VERSION ""

NS_ :

BS_:

BU_: CGM_HS TCM_HS RDCM_HS EPS_HS ECM_HS EBCM_HS BSM_HS BCM_HS
VAL_TABLE_ vt_BooleanValues 1 "true" 0 "false" ;
VAL_TABLE_ A6ERRAlrmReq 2 "Cancel Alarm" 1 "Set Alarm" 0 "No Action" ;
VAL_TABLE_ ValidityStates 1 "Invalid" 0 "Valid" ;

BO_ 3221225472 VECTOR__INDEPENDENT_SIG_MSG: 0 Vector__XXX
 SG_ ChgrSysAdblIndReq : 0|2@0+ (1,0) [0|3] "" Vector__XXX
 SG_ BattVltIRq : 0|2@0+ (1,0) [0|3] "" Vector__XXX

BO_ 808 Temp_Diag_CAN_Resp_HS_328: 8 Vector__XXX
 SG_ DgnInf : 7|64@0+ (1,0) [0|1.84467440737096E+019] ""  CGM_HS

BO_ 568 A_12V_System_Status_HS: 1 BSM_HS
 SG_ a_12VSysVlt : 7|8@0+ (0.125,0) [0|31.875] "volts"  CGM_HS

BO_ 49 Temp_Diag_CAN_Req_HS_031: 8 CGM_HS
 SG_ DgnInf : 7|64@0+ (1,0) [0|1.84467440737096E+019] "" Vector__XXX

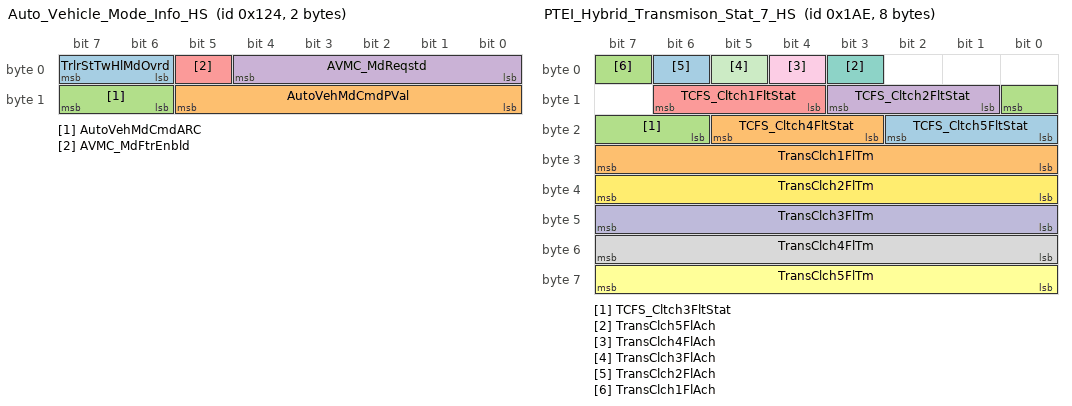
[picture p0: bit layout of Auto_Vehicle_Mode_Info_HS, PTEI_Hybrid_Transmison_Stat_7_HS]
BO_ 292 Auto_Vehicle_Mode_Info_HS: 2 CGM_HS
 SG_ TrlrStTwHlMdOvrd : 7|2@0+ (1,0) [0|3] ""  ECM_HS
 SG_ AutoVehMdCmdPVal : 13|6@0+ (1,0) [0|63] ""  ECM_HS
 SG_ AutoVehMdCmdARC : 15|2@0+ (1,0) [0|3] ""  ECM_HS
 SG_ AVMC_MdReqstd : 4|5@0+ (1,0) [0|31] ""  ECM_HS
 SG_ AVMC_MdFtrEnbld : 5|1@0+ (1,0) [0|1] ""  ECM_HS

BO_ 40 Temp_Diag_CAN_Req_HS_028: 8 CGM_HS
 SG_ DgnInf : 7|64@0+ (1,0) [0|1.84467440737096E+019] "" Vector__XXX

BO_ 1357 UUDT_Resp_From_ONS_HS: 8 CGM_HS
 SG_ DgnInf_HS54D : 7|64@0+ (1,0) [0|1.84467440737096E+019] ""  CGM_HS

BO_ 1613 USDT_Resp_From_ONS_HS: 8 CGM_HS
 SG_ DgnInf : 7|64@0+ (1,0) [0|1.84467440737096E+019] ""  CGM_HS

BO_ 2018 USDT_Req_to_TCM_MTA_MTIO_HS: 8 CGM_HS
 SG_ DgnInf : 7|64@0+ (1,0) [0|1.84467440737096E+019] ""  TCM_HS

BO_ 430 PTEI_Hybrid_Transmison_Stat_7_HS: 8 TCM_HS
 SG_ TCFS_Cltch5FltStat : 18|3@0+ (1,0) [0|7] ""  CGM_HS
 SG_ TCFS_Cltch4FltStat : 21|3@0+ (1,0) [0|7] ""  CGM_HS
 SG_ TCFS_Cltch3FltStat : 8|3@0+ (1,0) [0|7] ""  CGM_HS
 SG_ TCFS_Cltch2FltStat : 11|3@0+ (1,0) [0|7] ""  CGM_HS
 SG_ TCFS_Cltch1FltStat : 14|3@0+ (1,0) [0|7] ""  CGM_HS
 SG_ TransClch5FlTm : 63|8@0+ (0.0125,0) [0|3.1875] "s"  CGM_HS
 SG_ TransClch5FlAch : 3|1@0+ (1,0) [0|1] ""  CGM_HS
 SG_ TransClch4FlTm : 55|8@0+ (0.0125,0) [0|3.1875] "s"  CGM_HS
 SG_ TransClch4FlAch : 4|1@0+ (1,0) [0|1] ""  CGM_HS
 SG_ TransClch3FlTm : 47|8@0+ (0.0125,0) [0|3.1875] "s"  CGM_HS
 SG_ TransClch3FlAch : 5|1@0+ (1,0) [0|1] ""  CGM_HS
 SG_ TransClch2FlTm : 39|8@0+ (0.0125,0) [0|3.1875] "s"  CGM_HS
 SG_ TransClch2FlAch : 6|1@0+ (1,0) [0|1] ""  CGM_HS
 SG_ TransClch1FlTm : 31|8@0+ (0.0125,0) [0|3.1875] "s"  CGM_HS
 SG_ TransClch1FlAch : 7|1@0+ (1,0) [0|1] ""  CGM_HS

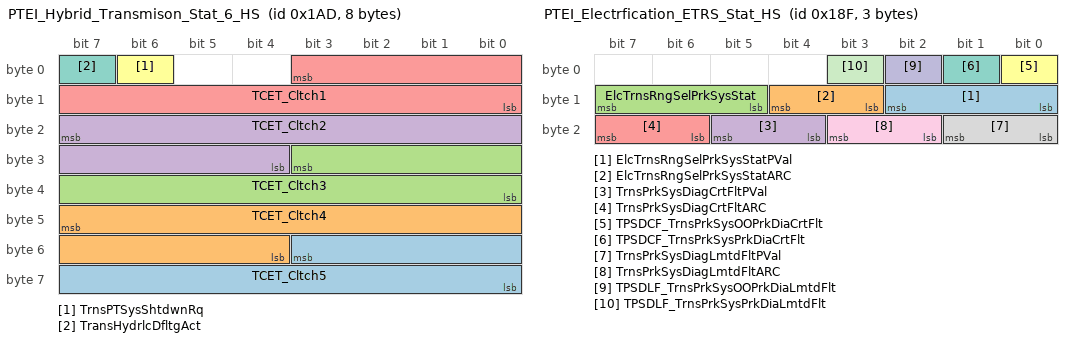
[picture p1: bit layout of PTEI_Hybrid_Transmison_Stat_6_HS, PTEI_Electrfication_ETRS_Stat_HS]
BO_ 429 PTEI_Hybrid_Transmison_Stat_6_HS: 8 TCM_HS
 SG_ TCET_Cltch5 : 51|12@0+ (0.5,-5) [-5|2042.5] "Nm"  CGM_HS
 SG_ TCET_Cltch4 : 47|12@0+ (0.5,-5) [-5|2042.5] "Nm"  CGM_HS
 SG_ TCET_Cltch3 : 27|12@0+ (0.5,-5) [-5|2042.5] "Nm"  CGM_HS
 SG_ TCET_Cltch2 : 23|12@0+ (0.5,-5) [-5|2042.5] "Nm"  CGM_HS
 SG_ TCET_Cltch1 : 3|12@0+ (0.5,-5) [-5|2042.5] "Nm"  CGM_HS
 SG_ TrnsPTSysShtdwnRq : 6|1@0+ (1,0) [0|1] ""  CGM_HS
 SG_ TransHydrlcDfltgAct : 7|1@0+ (1,0) [0|1] ""  CGM_HS

BO_ 399 PTEI_Electrfication_ETRS_Stat_HS: 3 TCM_HS
 SG_ ElcTrnsRngSelPrkSysStatPVal : 10|3@0+ (1,0) [0|7] ""  CGM_HS
 SG_ ElcTrnsRngSelPrkSysStatARC : 12|2@0+ (1,0) [0|3] ""  CGM_HS
 SG_ ElcTrnsRngSelPrkSysStat : 15|3@0+ (1,0) [0|7] ""  CGM_HS
 SG_ TrnsPrkSysDiagCrtFltPVal : 21|2@0+ (1,0) [0|3] ""  CGM_HS
 SG_ TrnsPrkSysDiagCrtFltARC : 23|2@0+ (1,0) [0|3] ""  CGM_HS
 SG_ TPSDCF_TrnsPrkSysOOPrkDiaCrtFlt : 0|1@0+ (1,0) [0|1] ""  CGM_HS
 SG_ TPSDCF_TrnsPrkSysPrkDiaCrtFlt : 1|1@0+ (1,0) [0|1] ""  CGM_HS
 SG_ TrnsPrkSysDiagLmtdFltPVal : 17|2@0+ (1,0) [0|3] ""  CGM_HS
 SG_ TrnsPrkSysDiagLmtdFltARC : 19|2@0+ (1,0) [0|3] ""  CGM_HS
 SG_ TPSDLF_TrnsPrkSysOOPrkDiaLmtdFlt : 2|1@0+ (1,0) [0|1] ""  CGM_HS
 SG_ TPSDLF_TrnsPrkSysPrkDiaLmtdFlt : 3|1@0+ (1,0) [0|1] ""  CGM_HS

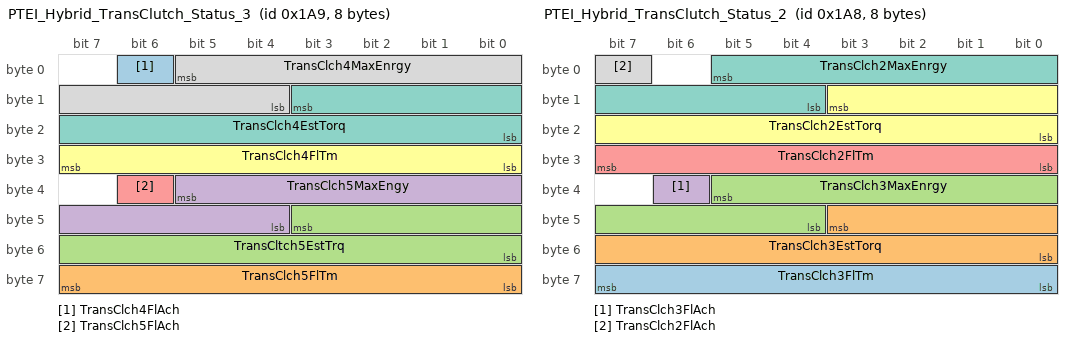
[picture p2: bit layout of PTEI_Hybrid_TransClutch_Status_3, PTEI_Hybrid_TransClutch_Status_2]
BO_ 425 PTEI_Hybrid_TransClutch_Status_3: 8 TCM_HS
 SG_ TransClch4FlAch : 6|1@0+ (1,0) [0|1] ""  CGM_HS
 SG_ TransClch5FlTm : 63|8@0+ (0.0125,0) [0|3.1875] "s"  CGM_HS
 SG_ TransCltch5EstTrq : 43|12@0+ (0.5,-5) [-5|2042.5] "Nm"  CGM_HS
 SG_ TransClch5MaxEngy : 37|10@0+ (50,0) [0|51150] "J"  CGM_HS
 SG_ TransClch5FlAch : 38|1@0+ (1,0) [0|1] ""  CGM_HS
 SG_ TransClch4FlTm : 31|8@0+ (0.0125,0) [0|3.1875] "s"  CGM_HS
 SG_ TransClch4EstTorq : 11|12@0+ (0.5,-5) [-5|2042.5] "Nm"  CGM_HS
 SG_ TransClch4MaxEnrgy : 5|10@0+ (50,0) [0|51150] "J"  CGM_HS

BO_ 424 PTEI_Hybrid_TransClutch_Status_2: 8 TCM_HS
 SG_ TransClch3FlTm : 63|8@0+ (0.0125,0) [0|3.1875] "s"  CGM_HS
 SG_ TransClch3EstTorq : 43|12@0+ (0.5,-5) [-5|2042.5] "Nm"  CGM_HS
 SG_ TransClch3MaxEnrgy : 37|10@0+ (50,0) [0|51150] "J"  CGM_HS
 SG_ TransClch3FlAch : 38|1@0+ (1,0) [0|1] ""  CGM_HS
 SG_ TransClch2FlTm : 31|8@0+ (0.0125,0) [0|3.1875] "s"  CGM_HS
 SG_ TransClch2EstTorq : 11|12@0+ (0.5,-5) [-5|2042.5] "Nm"  CGM_HS
 SG_ TransClch2MaxEnrgy : 5|10@0+ (50,0) [0|51150] "J"  CGM_HS
 SG_ TransClch2FlAch : 7|1@0+ (1,0) [0|1] ""  CGM_HS

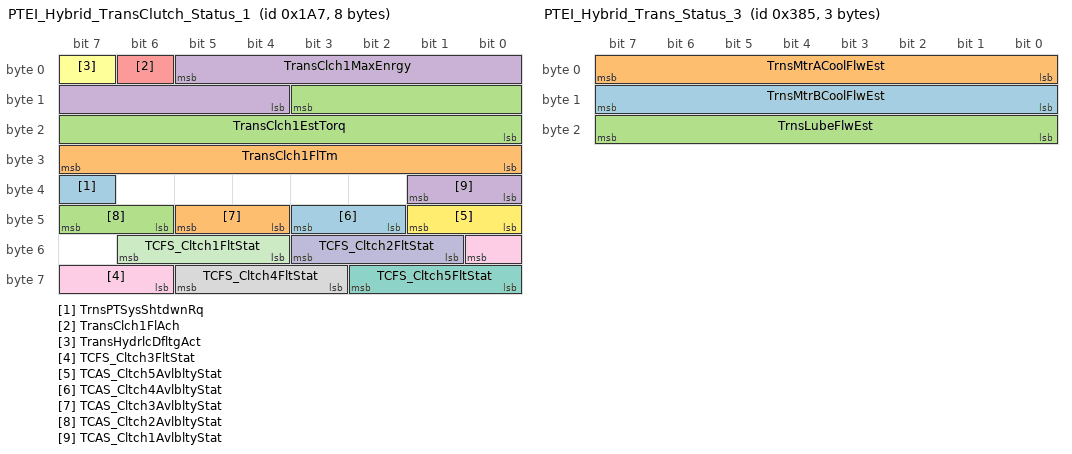
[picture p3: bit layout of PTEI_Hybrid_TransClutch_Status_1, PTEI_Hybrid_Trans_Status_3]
BO_ 423 PTEI_Hybrid_TransClutch_Status_1: 8 TCM_HS
 SG_ TrnsPTSysShtdwnRq : 39|1@0+ (1,0) [0|1] ""  CGM_HS
 SG_ TransClch1FlTm : 31|8@0+ (0.0125,0) [0|3.1875] "s"  CGM_HS
 SG_ TransClch1EstTorq : 11|12@0+ (0.5,-5) [-5|2042.5] "Nm"  CGM_HS
 SG_ TransClch1MaxEnrgy : 5|10@0+ (50,0) [0|51150] "J"  CGM_HS
 SG_ TransClch1FlAch : 6|1@0+ (1,0) [0|1] ""  CGM_HS
 SG_ TransHydrlcDfltgAct : 7|1@0+ (1,0) [0|1] ""  CGM_HS
 SG_ TCFS_Cltch5FltStat : 58|3@0+ (1,0) [0|7] ""  CGM_HS
 SG_ TCFS_Cltch4FltStat : 61|3@0+ (1,0) [0|7] ""  CGM_HS
 SG_ TCFS_Cltch3FltStat : 48|3@0+ (1,0) [0|7] ""  CGM_HS
 SG_ TCFS_Cltch2FltStat : 51|3@0+ (1,0) [0|7] ""  CGM_HS
 SG_ TCFS_Cltch1FltStat : 54|3@0+ (1,0) [0|7] ""  CGM_HS
 SG_ TCAS_Cltch5AvlbltyStat : 41|2@0+ (1,0) [0|3] ""  CGM_HS
 SG_ TCAS_Cltch4AvlbltyStat : 43|2@0+ (1,0) [0|3] ""  CGM_HS
 SG_ TCAS_Cltch3AvlbltyStat : 45|2@0+ (1,0) [0|3] ""  CGM_HS
 SG_ TCAS_Cltch2AvlbltyStat : 47|2@0+ (1,0) [0|3] ""  CGM_HS
 SG_ TCAS_Cltch1AvlbltyStat : 33|2@0+ (1,0) [0|3] ""  CGM_HS

BO_ 901 PTEI_Hybrid_Trans_Status_3: 3 TCM_HS
 SG_ TrnsMtrBCoolFlwEst : 15|8@0+ (0.05,0) [0|12.75] "l/min"  CGM_HS
 SG_ TrnsMtrACoolFlwEst : 7|8@0+ (0.05,0) [0|12.75] "l/min"  CGM_HS
 SG_ TrnsLubeFlwEst : 23|8@0+ (0.0625,0) [0|15.9375] "l/min"  CGM_HS

BO_ 1919 DTC_Triggered_77F: 7 TCM_HS
 SG_ DTCI_DTCFaultType_77F : 55|8@0+ (1,0) [0|255] ""  CGM_HS
 SG_ DTCI_CodeSupported_77F : 40|1@0+ (1,0) [0|1] ""  CGM_HS
 SG_ DTCI_CurrentStatus_77F : 41|1@0+ (1,0) [0|1] ""  CGM_HS
 SG_ DTCI_TstNPsdCdClrdSt_77F : 42|1@0+ (1,0) [0|1] ""  CGM_HS
 SG_ DTCI_TstFldCdClrdStat_77F : 43|1@0+ (1,0) [0|1] ""  CGM_HS
 SG_ DTCI_HistStat_77F : 44|1@0+ (1,0) [0|1] ""  CGM_HS
 SG_ DTCI_TstNPsdPwrUpSt_77F : 45|1@0+ (1,0) [0|1] ""  CGM_HS
 SG_ DTCI_TstFldPwrUpSt_77F : 46|1@0+ (1,0) [0|1] ""  CGM_HS
 SG_ DTCI_WrnIndRqdSt_77F : 47|1@0+ (1,0) [0|1] ""  CGM_HS
 SG_ DTCI_DTCFailType_77F : 39|8@0+ (1,0) [0|255] ""  CGM_HS
 SG_ DTCI_DTCNumber_77F : 23|16@0+ (1,0) [0|65535] ""  CGM_HS
 SG_ DTCI_DTCSource_77F : 15|8@0+ (1,0) [0|255] ""  CGM_HS
 SG_ DTCI_DTCTriggered_77F : 0|1@0+ (1,0) [0|1] ""  CGM_HS
 SG_ DTCIUnused7_77F : 1|1@0+ (1,0) [0|1] ""  CGM_HS
 SG_ DTCIUnused6_77F : 2|1@0+ (1,0) [0|1] ""  CGM_HS
 SG_ DTCIUnused5_77F : 3|1@0+ (1,0) [0|1] ""  CGM_HS
 SG_ DTCIUnused4_77F : 4|1@0+ (1,0) [0|1] ""  CGM_HS
 SG_ DTCIUnused3_77F : 5|1@0+ (1,0) [0|1] ""  CGM_HS
 SG_ DTCIUnused2_77F : 6|1@0+ (1,0) [0|1] ""  CGM_HS
 SG_ DTCIUnused1_77F : 7|1@0+ (1,0) [0|1] ""  CGM_HS

BO_ 2026 USDT_Resp_From_TCM_MTA_MTIO_HS: 8 TCM_HS
 SG_ DgnInf : 7|64@0+ (1,0) [0|1.84467440737096E+019] ""  CGM_HS

BO_ 1514 UUDT_Resp_From_TCM_MTA_MTIO_HS: 8 TCM_HS
 SG_ DgnInf : 7|64@0+ (1,0) [0|1.84467440737096E+019] ""  CGM_HS

BO_ 1801 XCP_CommandReceiveObject4_HS: 8 CGM_HS
 SG_ DgnInf : 7|64@0+ (1,0) [0|1.84467440737096E+019] ""  RDCM_HS

BO_ 591 USDT_Req_to_RDCM_HS: 8 CGM_HS
 SG_ DgnInf : 7|64@0+ (1,0) [0|1.84467440737096E+019] ""  RDCM_HS

BO_ 1799 XCP_DataTransmissionObject4_HS: 8 RDCM_HS
 SG_ DgnInf : 7|64@0+ (1,0) [0|1.84467440737096E+019] ""  CGM_HS

BO_ 1359 UUDT_Resp_From_RDCM_HS: 8 RDCM_HS
 SG_ DgnInf_HS54F : 7|64@0+ (1,0) [0|1.84467440737096E+019] ""  CGM_HS

BO_ 1914 DTC_Triggered_77A: 7 RDCM_HS
 SG_ DTCI_DTCFaultType_77A : 55|8@0+ (1,0) [0|255] ""  CGM_HS
 SG_ DTCI_CodeSupported_77A : 40|1@0+ (1,0) [0|1] ""  CGM_HS
 SG_ DTCI_CurrentStatus_77A : 41|1@0+ (1,0) [0|1] ""  CGM_HS
 SG_ DTCI_TstNPsdCdClrdSt_77A : 42|1@0+ (1,0) [0|1] ""  CGM_HS
 SG_ DTCI_TstFldCdClrdStat_77A : 43|1@0+ (1,0) [0|1] ""  CGM_HS
 SG_ DTCI_HistStat_77A : 44|1@0+ (1,0) [0|1] ""  CGM_HS
 SG_ DTCI_TstNPsdPwrUpSt_77A : 45|1@0+ (1,0) [0|1] ""  CGM_HS
 SG_ DTCI_TstFldPwrUpSt_77A : 46|1@0+ (1,0) [0|1] ""  CGM_HS
 SG_ DTCI_WrnIndRqdSt_77A : 47|1@0+ (1,0) [0|1] ""  CGM_HS
 SG_ DTCI_DTCFailType_77A : 39|8@0+ (1,0) [0|255] ""  CGM_HS
 SG_ DTCI_DTCNumber_77A : 23|16@0+ (1,0) [0|65535] ""  CGM_HS
 SG_ DTCI_DTCSource_77A : 15|8@0+ (1,0) [0|255] ""  CGM_HS
 SG_ DTCI_DTCTriggered_77A : 0|1@0+ (1,0) [0|1] ""  CGM_HS
 SG_ DTCIUnused7_77A : 1|1@0+ (1,0) [0|1] ""  CGM_HS
 SG_ DTCIUnused6_77A : 2|1@0+ (1,0) [0|1] ""  CGM_HS
 SG_ DTCIUnused5_77A : 3|1@0+ (1,0) [0|1] ""  CGM_HS
 SG_ DTCIUnused4_77A : 4|1@0+ (1,0) [0|1] ""  CGM_HS
 SG_ DTCIUnused3_77A : 5|1@0+ (1,0) [0|1] ""  CGM_HS
 SG_ DTCIUnused2_77A : 6|1@0+ (1,0) [0|1] ""  CGM_HS
 SG_ DTCIUnused1_77A : 7|1@0+ (1,0) [0|1] ""  CGM_HS

BO_ 1615 USDT_Resp_From_RDCM_HS: 8 RDCM_HS
 SG_ DgnInf : 7|64@0+ (1,0) [0|1.84467440737096E+019] ""  CGM_HS

BO_ 1800 XCP_CommandReceiveObject2_HS: 8 CGM_HS
 SG_ DgnInf : 7|64@0+ (1,0) [0|1.84467440737096E+019] ""  EPS_HS

BO_ 1810 XCP_CommandReceiveObject1_HS: 8 CGM_HS
 SG_ DgnInf : 7|64@0+ (1,0) [0|1.84467440737096E+019] ""  EPS_HS

BO_ 578 USDT_Req_to_EHPS_EPS_HS: 8 CGM_HS
 SG_ DgnInf : 7|64@0+ (1,0) [0|1.84467440737096E+019] ""  EPS_HS

BO_ 1798 XCP_DataTransmissionObject2_HS: 8 EPS_HS
 SG_ DgnInf : 7|64@0+ (1,0) [0|1.84467440737096E+019] ""  CGM_HS

BO_ 1808 XCP_DataTransmissionObject1_HS: 8 EPS_HS
 SG_ DgnInf : 7|64@0+ (1,0) [0|1.84467440737096E+019] ""  CGM_HS

BO_ 1912 DTC_Triggered_778: 7 EPS_HS
 SG_ DTCI_DTCFaultType_778 : 55|8@0+ (1,0) [0|255] ""  CGM_HS
 SG_ DTCI_CodeSupported_778 : 40|1@0+ (1,0) [0|1] ""  CGM_HS
 SG_ DTCI_CurrentStatus_778 : 41|1@0+ (1,0) [0|1] ""  CGM_HS
 SG_ DTCI_TstNPsdCdClrdSt_778 : 42|1@0+ (1,0) [0|1] ""  CGM_HS
 SG_ DTCI_TstFldCdClrdStat_778 : 43|1@0+ (1,0) [0|1] ""  CGM_HS
 SG_ DTCI_HistStat_778 : 44|1@0+ (1,0) [0|1] ""  CGM_HS
 SG_ DTCI_TstNPsdPwrUpSt_778 : 45|1@0+ (1,0) [0|1] ""  CGM_HS
 SG_ DTCI_TstFldPwrUpSt_778 : 46|1@0+ (1,0) [0|1] ""  CGM_HS
 SG_ DTCI_WrnIndRqdSt_778 : 47|1@0+ (1,0) [0|1] ""  CGM_HS
 SG_ DTCI_DTCFailType_778 : 39|8@0+ (1,0) [0|255] ""  CGM_HS
 SG_ DTCI_DTCNumber_778 : 23|16@0+ (1,0) [0|65535] ""  CGM_HS
 SG_ DTCI_DTCSource_778 : 15|8@0+ (1,0) [0|255] ""  CGM_HS
 SG_ DTCI_DTCTriggered_778 : 0|1@0+ (1,0) [0|1] ""  CGM_HS
 SG_ DTCIUnused7_778 : 1|1@0+ (1,0) [0|1] ""  CGM_HS
 SG_ DTCIUnused6_778 : 2|1@0+ (1,0) [0|1] ""  CGM_HS
 SG_ DTCIUnused5_778 : 3|1@0+ (1,0) [0|1] ""  CGM_HS
 SG_ DTCIUnused4_778 : 4|1@0+ (1,0) [0|1] ""  CGM_HS
 SG_ DTCIUnused3_778 : 5|1@0+ (1,0) [0|1] ""  CGM_HS
 SG_ DTCIUnused2_778 : 6|1@0+ (1,0) [0|1] ""  CGM_HS
 SG_ DTCIUnused1_778 : 7|1@0+ (1,0) [0|1] ""  CGM_HS

BO_ 1346 UUDT_Resp_From_EHPS_EPS_HS: 8 EPS_HS
 SG_ DgnInf_HS542 : 7|64@0+ (1,0) [0|1.84467440737096E+019] ""  CGM_HS

BO_ 1602 USDT_Resp_From_EHPS_EPS_HS: 8 EPS_HS
 SG_ DgnInf : 7|64@0+ (1,0) [0|1.84467440737096E+019] ""  CGM_HS

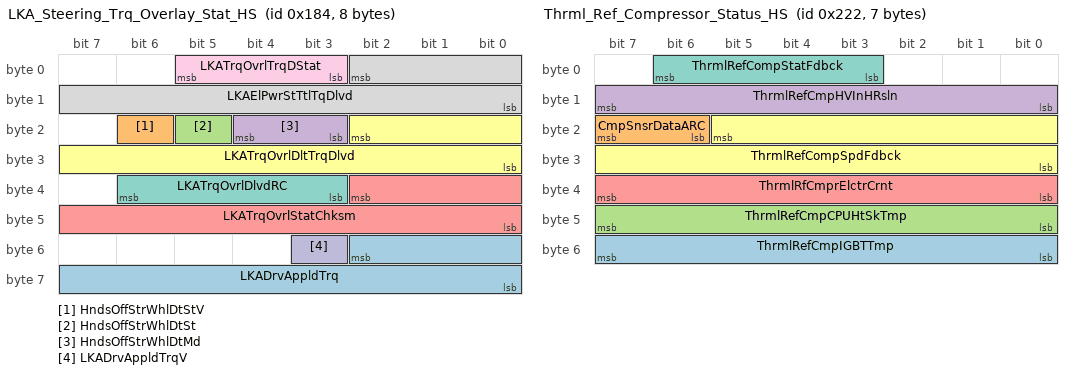
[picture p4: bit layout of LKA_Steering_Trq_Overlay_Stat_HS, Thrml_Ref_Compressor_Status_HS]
BO_ 388 LKA_Steering_Trq_Overlay_Stat_HS: 8 EPS_HS
 SG_ LKADrvAppldTrq : 50|11@0- (0.01,0) [-10.24|10.23] "Nm"  CGM_HS
 SG_ HndsOffStrWhlDtStV : 22|1@0+ (1,0) [0|1] ""  CGM_HS
 SG_ HndsOffStrWhlDtSt : 21|1@0+ (1,0) [0|1] ""  CGM_HS
 SG_ HndsOffStrWhlDtMd : 20|2@0+ (1,0) [0|3] ""  CGM_HS
 SG_ LKATrqOvrlStatChksm : 34|11@0+ (1,0) [0|2047] ""  CGM_HS
 SG_ LKATrqOvrlDltTrqDlvd : 18|11@0- (0.01,0) [-10.24|10.23] "Nm"  CGM_HS
 SG_ LKATrqOvrlDlvdRC : 38|4@0+ (1,0) [0|15] ""  CGM_HS
 SG_ LKAElPwrStTtlTqDlvd : 2|11@0- (0.01,0) [-10.24|10.23] "Nm"  CGM_HS
 SG_ LKATrqOvrlTrqDStat : 5|3@0+ (1,0) [0|7] ""  CGM_HS
 SG_ LKADrvAppldTrqV : 51|1@0+ (1,0) [0|1] ""  CGM_HS

BO_ 1611 USDT_Resp_From_EOCM_FCM_HS: 8 CGM_HS
 SG_ DgnInf : 7|64@0+ (1,0) [0|1.84467440737096E+019] ""  CGM_HS

BO_ 546 Thrml_Ref_Compressor_Status_HS: 7 Vector__XXX
 SG_ ThrmlRefCmpIGBTTmp : 55|8@0+ (1,-40) [-40|215] "deg C"  BSM_HS
 SG_ CmpSnsrDataARC : 23|2@0+ (1,0) [0|3] "N/A"  BSM_HS
 SG_ ThrmlRefCmpCPUHtSkTmp : 47|8@0+ (1,-40) [-40|215] "deg C"  BSM_HS
 SG_ ThrmlRefCmpHVInHRsln : 15|8@0+ (2.5,0) [0|637.5] "V"  BSM_HS
 SG_ ThrmlRfCmprElctrCrnt : 39|8@0+ (0.2,0) [0|51] "A"  BSM_HS
 SG_ ThrmlRefCompSpdFdbck : 21|14@0+ (1,0) [0|16383] "rpm"  BSM_HS
 SG_ ThrmlRefCompStatFdbck : 6|4@0+ (1,0) [0|15] " "  BSM_HS

BO_ 390 PTEI_Hybrid_Status_1: 7 Vector__XXX
 SG_ HybCrpCstCrvRq : 43|3@0+ (1,0) [0|7] "" Vector__XXX
 SG_ TransFldPmpMtrDrtd : 26|1@0+ (1,0) [0|1] "" Vector__XXX
 SG_ RdHVInvRatVltV : 7|1@0+ (1,0) [0|1] ""  BSM_HS
 SG_ RdHVInvRatVlt : 40|9@0+ (1,0) [0|511] "volts"  BSM_HS
 SG_ EngActDmpgDsblReq : 27|1@0+ (1,0) [0|1] "" Vector__XXX
 SG_ HybRdcdTrqCapMd1Cmnd : 5|1@0+ (1,0) [0|1] "" Vector__XXX
 SG_ HybExtndDcFuelCORq : 31|1@0+ (1,0) [0|1] "" Vector__XXX
 SG_ EstMtrPwrLossV : 30|1@0+ (1,0) [0|1] "" Vector__XXX
 SG_ EstMtrPwrLoss : 39|8@0+ (0.25,0) [0|63.75] "kW" Vector__XXX
 SG_ HybCmmFailRdPwrCmd : 4|1@0+ (1,0) [0|1] "" Vector__XXX
 SG_ HybCmmdEngTrqLmtd : 23|8@0+ (0.75,-90) [-90|101.25] "Nm" Vector__XXX
 SG_ HybACCompRq : 29|2@0+ (1,0) [0|3] "" Vector__XXX
 SG_ HybGrdBrkgAct : 25|1@0+ (1,0) [0|1] "" Vector__XXX
 SG_ HESSI_EngStrtTyp : 11|4@0+ (1,0) [0|15] ""  BSM_HS
 SG_ HESSI_EngStrtStpMd : 15|4@0+ (1,0) [0|15] ""  BSM_HS
 SG_ HybCrnkAbrtd : 0|1@0+ (1,0) [0|1] "" Vector__XXX
 SG_ CnvntlEngStrtEnbld : 1|1@0+ (1,0) [0|1] "" Vector__XXX
 SG_ HybDFCOReq : 6|1@0+ (1,0) [0|1] "" Vector__XXX
 SG_ RdPTHVCntrReq : 3|2@0+ (1,0) [0|3] ""  BSM_HS

BO_ 1355 UUDT_Resp_From_EOCM_FCM_HS: 8 CGM_HS
 SG_ DgnInf_HS54B : 7|64@0+ (1,0) [0|1.84467440737096E+019] ""  CGM_HS

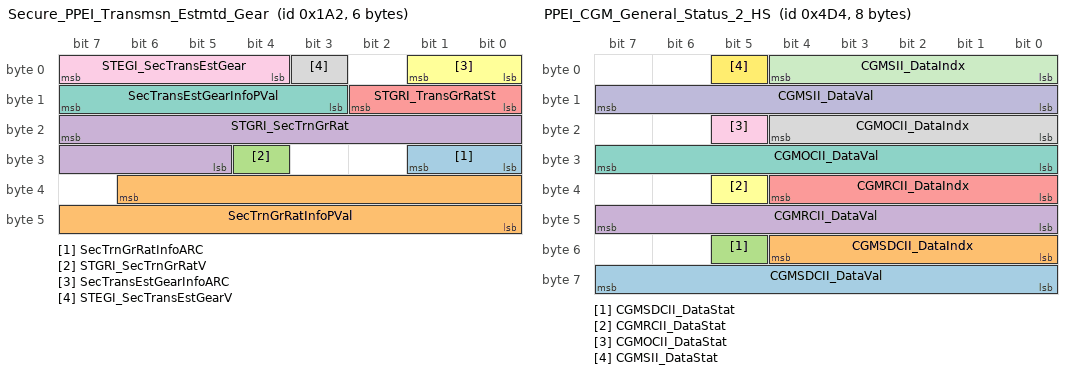
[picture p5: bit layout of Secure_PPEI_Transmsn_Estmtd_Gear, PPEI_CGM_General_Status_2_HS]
BO_ 418 Secure_PPEI_Transmsn_Estmtd_Gear: 6 TCM_HS
 SG_ SecTrnGrRatInfoARC : 25|2@0+ (1,0) [0|3] ""  CGM_HS,ECM_HS
 SG_ SecTrnGrRatInfoPVal : 38|15@0+ (1,0) [0|32767] ""  CGM_HS,ECM_HS
 SG_ STGRI_SecTrnGrRatV : 28|1@0+ (1,0) [0|1] ""  CGM_HS,ECM_HS
 SG_ STGRI_SecTrnGrRat : 23|11@0+ (0.003906,0) [0|8] ""  CGM_HS,ECM_HS
 SG_ STGRI_TransGrRatSt : 10|3@0+ (1,0) [0|7] ""  CGM_HS,ECM_HS
 SG_ SecTransEstGearInfoARC : 1|2@0+ (1,0) [0|3] ""  CGM_HS,ECM_HS
 SG_ SecTransEstGearInfoPVal : 15|5@0+ (1,0) [0|31] ""  CGM_HS,ECM_HS
 SG_ STEGI_SecTransEstGearV : 3|1@0+ (1,0) [0|1] ""  CGM_HS,ECM_HS
 SG_ STEGI_SecTransEstGear : 7|4@0+ (1,0) [0|15] ""  CGM_HS,ECM_HS

BO_ 1236 PPEI_CGM_General_Status_2_HS: 8 CGM_HS
 SG_ CGMSDCII_DataVal : 63|8@0+ (1,0) [0|255] ""  ECM_HS
 SG_ CGMSDCII_DataIndx : 52|5@0+ (1,0) [0|31] ""  ECM_HS
 SG_ CGMSDCII_DataStat : 53|1@0+ (1,0) [0|1] ""  ECM_HS
 SG_ CGMRCII_DataVal : 47|8@0+ (1,0) [0|255] ""  ECM_HS
 SG_ CGMRCII_DataIndx : 36|5@0+ (1,0) [0|31] ""  ECM_HS
 SG_ CGMRCII_DataStat : 37|1@0+ (1,0) [0|1] ""  ECM_HS
 SG_ CGMOCII_DataVal : 31|8@0+ (1,0) [0|255] ""  ECM_HS
 SG_ CGMOCII_DataIndx : 20|5@0+ (1,0) [0|31] ""  ECM_HS
 SG_ CGMOCII_DataStat : 21|1@0+ (1,0) [0|1] ""  ECM_HS
 SG_ CGMSII_DataVal : 15|8@0+ (1,0) [0|255] ""  ECM_HS
 SG_ CGMSII_DataIndx : 4|5@0+ (1,0) [0|31] ""  ECM_HS
 SG_ CGMSII_DataStat : 5|1@0+ (1,0) [0|1] ""  ECM_HS

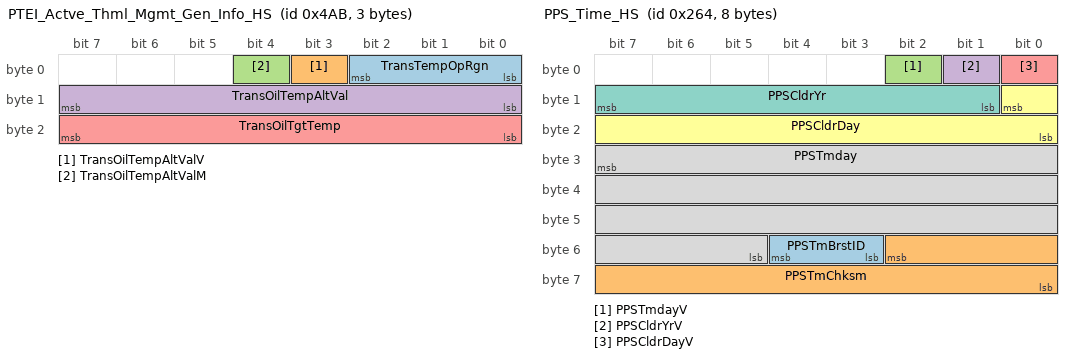
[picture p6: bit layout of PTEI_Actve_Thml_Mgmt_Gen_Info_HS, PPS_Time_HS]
BO_ 1195 PTEI_Actve_Thml_Mgmt_Gen_Info_HS: 3 TCM_HS
 SG_ TransTempOpRgn : 2|3@0+ (1,0) [0|7] ""  CGM_HS,ECM_HS
 SG_ TransOilTempAltValV : 3|1@0+ (1,0) [0|1] ""  CGM_HS,ECM_HS
 SG_ TransOilTempAltValM : 4|1@0+ (1,0) [0|1] ""  CGM_HS,ECM_HS
 SG_ TransOilTempAltVal : 15|8@0+ (1,-40) [-40|215] "deg C"  CGM_HS,ECM_HS
 SG_ TransOilTgtTemp : 23|8@0+ (1,-40) [-40|215] "deg C"  CGM_HS,ECM_HS

BO_ 612 PPS_Time_HS: 8 CGM_HS
 SG_ PPSTmBrstID : 52|2@0+ (1,0) [0|3] "" Vector__XXX
 SG_ PPSTmChksm : 50|11@0+ (1,0) [0|2047] "" Vector__XXX
 SG_ PPSTmdayV : 2|1@0+ (1,0) [0|1] ""  ECM_HS
 SG_ PPSCldrYrV : 1|1@0+ (1,0) [0|1] ""  ECM_HS
 SG_ PPSCldrDayV : 0|1@0+ (1,0) [0|1] ""  ECM_HS
 SG_ PPSCldrDay : 8|9@0+ (1,0) [0|511] ""  ECM_HS
 SG_ PPSCldrYr : 15|7@0+ (1,2014) [2014|2141] ""  ECM_HS
 SG_ PPSTmday : 31|27@0+ (1,0) [0|134217727] "ms"  ECM_HS

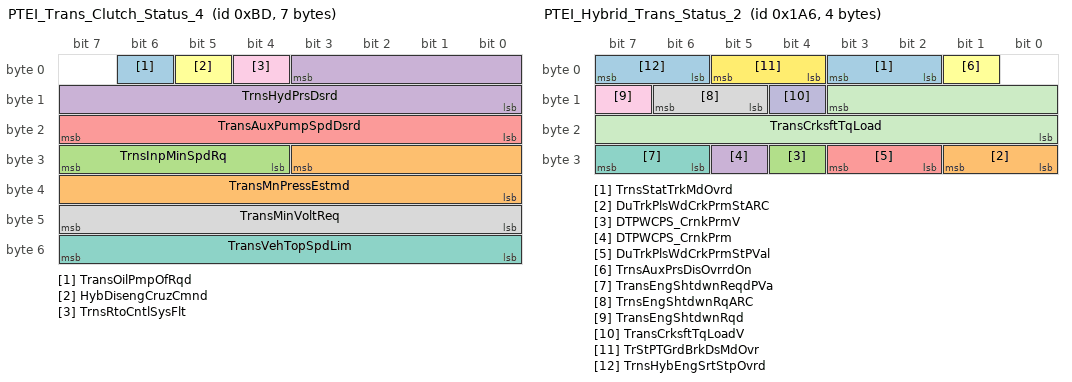
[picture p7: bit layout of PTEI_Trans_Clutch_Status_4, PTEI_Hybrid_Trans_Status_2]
BO_ 189 PTEI_Trans_Clutch_Status_4: 7 TCM_HS
 SG_ TransOilPmpOfRqd : 6|1@0+ (1,0) [0|1] ""  CGM_HS
 SG_ TransMnPressEstmd : 27|12@0+ (0.5,0) [0|2047.5] "kPa"  CGM_HS
 SG_ TrnsInpMinSpdRq : 31|4@0+ (1,0) [0|15] ""  CGM_HS
 SG_ TrnsHydPrsDsrd : 3|12@0+ (0.5,0) [0|2047.5] "kPa"  CGM_HS
 SG_ TransAuxPumpSpdDsrd : 23|8@0+ (0.392157,0) [0|100.000035] "%"  CGM_HS
 SG_ HybDisengCruzCmnd : 5|1@0+ (1,0) [0|1] ""  CGM_HS,ECM_HS
 SG_ TransVehTopSpdLim : 55|8@0+ (2,0) [0|510] "km / h"  CGM_HS,ECM_HS
 SG_ TransMinVoltReq : 47|8@0+ (0.07843,0) [0|19.99965] "volts"  CGM_HS,ECM_HS
 SG_ TrnsRtoCntlSysFlt : 4|1@0+ (1,0) [0|1] ""  CGM_HS,ECM_HS

BO_ 422 PTEI_Hybrid_Trans_Status_2: 4 TCM_HS
 SG_ TrnsStatTrkMdOvrd : 3|2@0+ (1,0) [0|3] ""  ECM_HS,CGM_HS
 SG_ DuTrkPlsWdCrkPrmStARC : 25|2@0+ (1,0) [0|3] ""  ECM_HS,CGM_HS
 SG_ DTPWCPS_CrnkPrmV : 28|1@0+ (1,0) [0|1] ""  ECM_HS,CGM_HS
 SG_ DTPWCPS_CrnkPrm : 29|1@0+ (1,0) [0|1] ""  ECM_HS,CGM_HS
 SG_ DuTrkPlsWdCrkPrmStPVal : 27|2@0+ (1,0) [0|3] ""  ECM_HS,CGM_HS
 SG_ TrnsAuxPrsDisOvrrdOn : 1|1@0+ (1,0) [0|1] ""  ECM_HS,CGM_HS
 SG_ TransEngShtdwnReqdPVa : 31|2@0+ (1,0) [0|3] ""  ECM_HS,CGM_HS
 SG_ TrnsEngShtdwnRqARC : 14|2@0+ (1,0) [0|3] ""  ECM_HS,CGM_HS
 SG_ TransEngShtdwnRqd : 15|1@0+ (1,0) [0|1] ""  ECM_HS,CGM_HS
 SG_ TransCrksftTqLoadV : 12|1@0+ (1,0) [0|1] ""  ECM_HS,CGM_HS
 SG_ TransCrksftTqLoad : 11|12@0+ (0.5,-848) [-848|1199.5] "Nm"  ECM_HS,CGM_HS
 SG_ TrStPTGrdBrkDsMdOvr : 5|2@0+ (1,0) [0|3] ""  ECM_HS,CGM_HS
 SG_ TrnsHybEngSrtStpOvrd : 7|2@0+ (1,0) [0|3] ""  ECM_HS,CGM_HS

BO_ 1189 PTEI_Trans_General_Status_3_HS: 1 TCM_HS
 SG_ TransAirFlwPrcntRq : 7|6@0+ (1.58730158730159,0) [0|100] "%"  ECM_HS,CGM_HS

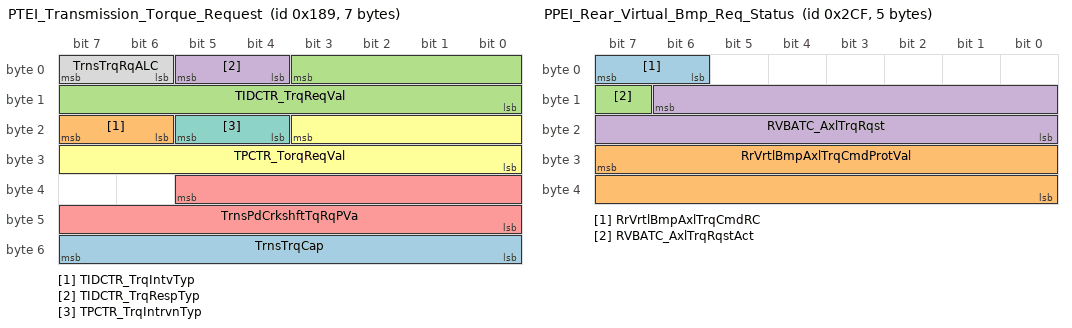
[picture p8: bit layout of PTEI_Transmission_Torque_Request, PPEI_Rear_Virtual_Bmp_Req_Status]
BO_ 393 PTEI_Transmission_Torque_Request: 7 TCM_HS
 SG_ TrnsTrqCap : 55|8@0+ (4,0) [0|1020] "Nm"  CGM_HS,ECM_HS
 SG_ TIDCTR_TrqIntvTyp : 23|2@0+ (1,0) [0|3] ""  CGM_HS,ECM_HS
 SG_ TIDCTR_TrqReqVal : 3|12@0+ (0.5,-848) [-848|1199.5] "Nm"  CGM_HS,ECM_HS
 SG_ TIDCTR_TrqRespTyp : 5|2@0+ (1,0) [0|3] ""  CGM_HS,ECM_HS
 SG_ TrnsPdCrkshftTqRqPVa : 37|14@0+ (1,0) [0|16383] ""  CGM_HS,ECM_HS
 SG_ TPCTR_TorqReqVal : 19|12@0+ (0.5,-848) [-848|1199.5] "Nm"  CGM_HS,ECM_HS
 SG_ TPCTR_TrqIntrvnTyp : 21|2@0+ (1,0) [0|3] ""  CGM_HS,ECM_HS
 SG_ TrnsTrqRqALC : 7|2@0+ (1,0) [0|3] ""  CGM_HS,ECM_HS

BO_ 719 PPEI_Rear_Virtual_Bmp_Req_Status: 5 CGM_HS
 SG_ RrVrtlBmpAxlTrqCmdRC : 7|2@0+ (1,0) [0|3] ""  ECM_HS
 SG_ RrVrtlBmpAxlTrqCmdProtVal : 31|16@0+ (1,0) [0|65535] ""  ECM_HS
 SG_ RVBATC_AxlTrqRqstAct : 15|1@0+ (1,0) [0|1] ""  ECM_HS
 SG_ RVBATC_AxlTrqRqst : 14|15@0+ (2,-22534) [-22534|43000] "NM"  ECM_HS

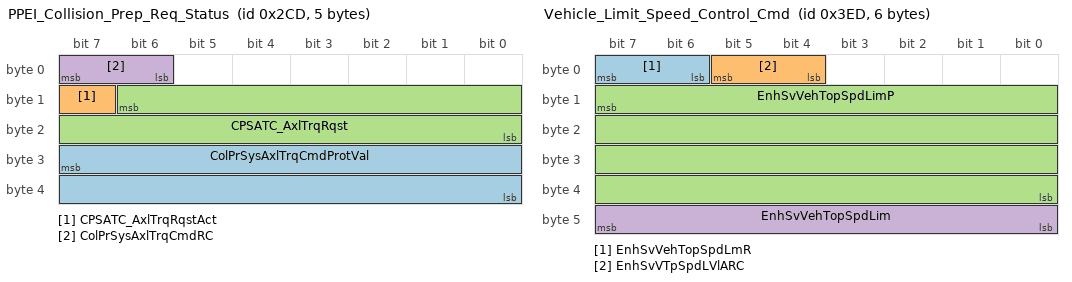
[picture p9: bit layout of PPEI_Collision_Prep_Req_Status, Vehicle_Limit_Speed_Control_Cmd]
BO_ 717 PPEI_Collision_Prep_Req_Status: 5 CGM_HS
 SG_ ColPrSysAxlTrqCmdProtVal : 31|16@0+ (1,0) [0|65535] ""  TCM_HS,ECM_HS
 SG_ CPSATC_AxlTrqRqstAct : 15|1@0+ (1,0) [0|1] ""  TCM_HS,ECM_HS
 SG_ CPSATC_AxlTrqRqst : 14|15@0+ (2,-22534) [-22534|43000] "NM"  TCM_HS,ECM_HS
 SG_ ColPrSysAxlTrqCmdRC : 7|2@0+ (1,0) [0|3] ""  TCM_HS,ECM_HS

BO_ 1005 Vehicle_Limit_Speed_Control_Cmd: 6 CGM_HS
 SG_ EnhSvVehTopSpdLmR : 7|2@0+ (1,0) [0|3] ""  ECM_HS
 SG_ EnhSvVTpSpdLVlARC : 5|2@0+ (1,0) [0|3] ""  ECM_HS
 SG_ EnhSvVehTopSpdLimP : 15|32@0+ (1,0) [0|4294967295] ""  ECM_HS
 SG_ EnhSvVehTopSpdLim : 47|8@0+ (2,0) [0|510] "km / h"  ECM_HS

BO_ 431 PTEI_Trans_General_Status_2: 8 TCM_HS
 SG_ TrnsInpCltchStatV : 39|1@0+ (1,0) [0|1] ""  CGM_HS,ECM_HS
 SG_ TransCrnkPermsnStatV : 23|1@0+ (1,0) [0|1] ""  CGM_HS,ECM_HS
 SG_ TransVehTopSpdLim : 63|8@0+ (2,0) [0|510] "km / h"  CGM_HS,ECM_HS
 SG_ TransMinVoltReq : 55|8@0+ (0.07843,0) [0|19.99965] "volts"  CGM_HS,ECM_HS
 SG_ TDslPrtFltrIdlRgtnMdAtv : 6|1@0+ (1,0) [0|1] ""  CGM_HS,ECM_HS
 SG_ DrvlneTrqStabStat : 38|3@0+ (1,0) [0|7] ""  CGM_HS,ECM_HS
 SG_ TrnsTrqCnvCltCmdMdF : 19|1@0+ (1,0) [0|1] ""  CGM_HS,ECM_HS
 SG_ AutoTransGrSftDirectFl : 16|1@0+ (1,0) [0|1] ""  CGM_HS,ECM_HS
 SG_ AutoTransGrSftDirect : 18|2@0+ (1,0) [0|3] ""  CGM_HS,ECM_HS
 SG_ TrnsTrqCnvCltCmndMd : 22|3@0+ (1,0) [0|7] ""  CGM_HS,ECM_HS
 SG_ TrnsTrqCnvCltDsrSlp : 35|12@0- (1,0) [-2048|2047] "rpm"  CGM_HS,ECM_HS
 SG_ TrnsStWntrMdOvrd : 25|2@0+ (1,0) [0|3] ""  CGM_HS,ECM_HS
 SG_ TrnsStTwHaulMdOvrd : 27|2@0+ (1,0) [0|3] ""  CGM_HS,ECM_HS
 SG_ TrnsStSprtMdOvrd : 29|2@0+ (1,0) [0|3] ""  CGM_HS,ECM_HS
 SG_ TrnsStEconMdOvrd : 31|2@0+ (1,0) [0|3] ""  CGM_HS,ECM_HS
 SG_ TrnsInpCltchStat : 2|3@0+ (1,0) [0|7] ""  CGM_HS,ECM_HS
 SG_ TrnsAntcptdCrpTrqRRnV : 7|1@0+ (1,0) [0|1] ""  CGM_HS,ECM_HS
 SG_ TrnsAntcptdCrpTrqRRn : 15|8@0+ (0.5,0) [0|127.5] "Nm"  CGM_HS,ECM_HS
 SG_ TrnCltAdpAtv : 3|1@0+ (1,0) [0|1] ""  CGM_HS,ECM_HS
 SG_ TransCrnkPermsnStat : 5|1@0+ (1,0) [0|1] ""  CGM_HS,ECM_HS
 SG_ WrmUpShftPtrn : 4|1@0+ (1,0) [0|1] ""  CGM_HS,ECM_HS

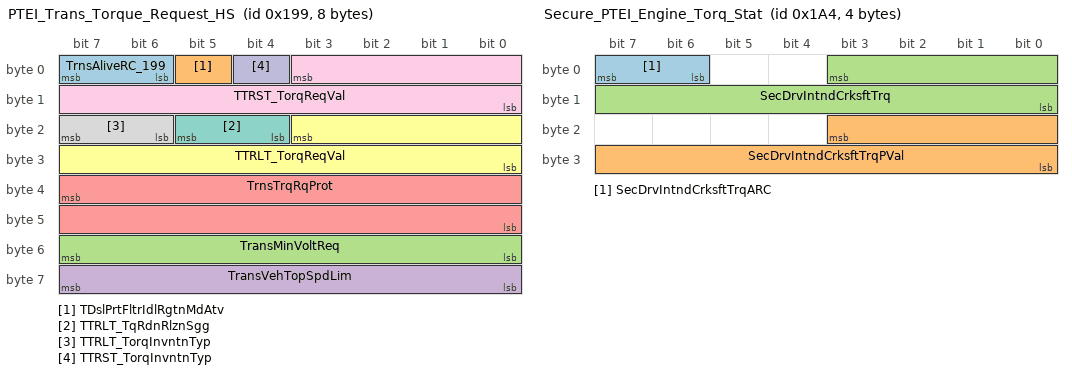
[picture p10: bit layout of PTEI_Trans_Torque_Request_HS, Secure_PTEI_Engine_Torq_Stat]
BO_ 409 PTEI_Trans_Torque_Request_HS: 8 TCM_HS
 SG_ TrnsAliveRC_199 : 7|2@0+ (1,0) [0|3] ""  CGM_HS,ECM_HS
 SG_ TDslPrtFltrIdlRgtnMdAtv : 5|1@0+ (1,0) [0|1] ""  CGM_HS,ECM_HS
 SG_ TransMinVoltReq : 55|8@0+ (0.07843,0) [0|19.99965] "volts"  CGM_HS,ECM_HS
 SG_ TransVehTopSpdLim : 63|8@0+ (2,0) [0|510] "km / h"  CGM_HS,ECM_HS
 SG_ TrnsTrqRqProt : 39|16@0+ (1,0) [0|65535] ""  CGM_HS,ECM_HS
 SG_ TTRLT_TorqReqVal : 19|12@0+ (0.5,-848) [-848|1199.5] "Nm"  CGM_HS,ECM_HS
 SG_ TTRLT_TqRdnRlznSgg : 21|2@0+ (1,0) [0|3] ""  CGM_HS,ECM_HS
 SG_ TTRLT_TorqInvntnTyp : 23|2@0+ (1,0) [0|3] ""  CGM_HS,ECM_HS
 SG_ TTRST_TorqReqVal : 3|12@0+ (0.5,-848) [-848|1199.5] "Nm"  CGM_HS,ECM_HS
 SG_ TTRST_TorqInvntnTyp : 4|1@0+ (1,0) [0|1] ""  CGM_HS,ECM_HS

BO_ 2016 USDT_Req_to_ECM_HS: 8 CGM_HS
 SG_ DgnInf : 7|64@0+ (1,0) [0|1.84467440737096E+019] ""  ECM_HS

BO_ 420 Secure_PTEI_Engine_Torq_Stat: 4 ECM_HS
 SG_ SecDrvIntndCrksftTrqARC : 7|2@0+ (1,0) [0|3] ""  CGM_HS,TCM_HS
 SG_ SecDrvIntndCrksftTrqPVal : 19|12@0+ (1,0) [0|4095] ""  CGM_HS,TCM_HS
 SG_ SecDrvIntndCrksftTrq : 3|12@0+ (0.5,-848) [-848|1199.5] "Nm"  CGM_HS,TCM_HS

BO_ 558 Air_Cmpresor_Ctrl_Data2_HS: 8 Vector__XXX
 SG_ CmpDataPktARC : 57|2@0+ (1,0) [0|3] "N/A"  BSM_HS
 SG_ CDP_HVDevShtdnCdARCSt : 49|2@0+ (1,0) [0|3] ""  BSM_HS
 SG_ CDP_CmpSpdReqARCSt : 51|2@0+ (1,0) [0|3] ""  BSM_HS
 SG_ CDP_CmpLossCommOcc : 52|1@0+ (1,0) [0|1] ""  BSM_HS
 SG_ CDP_CmpWkUp : 53|1@0+ (1,0) [0|1] ""  BSM_HS
 SG_ CDP_CmpRunCrnk : 54|1@0+ (1,0) [0|1] ""  BSM_HS
 SG_ CmpSnsrDevStPktARC : 5|2@0+ (1,0) [0|3] "N/A"  BSM_HS
 SG_ CDSP_CmpOvrTmpSt : 11|2@0+ (1,0) [0|3] ""  BSM_HS
 SG_ CDSP_CmpHVAbnrlOrVltSt : 13|2@0+ (1,0) [0|3] ""  BSM_HS
 SG_ CDSP_CmpHVUndrVltgSt : 15|2@0+ (1,0) [0|3] ""  BSM_HS
 SG_ CDSP_CmpHVOvrVltgSt : 1|2@0+ (1,0) [0|3] ""  BSM_HS
 SG_ CDSP_CmpHVOvrCrntSt : 3|2@0+ (1,0) [0|3] ""  BSM_HS
 SG_ CDSP_OvrTempWrnInd : 24|1@0+ (1,0) [0|1] ""  BSM_HS
 SG_ CDSP_CmpDgrdOp : 25|1@0+ (1,0) [0|1] ""  BSM_HS
 SG_ CDSP_CmpIntShdwnFltSt : 27|2@0+ (1,0) [0|3] ""  BSM_HS
 SG_ CDSP_CmpIntRecblFltSt : 29|2@0+ (1,0) [0|3] ""  BSM_HS
 SG_ CDSP_CmpOpOvrldSt : 31|2@0+ (1,0) [0|3] ""  BSM_HS
 SG_ CDSP_CmpDrCrctFltSt : 17|2@0+ (1,0) [0|3] ""  BSM_HS
 SG_ CDSP_CmpMtrPerfFltSt : 19|2@0+ (1,0) [0|3] ""  BSM_HS
 SG_ CDSP_CmpEEPROMFltSt : 21|2@0+ (1,0) [0|3] ""  BSM_HS
 SG_ CDSP_CmpROMFltSt : 23|2@0+ (1,0) [0|3] ""  BSM_HS
 SG_ CDSP_CmpRAMFltSt : 9|2@0+ (1,0) [0|3] ""  BSM_HS
 SG_ CmpSnsrStPktARC : 7|2@0+ (1,0) [0|3] "N/A"  BSM_HS
 SG_ CSSP_CmpIGBTTpOtRgLSt : 41|2@0+ (1,0) [0|3] ""  BSM_HS
 SG_ CSSP_CmpIGBTTpOtRgHSt : 43|2@0+ (1,0) [0|3] ""  BSM_HS
 SG_ CSSP_CmpCPUTmpOtRgLSt : 45|2@0+ (1,0) [0|3] ""  BSM_HS
 SG_ CSSP_CmpCPUTmpOtRgHSt : 47|2@0+ (1,0) [0|3] ""  BSM_HS
 SG_ CSSP_CmpHVSnsOtRgLSt : 33|2@0+ (1,0) [0|3] ""  BSM_HS
 SG_ CSSP_CmpHVSnsOtRgHSt : 35|2@0+ (1,0) [0|3] ""  BSM_HS
 SG_ CSSP_CmpPhCrntOtRgLSt : 37|2@0+ (1,0) [0|3] ""  BSM_HS
 SG_ CSSP_CmpPhCrntOtRgHSt : 39|2@0+ (1,0) [0|3] ""  BSM_HS

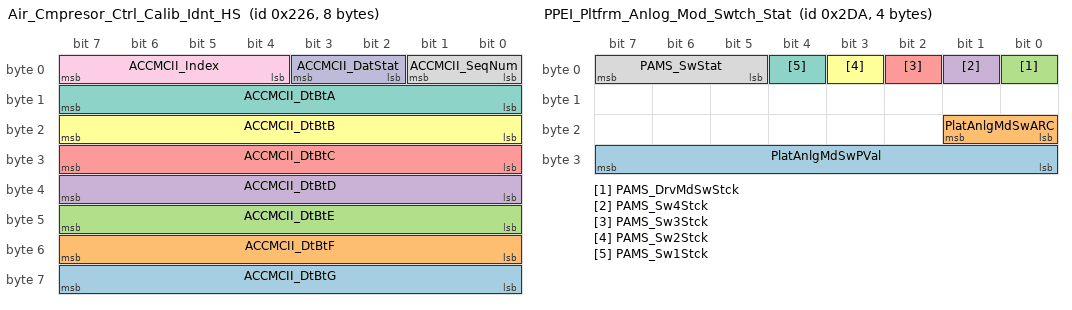
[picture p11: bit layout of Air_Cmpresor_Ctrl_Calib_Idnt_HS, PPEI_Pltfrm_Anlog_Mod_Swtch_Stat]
BO_ 550 Air_Cmpresor_Ctrl_Calib_Idnt_HS: 8 Vector__XXX
 SG_ ACCMCII_DtBtG : 63|8@0+ (1,0) [0|0] ""  BSM_HS
 SG_ ACCMCII_DtBtF : 55|8@0+ (1,0) [0|0] ""  BSM_HS
 SG_ ACCMCII_DtBtE : 47|8@0+ (1,0) [0|0] ""  BSM_HS
 SG_ ACCMCII_DtBtD : 39|8@0+ (1,0) [0|0] ""  BSM_HS
 SG_ ACCMCII_DtBtC : 31|8@0+ (1,0) [0|0] ""  BSM_HS
 SG_ ACCMCII_DtBtB : 23|8@0+ (1,0) [0|0] ""  BSM_HS
 SG_ ACCMCII_DtBtA : 15|8@0+ (1,0) [0|0] ""  BSM_HS
 SG_ ACCMCII_SeqNum : 1|2@0+ (1,0) [0|3] ""  BSM_HS
 SG_ ACCMCII_Index : 7|4@0+ (1,0) [0|15] ""  BSM_HS
 SG_ ACCMCII_DatStat : 3|2@0+ (1,0) [0|3] ""  BSM_HS

BO_ 504 PTEI_General_Status_5_HS: 2 ECM_HS
 SG_ EngCylDsrdFirngFractn : 7|8@0+ (0.00390625,0) [0|0.99609375] ""  CGM_HS,TCM_HS
 SG_ EngCylCalcFirngFractn : 15|8@0+ (0.00390625,0) [0|0.99609375] ""  CGM_HS,TCM_HS

BO_ 730 PPEI_Pltfrm_Anlog_Mod_Swtch_Stat: 4 ECM_HS
 SG_ PlatAnlgMdSwPVal : 31|8@0+ (1,0) [0|255] ""  CGM_HS
 SG_ PlatAnlgMdSwARC : 17|2@0+ (1,0) [0|3] ""  CGM_HS
 SG_ PAMS_DrvMdSwStck : 0|1@0+ (1,0) [0|1] ""  CGM_HS
 SG_ PAMS_Sw4Stck : 1|1@0+ (1,0) [0|1] ""  CGM_HS
 SG_ PAMS_Sw3Stck : 2|1@0+ (1,0) [0|1] ""  CGM_HS
 SG_ PAMS_Sw2Stck : 3|1@0+ (1,0) [0|1] ""  CGM_HS
 SG_ PAMS_Sw1Stck : 4|1@0+ (1,0) [0|1] ""  CGM_HS
 SG_ PAMS_SwStat : 7|3@0+ (1,0) [0|7] ""  CGM_HS

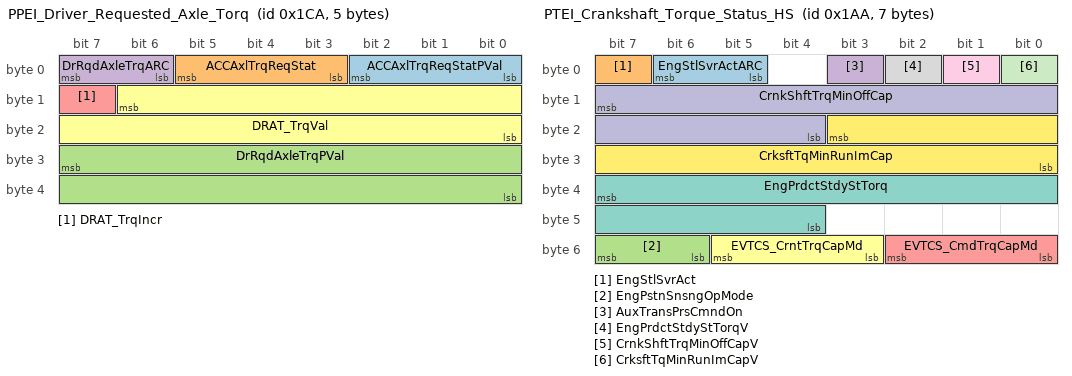
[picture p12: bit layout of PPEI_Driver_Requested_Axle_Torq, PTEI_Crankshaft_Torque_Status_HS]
BO_ 458 PPEI_Driver_Requested_Axle_Torq: 5 ECM_HS
 SG_ ACCAxlTrqReqStatPVal : 2|3@0+ (1,0) [0|7] ""  CGM_HS
 SG_ ACCAxlTrqReqStat : 5|3@0+ (1,0) [0|7] ""  CGM_HS
 SG_ DrRqdAxleTrqPVal : 31|16@0+ (1,0) [0|65535] ""  CGM_HS
 SG_ DrRqdAxleTrqARC : 7|2@0+ (1,0) [0|3] ""  CGM_HS
 SG_ DRAT_TrqIncr : 15|1@0+ (1,0) [0|1] ""  CGM_HS
 SG_ DRAT_TrqVal : 14|15@0+ (2,-22534) [-22534|43000] ""  CGM_HS

BO_ 426 PTEI_Crankshaft_Torque_Status_HS: 7 ECM_HS
 SG_ EngStlSvrActARC : 6|2@0+ (1,0) [0|3] ""  CGM_HS,TCM_HS
 SG_ EngStlSvrAct : 7|1@0+ (1,0) [0|1] ""  CGM_HS,TCM_HS
 SG_ EngPstnSnsngOpMode : 55|2@0+ (1,0) [0|3] ""  CGM_HS
 SG_ AuxTransPrsCmndOn : 3|1@0+ (1,0) [0|1] ""  CGM_HS,TCM_HS
 SG_ EVTCS_CmdTrqCapMd : 50|3@0+ (1,0) [0|7] ""  CGM_HS,TCM_HS
 SG_ EVTCS_CrntTrqCapMd : 53|3@0+ (1,0) [0|7] ""  CGM_HS,TCM_HS
 SG_ EngPrdctStdyStTorq : 39|12@0+ (0.5,-848) [-848|1199.5] "Nm"  CGM_HS,TCM_HS
 SG_ EngPrdctStdyStTorqV : 2|1@0+ (1,0) [0|1] ""  CGM_HS,TCM_HS
 SG_ CrnkShftTrqMinOffCapV : 1|1@0+ (1,0) [0|1] ""  CGM_HS,TCM_HS
 SG_ CrnkShftTrqMinOffCap : 15|12@0+ (0.5,-848) [-848|1199.5] "Nm"  CGM_HS,TCM_HS
 SG_ CrksftTqMinRunImCapV : 0|1@0+ (1,0) [0|1] ""  CGM_HS,TCM_HS
 SG_ CrksftTqMinRunImCap : 19|12@0+ (0.5,-848) [-848|1199.5] "Nm"  CGM_HS,TCM_HS

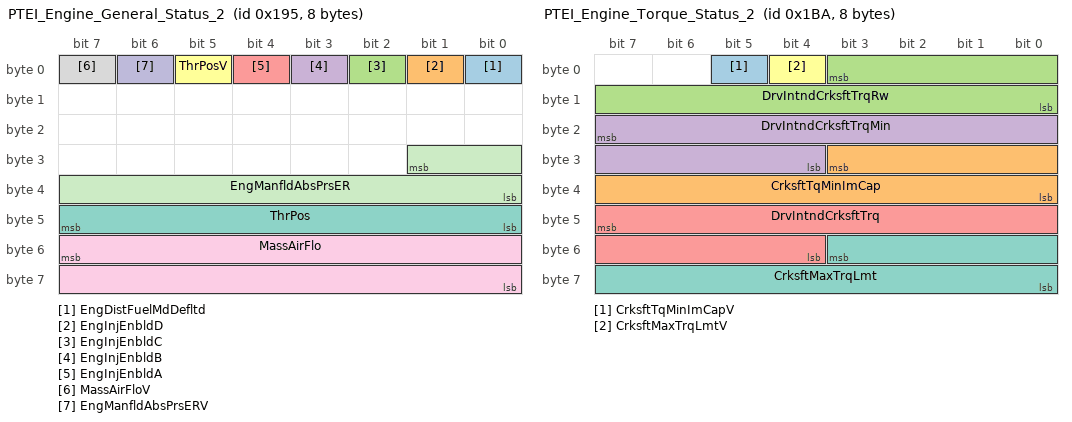
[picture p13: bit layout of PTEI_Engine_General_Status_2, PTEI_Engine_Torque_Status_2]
BO_ 405 PTEI_Engine_General_Status_2: 8 ECM_HS
 SG_ EngDistFuelMdDefltd : 0|1@0+ (1,0) [0|1] ""  CGM_HS
 SG_ EngInjEnbldD : 1|1@0+ (1,0) [0|1] ""  CGM_HS
 SG_ EngInjEnbldC : 2|1@0+ (1,0) [0|1] ""  CGM_HS
 SG_ EngInjEnbldB : 3|1@0+ (1,0) [0|1] ""  CGM_HS
 SG_ EngInjEnbldA : 4|1@0+ (1,0) [0|1] ""  CGM_HS
 SG_ ThrPosV : 5|1@0+ (1,0) [0|1] ""  CGM_HS
 SG_ ThrPos : 47|8@0+ (0.392157,0) [0|100.000035] "%"  CGM_HS
 SG_ MassAirFloV : 7|1@0+ (1,0) [0|1] ""  CGM_HS
 SG_ MassAirFlo : 55|16@0+ (0.01,0) [0|655.35] "grams/s"  CGM_HS
 SG_ EngManfldAbsPrsERV : 6|1@0+ (1,0) [0|1] ""  CGM_HS
 SG_ EngManfldAbsPrsER : 25|10@0+ (0.5,0) [0|511.5] "kPa"  CGM_HS

BO_ 442 PTEI_Engine_Torque_Status_2: 8 ECM_HS
 SG_ CrksftTqMinImCapV : 5|1@0+ (1,0) [0|1] ""  CGM_HS,TCM_HS
 SG_ CrksftTqMinImCap : 27|12@0+ (0.5,-848) [-848|1199.5] "Nm"  CGM_HS,TCM_HS
 SG_ DrvIntndCrksftTrqRw : 3|12@0+ (0.5,-848) [-848|1199.5] "Nm"  CGM_HS,TCM_HS
 SG_ DrvIntndCrksftTrqMin : 23|12@0+ (0.5,-848) [-848|1199.5] "Nm"  CGM_HS,TCM_HS
 SG_ DrvIntndCrksftTrq : 47|12@0+ (0.5,-848) [-848|1199.5] "Nm"  CGM_HS,TCM_HS
 SG_ CrksftMaxTrqLmtV : 4|1@0+ (1,0) [0|1] ""  CGM_HS,TCM_HS
 SG_ CrksftMaxTrqLmt : 51|12@0+ (0.5,-848) [-848|1199.5] "Nm"  CGM_HS,TCM_HS

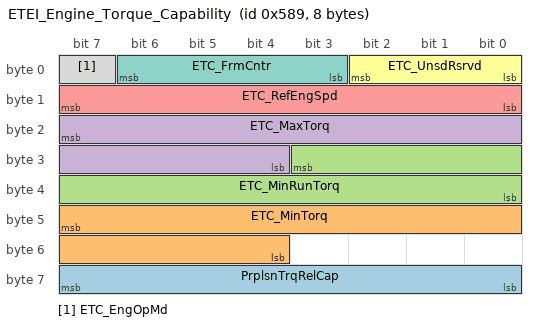
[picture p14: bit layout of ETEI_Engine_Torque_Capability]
BO_ 1417 ETEI_Engine_Torque_Capability: 8 ECM_HS
 SG_ PrplsnTrqRelCap : 63|8@0+ (0.5,0) [0|127.5] "%"  CGM_HS,TCM_HS
 SG_ ETC_MinTorq : 47|12@0+ (0.5,-848) [-848|1199.5] "Nm"  CGM_HS,TCM_HS
 SG_ ETC_MinRunTorq : 27|12@0+ (0.5,-848) [-848|1199.5] "Nm"  CGM_HS,TCM_HS
 SG_ ETC_MaxTorq : 23|12@0+ (0.5,-848) [-848|1199.5] "Nm"  CGM_HS,TCM_HS
 SG_ ETC_RefEngSpd : 15|8@0+ (32,0) [0|8160] "rpm"  CGM_HS,TCM_HS
 SG_ ETC_UnsdRsrvd : 2|3@0+ (1,0) [0|7] ""  CGM_HS,TCM_HS
 SG_ ETC_FrmCntr : 6|4@0+ (1,0) [0|15] ""  CGM_HS,TCM_HS
 SG_ ETC_EngOpMd : 7|1@0+ (1,0) [0|1] ""  CGM_HS,TCM_HS

CM_ BU_ CGM_HS "Communication Gateway";
CM_ BU_ TCM_HS "Transmission Control Module";
CM_ BU_ RDCM_HS "Rear Drive Control Module";
CM_ BU_ EPS_HS "Electronic Power Steering";
CM_ BU_ ECM_HS "Engine Control Module";
CM_ BU_ EBCM_HS "Electronic Brake Control Module";
CM_ BU_ BSM_HS "Battery State Manager";
CM_ BU_ BCM_HS "HS Side Global Architecture Gateway and Body Control Module";
CM_ BO_ 3221225472 "This is a message for not used signals, created by Vector CANdb++ DBC OLE DB Provider.";
CM_ SG_ 1919 DTCI_DTCFaultType_77F "Based on Powertrain definition.  Not expected to be supported by all devices.";
CM_ SG_ 1919 DTCI_DTCFailType_77F "Assigned per GMW3110, Appendix E";
CM_ SG_ 1919 DTCI_DTCSource_77F "This shall be equal to the Diagnostic Address of the transmittting device.";
CM_ SG_ 1914 DTCI_DTCFaultType_77A "Based on Powertrain definition.  Not expected to be supported by all devices.";
CM_ SG_ 1914 DTCI_DTCFailType_77A "Assigned per GMW3110, Appendix E";
CM_ SG_ 1914 DTCI_DTCSource_77A "This shall be equal to the Diagnostic Address of the transmittting device.";
CM_ SG_ 1912 DTCI_DTCFaultType_778 "Based on Powertrain definition.  Not expected to be supported by all devices.";
CM_ SG_ 1912 DTCI_DTCFailType_778 "Assigned per GMW3110, Appendix E";
CM_ SG_ 1912 DTCI_DTCSource_778 "This shall be equal to the Diagnostic Address of the transmittting device.";
CM_ SG_ 390 HybDFCOReq "DFCO = Deceleration Fuel Cut Off";
CM_ BO_ 719 "Application Is Tx ing this frame at the rate of 40 ms";
CM_ BO_ 717 "EOCM algorithm will transmit this message at a 40 ms periodic rate";
CM_ SG_ 1005 EnhSvVehTopSpdLimP "4 ASCII characters";
CM_ SG_ 431 TDslPrtFltrIdlRgtnMdAtv "Diesel signal could be shared with a Gasoline application";
CM_ SG_ 409 TDslPrtFltrIdlRgtnMdAtv "Diesel signal could be shared with a Gasoline application";
BA_DEF_ SG_  "GenSigSendOnInit" ENUM  "Not Initialized","Application","Handler","DLCLS","DLCHS","DLCCE","DLCFO";
BA_DEF_ SG_  "GenSigSendType" ENUM  "not used","not used","not used","not used","not used","not used","not used","NoSigSendType","not used","not used","OnAnyChange","OnChangeIfActive","OnDelta","DLCLS","DLCHS","DLCCE","DLCFO";
BA_DEF_ SG_  "GenSigDeltaValue" INT 0 0;
BA_DEF_ SG_  "VNSigAllNodes" ENUM  "No","Yes","DLCLS","DLCHS","DLCCE","DLCFO";
BA_DEF_ SG_  "VNSigSLHSSharedDiagnostic" ENUM  "No","Yes","DLCLS","DLCHS","DLCCE","DLCFO";
BA_DEF_ SG_  "VNSigSLHS_VNReq" ENUM  "No","Yes","DLCLS","DLCHS","DLCCE","DLCFO";
BA_DEF_ SG_  "SignalType" STRING ;
BA_DEF_ SG_  "PacketOrder" INT 0 65535;
BA_DEF_ SG_  "SignalLongName" STRING ;
BA_DEF_ SG_  "GenSigStartValue" INT 0 65535;
BA_DEF_ SG_  "TxSignalSendOnInit" ENUM  "Not Initialized","Application","Handler";
BA_DEF_ BO_  "GenMsgILSupport" ENUM  "No","Yes","DLCLS","DLCHS","DLCCE","DLCFO";
BA_DEF_ BO_  "AppGenMsgCycleTime" INT 0 0;
BA_DEF_ BO_  "TpApplType" STRING ;
BA_DEF_ BO_  "Prio" INT 0 7;
BA_DEF_ BO_  "MessageSubnet" ENUM  "LS","MS","HS","CE","PE","HV","FO","S1","HE","LE","HE2","DLCLS","DLCHS","DLCCE","DLCFO","vector_leerstring";
BA_DEF_ BO_  "DiagState" ENUM  "No","Yes";
BA_DEF_ BO_  "GenMsgIlSupport" ENUM  "No","Yes";
BA_DEF_ BO_  "GenMsgStartDelayTime" INT 0 100000;
BA_DEF_ BO_  "GenMsgDelayTime" INT 0 100000;
BA_DEF_ BO_  "GenMsgCycleTime" INT 0 100000;
BA_DEF_ BO_  "GenMsgSendType" ENUM  "cyclicX","spontanX","cyclicIfActiveX","spontanWithDelay","cyclicAndSpontanX","cyclicAndSpontanWithDelay","spontanWithRepitition","cyclicIfActiveAndSpontanWD";
BA_DEF_ BO_  "DiagResponse" ENUM  "No","Yes";
BA_DEF_ BO_  "DiagRequest" ENUM  "No","Yes";
BA_DEF_ BO_  "NmMessage" ENUM  "No","Yes";
BA_DEF_ BU_  "MessageManagerUsed" ENUM  "No","Yes","DLCLS","DLCHS","DLCCE","DLCFO";
BA_DEF_ BU_  "NmNode" ENUM  "No","Yes";
BA_DEF_ BU_  "ILUsed" ENUM  "No","Yes";
BA_DEF_ BU_  "FillCharacter" HEX 0 255;
BA_DEF_ BU_  "FlashSegmentSize" INT 0 256;
BA_DEF_ BU_  "NodeLayerModules" STRING ;
BA_DEF_ BU_  "VNECUSLHSSharedDiagnostic" ENUM  "None","Activator","Remoted","Activator and Remoted","Shared Local","DLCLS","DLCHS","DLCCE","DLCFO";
BA_DEF_ BU_  "VNECUSLHS_VNReq" ENUM  "None","Activator","Remoted","Activator and Remoted","Shared Local","DLCLS","DLCHS","DLCCE","DLCFO";
BA_DEF_ BU_  "VNECUAllNodes" ENUM  "None","Activator","Remoted","Activator and Remoted","Shared Local","DLCLS","DLCHS","DLCCE","DLCFO";
BA_DEF_ BU_  "ECU_Id" HEX 0 255;
BA_DEF_ BU_  "SourceId" HEX 0 253;
BA_DEF_  "VN_AllNodes" INT 0 255;
BA_DEF_  "VN_SLHSSharedDiagnostic" INT 0 255;
BA_DEF_  "VNInitActSLHSSharedDiagnostic" ENUM  "No","Yes","DLCLS","DLCHS","DLCCE","DLCFO";
BA_DEF_  "VN_SLHS_VNReq" INT 0 255;
BA_DEF_  "VNInitActSLHS_VNReq" ENUM  "No","Yes","DLCLS","DLCHS","DLCCE","DLCFO";
BA_DEF_  "VehicleArchitecture" STRING ;
BA_DEF_  "Baudrate" INT 0 1000000;
BA_DEF_  "SamplePointMin" FLOAT 0 100;
BA_DEF_  "SamplePointMax" FLOAT 0 100;
BA_DEF_  "SyncJumpWidthMin" INT 0 255;
BA_DEF_  "SyncJumpWidthMax" INT 0 255;
BA_DEF_  "VersionMonth" INT 0 255;
BA_DEF_  "BusType" STRING ;
BA_DEF_  "NmMessageCount" INT 0 32;
BA_DEF_  "NmBaseAddress" HEX 0 2032;
BA_DEF_  "NetworkType" STRING ;
BA_DEF_  "VNMFPeriodicInterval" INT 0 65535;
BA_DEF_  "BusWakeUpDelay" INT 0 65535;
BA_DEF_  "BusOffRecoveryTime" INT 0 65535;
BA_DEF_  "NodeStatusMsgID" HEX 0 536870911;
BA_DEF_  "NodeStatusMsgCycleTime" INT 0 65535;
BA_DEF_  "NodeStatusMsgTimeoutTime" INT 0 65535;
BA_DEF_  "UseGMParameterIDs" INT 0 1;
BA_DEF_  "VersionWeek" INT 0 255;
BA_DEF_  "VersionYear" INT 0 255;
BA_DEF_  "Manufacturer" ENUM  "DBAG","VAG","BMW","PAG","GM";
BA_DEF_  "NmType" STRING ;
BA_DEF_REL_ BU_SG_REL_  "GenSigSuprvResp" ENUM  "None","Notify App","Substitute Default","DLCLS","DLCHS","DLCCE","DLCFO";
BA_DEF_REL_ BU_SG_REL_  "GenSigSuprvRespSubValue" INT 0 65535;
BA_DEF_REL_ BU_SG_REL_  "GenSigRxStartValue" STRING ;
BA_DEF_REL_ BU_SG_REL_  "GenSigVDAFailResp" ENUM  "No","Yes","DLCLS","DLCHS","DLCCE","DLCFO";
BA_DEF_REL_ BU_SG_REL_  "GenSigVDAFailComment" STRING ;
BA_DEF_REL_ BU_SG_REL_  "GenSigVBitRespComment" STRING ;
BA_DEF_REL_ BU_SG_REL_  "GenSigVBitResp" ENUM  "No","Yes","DLCLS","DLCHS","DLCCE","DLCFO";
BA_DEF_REL_ BU_SG_REL_  "GenSigSuprvRespComment" STRING ;
BA_DEF_REL_ BU_SG_REL_  "GenSigTimeoutMsg" HEX 0 268435455;
BA_DEF_REL_ BU_SG_REL_  "GenSigTimeoutTime" INT 0 5000;
BA_DEF_DEF_  "GenSigSendOnInit" "Not Initialized";
BA_DEF_DEF_  "GenSigSendType" "NoSigSendType";
BA_DEF_DEF_  "GenSigDeltaValue" 0;
BA_DEF_DEF_  "VNSigAllNodes" "No";
BA_DEF_DEF_  "VNSigSLHSSharedDiagnostic" "No";
BA_DEF_DEF_  "VNSigSLHS_VNReq" "No";
BA_DEF_DEF_  "SignalType" "";
BA_DEF_DEF_  "PacketOrder" 0;
BA_DEF_DEF_  "SignalLongName" "";
BA_DEF_DEF_  "GenSigStartValue" 0;
BA_DEF_DEF_  "TxSignalSendOnInit" "Not Initialized";
BA_DEF_DEF_  "GenMsgILSupport" "Yes";
BA_DEF_DEF_  "AppGenMsgCycleTime" 0;
BA_DEF_DEF_  "TpApplType" "";
BA_DEF_DEF_  "Prio" 0;
BA_DEF_DEF_  "MessageSubnet" "LS";
BA_DEF_DEF_  "DiagState" "No";
BA_DEF_DEF_  "GenMsgIlSupport" "Yes";
BA_DEF_DEF_  "GenMsgStartDelayTime" 0;
BA_DEF_DEF_  "GenMsgDelayTime" 0;
BA_DEF_DEF_  "GenMsgCycleTime" 0;
BA_DEF_DEF_  "GenMsgSendType" "spontanX";
BA_DEF_DEF_  "DiagResponse" "No";
BA_DEF_DEF_  "DiagRequest" "No";
BA_DEF_DEF_  "NmMessage" "No";
BA_DEF_DEF_  "MessageManagerUsed" "Yes";
BA_DEF_DEF_  "NmNode" "Yes";
BA_DEF_DEF_  "ILUsed" "Yes";
BA_DEF_DEF_  "FillCharacter" 255;
BA_DEF_DEF_  "FlashSegmentSize" 8;
BA_DEF_DEF_  "NodeLayerModules" "gmlan02.dll";
BA_DEF_DEF_  "VNECUSLHSSharedDiagnostic" "None";
BA_DEF_DEF_  "VNECUSLHS_VNReq" "None";
BA_DEF_DEF_  "VNECUAllNodes" "None";
BA_DEF_DEF_  "ECU_Id" 0;
BA_DEF_DEF_  "SourceId" 0;
BA_DEF_DEF_  "VN_AllNodes" 1;
BA_DEF_DEF_  "VN_SLHSSharedDiagnostic" 0;
BA_DEF_DEF_  "VNInitActSLHSSharedDiagnostic" "No";
BA_DEF_DEF_  "VN_SLHS_VNReq" 2;
BA_DEF_DEF_  "VNInitActSLHS_VNReq" "No";
BA_DEF_DEF_  "VehicleArchitecture" "";
BA_DEF_DEF_  "Baudrate" 0;
BA_DEF_DEF_  "SamplePointMin" 0;
BA_DEF_DEF_  "SamplePointMax" 0;
BA_DEF_DEF_  "SyncJumpWidthMin" 0;
BA_DEF_DEF_  "SyncJumpWidthMax" 0;
BA_DEF_DEF_  "VersionMonth" 0;
BA_DEF_DEF_  "BusType" "";
BA_DEF_DEF_  "NmMessageCount" 32;
BA_DEF_DEF_  "NmBaseAddress" 1568;
BA_DEF_DEF_  "NetworkType" "";
BA_DEF_DEF_  "VNMFPeriodicInterval" 3000;
BA_DEF_DEF_  "BusWakeUpDelay" 100;
BA_DEF_DEF_  "BusOffRecoveryTime" 0;
BA_DEF_DEF_  "NodeStatusMsgID" 268433408;
BA_DEF_DEF_  "NodeStatusMsgCycleTime" 1200;
BA_DEF_DEF_  "NodeStatusMsgTimeoutTime" 3000;
BA_DEF_DEF_  "UseGMParameterIDs" 1;
BA_DEF_DEF_  "VersionWeek" 0;
BA_DEF_DEF_  "VersionYear" 0;
BA_DEF_DEF_  "Manufacturer" "GM";
BA_DEF_DEF_  "NmType" "GMLAN";
BA_DEF_DEF_REL_ "GenSigSuprvResp" "None";
BA_DEF_DEF_REL_ "GenSigSuprvRespSubValue" 0;
BA_DEF_DEF_REL_ "GenSigRxStartValue" "";
BA_DEF_DEF_REL_ "GenSigVDAFailResp" "No";
BA_DEF_DEF_REL_ "GenSigVDAFailComment" "";
BA_DEF_DEF_REL_ "GenSigVBitRespComment" "";
BA_DEF_DEF_REL_ "GenSigVBitResp" "No";
BA_DEF_DEF_REL_ "GenSigSuprvRespComment" "";
BA_DEF_DEF_REL_ "GenSigTimeoutMsg" 0;
BA_DEF_DEF_REL_ "GenSigTimeoutTime" 0;
BA_ "VersionYear" 19;
BA_ "VersionWeek" 41;
BA_ "UseGMParameterIDs" 0;
BA_ "NodeStatusMsgTimeoutTime" 0;
BA_ "NodeStatusMsgID" 0;
BA_ "BusOffRecoveryTime" 160;
BA_ "NetworkType" "Powertrain";
BA_ "BusType" "CAN";
BA_ "VersionMonth" 19;
BA_ "SyncJumpWidthMax" 4;
BA_ "SyncJumpWidthMin" 3;
BA_ "SamplePointMax" 81.25;
BA_ "SamplePointMin" 80;
BA_ "Baudrate" 500000;
BA_ "VehicleArchitecture" "Global A";
BA_ "VNInitActSLHS_VNReq" 1;
BA_ "VNInitActSLHSSharedDiagnostic" 1;
BA_ "SourceId" BU_ CGM_HS 69;
BA_ "ECU_Id" BU_ CGM_HS 31;
BA_ "VNECUAllNodes" BU_ CGM_HS 4;
BA_ "VNECUSLHS_VNReq" BU_ CGM_HS 4;
BA_ "VNECUSLHSSharedDiagnostic" BU_ CGM_HS 4;
BA_ "SourceId" BU_ TCM_HS 24;
BA_ "ECU_Id" BU_ TCM_HS 226;
BA_ "VNECUAllNodes" BU_ TCM_HS 4;
BA_ "VNECUSLHS_VNReq" BU_ TCM_HS 4;
BA_ "VNECUSLHSSharedDiagnostic" BU_ TCM_HS 4;
BA_ "SourceId" BU_ RDCM_HS 27;
BA_ "ECU_Id" BU_ RDCM_HS 15;
BA_ "VNECUAllNodes" BU_ RDCM_HS 4;
BA_ "VNECUSLHS_VNReq" BU_ RDCM_HS 4;
BA_ "VNECUSLHSSharedDiagnostic" BU_ RDCM_HS 4;
BA_ "SourceId" BU_ EPS_HS 49;
BA_ "ECU_Id" BU_ EPS_HS 2;
BA_ "VNECUAllNodes" BU_ EPS_HS 4;
BA_ "VNECUSLHS_VNReq" BU_ EPS_HS 4;
BA_ "VNECUSLHSSharedDiagnostic" BU_ EPS_HS 4;
BA_ "SourceId" BU_ ECM_HS 17;
BA_ "ECU_Id" BU_ ECM_HS 224;
BA_ "VNECUAllNodes" BU_ ECM_HS 4;
BA_ "VNECUSLHS_VNReq" BU_ ECM_HS 4;
BA_ "VNECUSLHSSharedDiagnostic" BU_ ECM_HS 4;
BA_ "SourceId" BU_ EBCM_HS 40;
BA_ "ECU_Id" BU_ EBCM_HS 3;
BA_ "VNECUAllNodes" BU_ EBCM_HS 4;
BA_ "VNECUSLHS_VNReq" BU_ EBCM_HS 4;
BA_ "VNECUSLHSSharedDiagnostic" BU_ EBCM_HS 4;
BA_ "SourceId" BU_ BSM_HS 203;
BA_ "ECU_Id" BU_ BSM_HS 228;
BA_ "VNECUAllNodes" BU_ BSM_HS 4;
BA_ "VNECUSLHS_VNReq" BU_ BSM_HS 4;
BA_ "VNECUSLHSSharedDiagnostic" BU_ BSM_HS 4;
BA_ "SourceId" BU_ BCM_HS 64;
BA_ "ECU_Id" BU_ BCM_HS 1;
BA_ "VNECUAllNodes" BU_ BCM_HS 4;
BA_ "VNECUSLHS_VNReq" BU_ BCM_HS 4;
BA_ "VNECUSLHSSharedDiagnostic" BU_ BCM_HS 4;
BA_ "DiagResponse" BO_ 808 1;
BA_ "MessageSubnet" BO_ 808 2;
BA_ "GenMsgSendType" BO_ 568 0;
BA_ "GenMsgCycleTime" BO_ 568 10;
BA_ "MessageSubnet" BO_ 568 2;
BA_ "DiagRequest" BO_ 49 1;
BA_ "MessageSubnet" BO_ 49 2;
BA_ "GenMsgSendType" BO_ 292 0;
BA_ "GenMsgCycleTime" BO_ 292 100;
BA_ "MessageSubnet" BO_ 292 2;
BA_ "DiagRequest" BO_ 40 1;
BA_ "MessageSubnet" BO_ 40 2;
BA_ "MessageSubnet" BO_ 1357 2;
BA_ "TpApplType" BO_ 1357 "DiagUUDTResponse";
BA_ "GenMsgILSupport" BO_ 1357 0;
BA_ "DiagResponse" BO_ 1613 1;
BA_ "MessageSubnet" BO_ 1613 2;
BA_ "DiagRequest" BO_ 2018 1;
BA_ "MessageSubnet" BO_ 2018 2;
BA_ "GenMsgSendType" BO_ 430 0;
BA_ "GenMsgCycleTime" BO_ 430 25;
BA_ "MessageSubnet" BO_ 430 2;
BA_ "GenMsgSendType" BO_ 429 0;
BA_ "GenMsgCycleTime" BO_ 429 25;
BA_ "MessageSubnet" BO_ 429 2;
BA_ "GenMsgSendType" BO_ 399 0;
BA_ "GenMsgCycleTime" BO_ 399 25;
BA_ "MessageSubnet" BO_ 399 2;
BA_ "GenMsgSendType" BO_ 425 0;
BA_ "GenMsgCycleTime" BO_ 425 25;
BA_ "MessageSubnet" BO_ 425 2;
BA_ "GenMsgSendType" BO_ 424 0;
BA_ "GenMsgCycleTime" BO_ 424 25;
BA_ "MessageSubnet" BO_ 424 2;
BA_ "GenMsgSendType" BO_ 423 0;
BA_ "GenMsgCycleTime" BO_ 423 25;
BA_ "MessageSubnet" BO_ 423 2;
BA_ "GenMsgSendType" BO_ 901 0;
BA_ "GenMsgCycleTime" BO_ 901 100;
BA_ "MessageSubnet" BO_ 901 2;
BA_ "GenMsgSendType" BO_ 1919 0;
BA_ "GenMsgCycleTime" BO_ 1919 1000;
BA_ "MessageSubnet" BO_ 1919 2;
BA_ "Prio" BO_ 1919 6;
BA_ "DiagResponse" BO_ 2026 1;
BA_ "MessageSubnet" BO_ 2026 2;
BA_ "MessageSubnet" BO_ 1514 2;
BA_ "TpApplType" BO_ 1514 "DiagUUDTResponse";
BA_ "GenMsgILSupport" BO_ 1514 0;
BA_ "MessageSubnet" BO_ 1801 2;
BA_ "DiagRequest" BO_ 591 1;
BA_ "MessageSubnet" BO_ 591 2;
BA_ "MessageSubnet" BO_ 1799 2;
BA_ "MessageSubnet" BO_ 1359 2;
BA_ "TpApplType" BO_ 1359 "DiagUUDTResponse";
BA_ "GenMsgILSupport" BO_ 1359 0;
BA_ "GenMsgSendType" BO_ 1914 0;
BA_ "GenMsgCycleTime" BO_ 1914 1000;
BA_ "MessageSubnet" BO_ 1914 2;
BA_ "Prio" BO_ 1914 6;
BA_ "DiagResponse" BO_ 1615 1;
BA_ "MessageSubnet" BO_ 1615 2;
BA_ "MessageSubnet" BO_ 1800 2;
BA_ "MessageSubnet" BO_ 1810 2;
BA_ "DiagRequest" BO_ 578 1;
BA_ "MessageSubnet" BO_ 578 2;
BA_ "MessageSubnet" BO_ 1798 2;
BA_ "MessageSubnet" BO_ 1808 2;
BA_ "GenMsgSendType" BO_ 1912 0;
BA_ "GenMsgCycleTime" BO_ 1912 1000;
BA_ "MessageSubnet" BO_ 1912 2;
BA_ "Prio" BO_ 1912 6;
BA_ "MessageSubnet" BO_ 1346 2;
BA_ "TpApplType" BO_ 1346 "DiagUUDTResponse";
BA_ "GenMsgILSupport" BO_ 1346 0;
BA_ "DiagResponse" BO_ 1602 1;
BA_ "MessageSubnet" BO_ 1602 2;
BA_ "GenMsgSendType" BO_ 388 0;
BA_ "GenMsgCycleTime" BO_ 388 100;
BA_ "MessageSubnet" BO_ 388 2;
BA_ "DiagResponse" BO_ 1611 1;
BA_ "MessageSubnet" BO_ 1611 2;
BA_ "GenMsgILSupport" BO_ 1611 0;
BA_ "GenMsgCycleTime" BO_ 546 100;
BA_ "MessageSubnet" BO_ 546 2;
BA_ "GenMsgCycleTime" BO_ 390 12;
BA_ "MessageSubnet" BO_ 390 2;
BA_ "MessageSubnet" BO_ 1355 2;
BA_ "TpApplType" BO_ 1355 "DiagUUDTResponse";
BA_ "GenMsgILSupport" BO_ 1355 0;
BA_ "GenMsgSendType" BO_ 418 0;
BA_ "GenMsgCycleTime" BO_ 418 25;
BA_ "MessageSubnet" BO_ 418 2;
BA_ "GenMsgSendType" BO_ 1236 0;
BA_ "GenMsgCycleTime" BO_ 1236 1000;
BA_ "MessageSubnet" BO_ 1236 2;
BA_ "GenMsgSendType" BO_ 1195 0;
BA_ "GenMsgCycleTime" BO_ 1195 1000;
BA_ "MessageSubnet" BO_ 1195 2;
BA_ "GenMsgSendType" BO_ 612 0;
BA_ "GenMsgCycleTime" BO_ 612 100;
BA_ "MessageSubnet" BO_ 612 2;
BA_ "GenMsgSendType" BO_ 189 0;
BA_ "GenMsgCycleTime" BO_ 189 25;
BA_ "MessageSubnet" BO_ 189 2;
BA_ "GenMsgSendType" BO_ 422 0;
BA_ "GenMsgCycleTime" BO_ 422 25;
BA_ "MessageSubnet" BO_ 422 2;
BA_ "GenMsgSendType" BO_ 1189 0;
BA_ "GenMsgCycleTime" BO_ 1189 500;
BA_ "MessageSubnet" BO_ 1189 2;
BA_ "GenMsgSendType" BO_ 393 0;
BA_ "GenMsgCycleTime" BO_ 393 25;
BA_ "MessageSubnet" BO_ 393 2;
BA_ "MessageSubnet" BO_ 719 2;
BA_ "AppGenMsgCycleTime" BO_ 719 40;
BA_ "MessageSubnet" BO_ 717 2;
BA_ "AppGenMsgCycleTime" BO_ 717 40;
BA_ "GenMsgSendType" BO_ 1005 0;
BA_ "GenMsgCycleTime" BO_ 1005 250;
BA_ "MessageSubnet" BO_ 1005 2;
BA_ "GenMsgSendType" BO_ 431 0;
BA_ "GenMsgCycleTime" BO_ 431 25;
BA_ "MessageSubnet" BO_ 431 2;
BA_ "GenMsgSendType" BO_ 409 0;
BA_ "GenMsgCycleTime" BO_ 409 25;
BA_ "MessageSubnet" BO_ 409 2;
BA_ "DiagRequest" BO_ 2016 1;
BA_ "MessageSubnet" BO_ 2016 2;
BA_ "GenMsgSendType" BO_ 420 0;
BA_ "GenMsgCycleTime" BO_ 420 25;
BA_ "MessageSubnet" BO_ 420 2;
BA_ "GenMsgCycleTime" BO_ 558 100;
BA_ "MessageSubnet" BO_ 558 2;
BA_ "GenMsgCycleTime" BO_ 550 500;
BA_ "MessageSubnet" BO_ 550 2;
BA_ "GenMsgSendType" BO_ 504 0;
BA_ "GenMsgCycleTime" BO_ 504 25;
BA_ "MessageSubnet" BO_ 504 2;
BA_ "GenMsgSendType" BO_ 730 0;
BA_ "GenMsgCycleTime" BO_ 730 50;
BA_ "MessageSubnet" BO_ 730 2;
BA_ "GenMsgSendType" BO_ 458 0;
BA_ "GenMsgCycleTime" BO_ 458 25;
BA_ "MessageSubnet" BO_ 458 2;
BA_ "GenMsgSendType" BO_ 426 0;
BA_ "GenMsgCycleTime" BO_ 426 25;
BA_ "MessageSubnet" BO_ 426 2;
BA_ "GenMsgSendType" BO_ 405 0;
BA_ "GenMsgCycleTime" BO_ 405 12;
BA_ "MessageSubnet" BO_ 405 2;
BA_ "GenMsgSendType" BO_ 442 0;
BA_ "GenMsgCycleTime" BO_ 442 25;
BA_ "MessageSubnet" BO_ 442 2;
BA_ "GenMsgSendType" BO_ 1417 0;
BA_ "GenMsgCycleTime" BO_ 1417 500;
BA_ "MessageSubnet" BO_ 1417 2;
BA_ "SignalLongName" SG_ 3221225472 ChgrSysAdblIndReq "Charger System Audible Indication Request";
BA_ "SignalType" SG_ 3221225472 ChgrSysAdblIndReq "ENM";
BA_ "VNSigAllNodes" SG_ 3221225472 ChgrSysAdblIndReq 1;
BA_ "GenSigSendType" SG_ 3221225472 ChgrSysAdblIndReq 10;
BA_ "SignalLongName" SG_ 3221225472 BattVltIRq "Battery Voltage Indication Request";
BA_ "SignalType" SG_ 3221225472 BattVltIRq "ENM";
BA_ "VNSigAllNodes" SG_ 3221225472 BattVltIRq 1;
BA_ "SignalLongName" SG_ 808 DgnInf "Diagnostic Information";
BA_ "SignalType" SG_ 808 DgnInf "UNM";
BA_ "VNSigSLHSSharedDiagnostic" SG_ 808 DgnInf 1;
BA_ "VNSigAllNodes" SG_ 808 DgnInf 1;
BA_ "GenSigDeltaValue" SG_ 808 DgnInf 1;
BA_ "GenSigSendType" SG_ 808 DgnInf 12;
BA_ "SignalLongName" SG_ 568 a_12VSysVlt "12V System Voltage";
BA_ "SignalType" SG_ 568 a_12VSysVlt "UNM";
BA_ "VNSigAllNodes" SG_ 568 a_12VSysVlt 1;
BA_ "SignalLongName" SG_ 49 DgnInf "Diagnostic Information";
BA_ "SignalType" SG_ 49 DgnInf "UNM";
BA_ "VNSigSLHSSharedDiagnostic" SG_ 49 DgnInf 1;
BA_ "VNSigAllNodes" SG_ 49 DgnInf 1;
BA_ "GenSigDeltaValue" SG_ 49 DgnInf 1;
BA_ "GenSigSendType" SG_ 49 DgnInf 12;
BA_ "SignalLongName" SG_ 292 TrlrStTwHlMdOvrd "Trailer State Tow Haul Mode Override";
BA_ "SignalType" SG_ 292 TrlrStTwHlMdOvrd "ENM";
BA_ "VNSigAllNodes" SG_ 292 TrlrStTwHlMdOvrd 1;
BA_ "SignalLongName" SG_ 292 AutoVehMdCmdPVal "Automatic Vehicle Mode Command Protection Value";
BA_ "SignalType" SG_ 292 AutoVehMdCmdPVal "UNM";
BA_ "VNSigAllNodes" SG_ 292 AutoVehMdCmdPVal 1;
BA_ "SignalLongName" SG_ 292 AutoVehMdCmdARC "Automatic Vehicle Mode Command Alive Rolling Count";
BA_ "SignalType" SG_ 292 AutoVehMdCmdARC "UNM";
BA_ "VNSigAllNodes" SG_ 292 AutoVehMdCmdARC 1;
BA_ "GenSigStartValue" SG_ 292 AVMC_MdReqstd 30;
BA_ "SignalLongName" SG_ 292 AVMC_MdReqstd "Automatic Vehicle Mode Command : Mode Requested";
BA_ "PacketOrder" SG_ 292 AVMC_MdReqstd 2;
BA_ "SignalType" SG_ 292 AVMC_MdReqstd "ENM";
BA_ "VNSigAllNodes" SG_ 292 AVMC_MdReqstd 1;
BA_ "SignalLongName" SG_ 292 AVMC_MdFtrEnbld "Automatic Vehicle Mode Command : Mode Feature Enabled";
BA_ "PacketOrder" SG_ 292 AVMC_MdFtrEnbld 1;
BA_ "SignalType" SG_ 292 AVMC_MdFtrEnbld "BLN";
BA_ "VNSigAllNodes" SG_ 292 AVMC_MdFtrEnbld 1;
BA_ "SignalLongName" SG_ 40 DgnInf "Diagnostic Information";
BA_ "SignalType" SG_ 40 DgnInf "UNM";
BA_ "VNSigSLHSSharedDiagnostic" SG_ 40 DgnInf 1;
BA_ "VNSigAllNodes" SG_ 40 DgnInf 1;
BA_ "GenSigDeltaValue" SG_ 40 DgnInf 1;
BA_ "GenSigSendType" SG_ 40 DgnInf 12;
BA_ "SignalLongName" SG_ 1357 DgnInf_HS54D "Diagnostic Information HS54D";
BA_ "SignalType" SG_ 1357 DgnInf_HS54D "UNM";
BA_ "VNSigSLHSSharedDiagnostic" SG_ 1357 DgnInf_HS54D 1;
BA_ "VNSigAllNodes" SG_ 1357 DgnInf_HS54D 1;
BA_ "GenSigDeltaValue" SG_ 1357 DgnInf_HS54D 1;
BA_ "GenSigSendType" SG_ 1357 DgnInf_HS54D 12;
BA_ "SignalLongName" SG_ 1613 DgnInf "Diagnostic Information";
BA_ "SignalType" SG_ 1613 DgnInf "UNM";
BA_ "VNSigSLHSSharedDiagnostic" SG_ 1613 DgnInf 1;
BA_ "VNSigAllNodes" SG_ 1613 DgnInf 1;
BA_ "GenSigDeltaValue" SG_ 1613 DgnInf 1;
BA_ "GenSigSendType" SG_ 1613 DgnInf 12;
BA_ "SignalLongName" SG_ 2018 DgnInf "Diagnostic Information";
BA_ "SignalType" SG_ 2018 DgnInf "UNM";
BA_ "VNSigSLHSSharedDiagnostic" SG_ 2018 DgnInf 1;
BA_ "VNSigAllNodes" SG_ 2018 DgnInf 1;
BA_ "GenSigDeltaValue" SG_ 2018 DgnInf 1;
BA_ "GenSigSendType" SG_ 2018 DgnInf 12;
BA_ "SignalLongName" SG_ 430 TCFS_Cltch5FltStat "Transmission Clutch Fault Status : Clutch 5 Fault Status";
BA_ "PacketOrder" SG_ 430 TCFS_Cltch5FltStat 5;
BA_ "SignalType" SG_ 430 TCFS_Cltch5FltStat "ENM";
BA_ "VNSigAllNodes" SG_ 430 TCFS_Cltch5FltStat 1;
BA_ "SignalLongName" SG_ 430 TCFS_Cltch4FltStat "Transmission Clutch Fault Status : Clutch 4 Fault Status";
BA_ "PacketOrder" SG_ 430 TCFS_Cltch4FltStat 4;
BA_ "SignalType" SG_ 430 TCFS_Cltch4FltStat "ENM";
BA_ "VNSigAllNodes" SG_ 430 TCFS_Cltch4FltStat 1;
BA_ "SignalLongName" SG_ 430 TCFS_Cltch3FltStat "Transmission Clutch Fault Status : Clutch 3 Fault Status";
BA_ "PacketOrder" SG_ 430 TCFS_Cltch3FltStat 3;
BA_ "SignalType" SG_ 430 TCFS_Cltch3FltStat "ENM";
BA_ "VNSigAllNodes" SG_ 430 TCFS_Cltch3FltStat 1;
BA_ "SignalLongName" SG_ 430 TCFS_Cltch2FltStat "Transmission Clutch Fault Status : Clutch 2 Fault Status";
BA_ "PacketOrder" SG_ 430 TCFS_Cltch2FltStat 2;
BA_ "SignalType" SG_ 430 TCFS_Cltch2FltStat "ENM";
BA_ "VNSigAllNodes" SG_ 430 TCFS_Cltch2FltStat 1;
BA_ "SignalLongName" SG_ 430 TCFS_Cltch1FltStat "Transmission Clutch Fault Status : Clutch 1 Fault Status";
BA_ "PacketOrder" SG_ 430 TCFS_Cltch1FltStat 1;
BA_ "SignalType" SG_ 430 TCFS_Cltch1FltStat "ENM";
BA_ "VNSigAllNodes" SG_ 430 TCFS_Cltch1FltStat 1;
BA_ "SignalLongName" SG_ 430 TransClch5FlTm "Transmission Clutch 5 Fill Time";
BA_ "SignalType" SG_ 430 TransClch5FlTm "UNM";
BA_ "VNSigAllNodes" SG_ 430 TransClch5FlTm 1;
BA_ "SignalLongName" SG_ 430 TransClch5FlAch "Transmission Clutch 5 Fill Achieved";
BA_ "SignalType" SG_ 430 TransClch5FlAch "BLN";
BA_ "VNSigAllNodes" SG_ 430 TransClch5FlAch 1;
BA_ "SignalLongName" SG_ 430 TransClch4FlTm "Transmission Clutch 4 Fill Time";
BA_ "SignalType" SG_ 430 TransClch4FlTm "UNM";
BA_ "VNSigAllNodes" SG_ 430 TransClch4FlTm 1;
BA_ "SignalLongName" SG_ 430 TransClch4FlAch "Transmission Clutch 4 Fill Achieved";
BA_ "SignalType" SG_ 430 TransClch4FlAch "BLN";
BA_ "VNSigAllNodes" SG_ 430 TransClch4FlAch 1;
BA_ "SignalLongName" SG_ 430 TransClch3FlTm "Transmission Clutch 3 Fill Time";
BA_ "SignalType" SG_ 430 TransClch3FlTm "UNM";
BA_ "VNSigAllNodes" SG_ 430 TransClch3FlTm 1;
BA_ "SignalLongName" SG_ 430 TransClch3FlAch "Transmission Clutch 3 Fill Achieved";
BA_ "SignalType" SG_ 430 TransClch3FlAch "BLN";
BA_ "VNSigAllNodes" SG_ 430 TransClch3FlAch 1;
BA_ "SignalLongName" SG_ 430 TransClch2FlTm "Transmission Clutch 2 Fill Time";
BA_ "SignalType" SG_ 430 TransClch2FlTm "UNM";
BA_ "VNSigAllNodes" SG_ 430 TransClch2FlTm 1;
BA_ "SignalLongName" SG_ 430 TransClch2FlAch "Transmission Clutch 2 Fill Achieved";
BA_ "SignalType" SG_ 430 TransClch2FlAch "BLN";
BA_ "VNSigAllNodes" SG_ 430 TransClch2FlAch 1;
BA_ "SignalLongName" SG_ 430 TransClch1FlTm "Transmission Clutch 1 Fill Time";
BA_ "SignalType" SG_ 430 TransClch1FlTm "UNM";
BA_ "VNSigAllNodes" SG_ 430 TransClch1FlTm 1;
BA_ "SignalLongName" SG_ 430 TransClch1FlAch "Transmission Clutch 1 Fill Achieved";
BA_ "SignalType" SG_ 430 TransClch1FlAch "BLN";
BA_ "VNSigAllNodes" SG_ 430 TransClch1FlAch 1;
BA_ "SignalLongName" SG_ 429 TCET_Cltch5 "Transmission Clutch Estimated Torque : Clutch 5";
BA_ "PacketOrder" SG_ 429 TCET_Cltch5 5;
BA_ "SignalType" SG_ 429 TCET_Cltch5 "UNM";
BA_ "VNSigAllNodes" SG_ 429 TCET_Cltch5 1;
BA_ "SignalLongName" SG_ 429 TCET_Cltch4 "Transmission Clutch Estimated Torque : Clutch 4";
BA_ "PacketOrder" SG_ 429 TCET_Cltch4 4;
BA_ "SignalType" SG_ 429 TCET_Cltch4 "UNM";
BA_ "VNSigAllNodes" SG_ 429 TCET_Cltch4 1;
BA_ "SignalLongName" SG_ 429 TCET_Cltch3 "Transmission Clutch Estimated Torque : Clutch 3";
BA_ "PacketOrder" SG_ 429 TCET_Cltch3 3;
BA_ "SignalType" SG_ 429 TCET_Cltch3 "UNM";
BA_ "VNSigAllNodes" SG_ 429 TCET_Cltch3 1;
BA_ "SignalLongName" SG_ 429 TCET_Cltch2 "Transmission Clutch Estimated Torque : Clutch 2";
BA_ "PacketOrder" SG_ 429 TCET_Cltch2 2;
BA_ "SignalType" SG_ 429 TCET_Cltch2 "UNM";
BA_ "VNSigAllNodes" SG_ 429 TCET_Cltch2 1;
BA_ "SignalLongName" SG_ 429 TCET_Cltch1 "Transmission Clutch Estimated Torque : Clutch 1";
BA_ "PacketOrder" SG_ 429 TCET_Cltch1 1;
BA_ "SignalType" SG_ 429 TCET_Cltch1 "UNM";
BA_ "VNSigAllNodes" SG_ 429 TCET_Cltch1 1;
BA_ "SignalLongName" SG_ 429 TrnsPTSysShtdwnRq "Transmission Powertrain System Shutdown Requested";
BA_ "SignalType" SG_ 429 TrnsPTSysShtdwnRq "BLN";
BA_ "VNSigAllNodes" SG_ 429 TrnsPTSysShtdwnRq 1;
BA_ "SignalLongName" SG_ 429 TransHydrlcDfltgAct "Transmission Hydraulic Defaulting Active";
BA_ "SignalType" SG_ 429 TransHydrlcDfltgAct "BLN";
BA_ "VNSigAllNodes" SG_ 429 TransHydrlcDfltgAct 1;
BA_ "SignalLongName" SG_ 399 ElcTrnsRngSelPrkSysStatPVal "Electronic Transmission Range Select Park System Status Protection Value";
BA_ "SignalType" SG_ 399 ElcTrnsRngSelPrkSysStatPVal "UNM";
BA_ "VNSigAllNodes" SG_ 399 ElcTrnsRngSelPrkSysStatPVal 1;
BA_ "SignalLongName" SG_ 399 ElcTrnsRngSelPrkSysStatARC "Electronic Transmission Range Select Park System Status Alive Rolling Count";
BA_ "SignalType" SG_ 399 ElcTrnsRngSelPrkSysStatARC "UNM";
BA_ "VNSigAllNodes" SG_ 399 ElcTrnsRngSelPrkSysStatARC 1;
BA_ "SignalLongName" SG_ 399 ElcTrnsRngSelPrkSysStat "Electronic Transmission Range Select Park System Status";
BA_ "SignalType" SG_ 399 ElcTrnsRngSelPrkSysStat "ENM";
BA_ "VNSigAllNodes" SG_ 399 ElcTrnsRngSelPrkSysStat 1;
BA_ "SignalLongName" SG_ 399 TrnsPrkSysDiagCrtFltPVal "Transmission Park System Diagnostic Critical Fault Protection Value";
BA_ "SignalType" SG_ 399 TrnsPrkSysDiagCrtFltPVal "UNM";
BA_ "VNSigAllNodes" SG_ 399 TrnsPrkSysDiagCrtFltPVal 1;
BA_ "SignalLongName" SG_ 399 TrnsPrkSysDiagCrtFltARC "Transmission Park System Diagnostic Critical Fault Alive Rolling Count";
BA_ "SignalType" SG_ 399 TrnsPrkSysDiagCrtFltARC "UNM";
BA_ "VNSigAllNodes" SG_ 399 TrnsPrkSysDiagCrtFltARC 1;
BA_ "SignalLongName" SG_ 399 TPSDCF_TrnsPrkSysOOPrkDiaCrtFlt "Transmission Park System Diagnostic Critical Fault : Transmission Park System Out Of Park Diagnostic Critical Fault";
BA_ "PacketOrder" SG_ 399 TPSDCF_TrnsPrkSysOOPrkDiaCrtFlt 2;
BA_ "SignalType" SG_ 399 TPSDCF_TrnsPrkSysOOPrkDiaCrtFlt "BLN";
BA_ "VNSigAllNodes" SG_ 399 TPSDCF_TrnsPrkSysOOPrkDiaCrtFlt 1;
BA_ "SignalLongName" SG_ 399 TPSDCF_TrnsPrkSysPrkDiaCrtFlt "Transmission Park System Diagnostic Critical Fault : Transmission Park System Park Diagnostic Critical Fault";
BA_ "PacketOrder" SG_ 399 TPSDCF_TrnsPrkSysPrkDiaCrtFlt 1;
BA_ "SignalType" SG_ 399 TPSDCF_TrnsPrkSysPrkDiaCrtFlt "BLN";
BA_ "VNSigAllNodes" SG_ 399 TPSDCF_TrnsPrkSysPrkDiaCrtFlt 1;
BA_ "SignalLongName" SG_ 399 TrnsPrkSysDiagLmtdFltPVal "Transmission Park System Diagnostic Limited Fault Protection Value";
BA_ "SignalType" SG_ 399 TrnsPrkSysDiagLmtdFltPVal "UNM";
BA_ "VNSigAllNodes" SG_ 399 TrnsPrkSysDiagLmtdFltPVal 1;
BA_ "SignalLongName" SG_ 399 TrnsPrkSysDiagLmtdFltARC "Transmission Park System Diagnostic Limited Fault Alive Rolling Count";
BA_ "SignalType" SG_ 399 TrnsPrkSysDiagLmtdFltARC "UNM";
BA_ "VNSigAllNodes" SG_ 399 TrnsPrkSysDiagLmtdFltARC 1;
BA_ "SignalLongName" SG_ 399 TPSDLF_TrnsPrkSysOOPrkDiaLmtdFlt "Transmission Park System Diagnostic Limited Fault : Transmission Park System Out Of Park Diagnostic Limited Fault";
BA_ "PacketOrder" SG_ 399 TPSDLF_TrnsPrkSysOOPrkDiaLmtdFlt 2;
BA_ "SignalType" SG_ 399 TPSDLF_TrnsPrkSysOOPrkDiaLmtdFlt "BLN";
BA_ "VNSigAllNodes" SG_ 399 TPSDLF_TrnsPrkSysOOPrkDiaLmtdFlt 1;
BA_ "SignalLongName" SG_ 399 TPSDLF_TrnsPrkSysPrkDiaLmtdFlt "Transmission Park System Diagnostic Limited Fault : Transmission Park System Park Diagnostic Limited Fault";
BA_ "PacketOrder" SG_ 399 TPSDLF_TrnsPrkSysPrkDiaLmtdFlt 1;
BA_ "SignalType" SG_ 399 TPSDLF_TrnsPrkSysPrkDiaLmtdFlt "BLN";
BA_ "VNSigAllNodes" SG_ 399 TPSDLF_TrnsPrkSysPrkDiaLmtdFlt 1;
BA_ "SignalLongName" SG_ 425 TransClch4FlAch "Transmission Clutch 4 Fill Achieved";
BA_ "SignalType" SG_ 425 TransClch4FlAch "BLN";
BA_ "VNSigAllNodes" SG_ 425 TransClch4FlAch 1;
BA_ "SignalLongName" SG_ 425 TransClch5FlTm "Transmission Clutch 5 Fill Time";
BA_ "SignalType" SG_ 425 TransClch5FlTm "UNM";
BA_ "VNSigAllNodes" SG_ 425 TransClch5FlTm 1;
BA_ "SignalLongName" SG_ 425 TransCltch5EstTrq "Transmission Clutch 5 Estimated Torque";
BA_ "SignalType" SG_ 425 TransCltch5EstTrq "UNM";
BA_ "VNSigAllNodes" SG_ 425 TransCltch5EstTrq 1;
BA_ "SignalLongName" SG_ 425 TransClch5MaxEngy "Transmission Clutch 5 Maximum Energy";
BA_ "SignalType" SG_ 425 TransClch5MaxEngy "UNM";
BA_ "VNSigAllNodes" SG_ 425 TransClch5MaxEngy 1;
BA_ "SignalLongName" SG_ 425 TransClch5FlAch "Transmission Clutch 5 Fill Achieved";
BA_ "SignalType" SG_ 425 TransClch5FlAch "BLN";
BA_ "VNSigAllNodes" SG_ 425 TransClch5FlAch 1;
BA_ "SignalLongName" SG_ 425 TransClch4FlTm "Transmission Clutch 4 Fill Time";
BA_ "SignalType" SG_ 425 TransClch4FlTm "UNM";
BA_ "VNSigAllNodes" SG_ 425 TransClch4FlTm 1;
BA_ "SignalLongName" SG_ 425 TransClch4EstTorq "Transmission Clutch 4 Estimated Torque";
BA_ "SignalType" SG_ 425 TransClch4EstTorq "UNM";
BA_ "VNSigAllNodes" SG_ 425 TransClch4EstTorq 1;
BA_ "SignalLongName" SG_ 425 TransClch4MaxEnrgy "Transmission Clutch 4 Maximum Energy";
BA_ "SignalType" SG_ 425 TransClch4MaxEnrgy "UNM";
BA_ "VNSigAllNodes" SG_ 425 TransClch4MaxEnrgy 1;
BA_ "SignalLongName" SG_ 424 TransClch3FlTm "Transmission Clutch 3 Fill Time";
BA_ "SignalType" SG_ 424 TransClch3FlTm "UNM";
BA_ "VNSigAllNodes" SG_ 424 TransClch3FlTm 1;
BA_ "SignalLongName" SG_ 424 TransClch3EstTorq "Transmission Clutch 3 Estimated Torque";
BA_ "SignalType" SG_ 424 TransClch3EstTorq "UNM";
BA_ "VNSigAllNodes" SG_ 424 TransClch3EstTorq 1;
BA_ "SignalLongName" SG_ 424 TransClch3MaxEnrgy "Transmission Clutch 3 Maximum Energy";
BA_ "SignalType" SG_ 424 TransClch3MaxEnrgy "UNM";
BA_ "VNSigAllNodes" SG_ 424 TransClch3MaxEnrgy 1;
BA_ "SignalLongName" SG_ 424 TransClch3FlAch "Transmission Clutch 3 Fill Achieved";
BA_ "SignalType" SG_ 424 TransClch3FlAch "BLN";
BA_ "VNSigAllNodes" SG_ 424 TransClch3FlAch 1;
BA_ "SignalLongName" SG_ 424 TransClch2FlTm "Transmission Clutch 2 Fill Time";
BA_ "SignalType" SG_ 424 TransClch2FlTm "UNM";
BA_ "VNSigAllNodes" SG_ 424 TransClch2FlTm 1;
BA_ "SignalLongName" SG_ 424 TransClch2EstTorq "Transmission Clutch 2 Estimated Torque";
BA_ "SignalType" SG_ 424 TransClch2EstTorq "UNM";
BA_ "VNSigAllNodes" SG_ 424 TransClch2EstTorq 1;
BA_ "SignalLongName" SG_ 424 TransClch2MaxEnrgy "Transmission Clutch 2 Maximum Energy";
BA_ "SignalType" SG_ 424 TransClch2MaxEnrgy "UNM";
BA_ "VNSigAllNodes" SG_ 424 TransClch2MaxEnrgy 1;
BA_ "SignalLongName" SG_ 424 TransClch2FlAch "Transmission Clutch 2 Fill Achieved";
BA_ "SignalType" SG_ 424 TransClch2FlAch "BLN";
BA_ "VNSigAllNodes" SG_ 424 TransClch2FlAch 1;
BA_ "SignalLongName" SG_ 423 TrnsPTSysShtdwnRq "Transmission Powertrain System Shutdown Requested";
BA_ "SignalType" SG_ 423 TrnsPTSysShtdwnRq "BLN";
BA_ "VNSigAllNodes" SG_ 423 TrnsPTSysShtdwnRq 1;
BA_ "SignalLongName" SG_ 423 TransClch1FlTm "Transmission Clutch 1 Fill Time";
BA_ "SignalType" SG_ 423 TransClch1FlTm "UNM";
BA_ "VNSigAllNodes" SG_ 423 TransClch1FlTm 1;
BA_ "SignalLongName" SG_ 423 TransClch1EstTorq "Transmission Clutch 1 Estimated Torque";
BA_ "SignalType" SG_ 423 TransClch1EstTorq "UNM";
BA_ "VNSigAllNodes" SG_ 423 TransClch1EstTorq 1;
BA_ "SignalLongName" SG_ 423 TransClch1MaxEnrgy "Transmission Clutch 1 Maximum Energy";
BA_ "SignalType" SG_ 423 TransClch1MaxEnrgy "UNM";
BA_ "VNSigAllNodes" SG_ 423 TransClch1MaxEnrgy 1;
BA_ "SignalLongName" SG_ 423 TransClch1FlAch "Transmission Clutch 1 Fill Achieved";
BA_ "SignalType" SG_ 423 TransClch1FlAch "BLN";
BA_ "VNSigAllNodes" SG_ 423 TransClch1FlAch 1;
BA_ "SignalLongName" SG_ 423 TransHydrlcDfltgAct "Transmission Hydraulic Defaulting Active";
BA_ "SignalType" SG_ 423 TransHydrlcDfltgAct "BLN";
BA_ "VNSigAllNodes" SG_ 423 TransHydrlcDfltgAct 1;
BA_ "SignalLongName" SG_ 423 TCFS_Cltch5FltStat "Transmission Clutch Fault Status : Clutch 5 Fault Status";
BA_ "PacketOrder" SG_ 423 TCFS_Cltch5FltStat 5;
BA_ "SignalType" SG_ 423 TCFS_Cltch5FltStat "ENM";
BA_ "VNSigAllNodes" SG_ 423 TCFS_Cltch5FltStat 1;
BA_ "SignalLongName" SG_ 423 TCFS_Cltch4FltStat "Transmission Clutch Fault Status : Clutch 4 Fault Status";
BA_ "PacketOrder" SG_ 423 TCFS_Cltch4FltStat 4;
BA_ "SignalType" SG_ 423 TCFS_Cltch4FltStat "ENM";
BA_ "VNSigAllNodes" SG_ 423 TCFS_Cltch4FltStat 1;
BA_ "SignalLongName" SG_ 423 TCFS_Cltch3FltStat "Transmission Clutch Fault Status : Clutch 3 Fault Status";
BA_ "PacketOrder" SG_ 423 TCFS_Cltch3FltStat 3;
BA_ "SignalType" SG_ 423 TCFS_Cltch3FltStat "ENM";
BA_ "VNSigAllNodes" SG_ 423 TCFS_Cltch3FltStat 1;
BA_ "SignalLongName" SG_ 423 TCFS_Cltch2FltStat "Transmission Clutch Fault Status : Clutch 2 Fault Status";
BA_ "PacketOrder" SG_ 423 TCFS_Cltch2FltStat 2;
BA_ "SignalType" SG_ 423 TCFS_Cltch2FltStat "ENM";
BA_ "VNSigAllNodes" SG_ 423 TCFS_Cltch2FltStat 1;
BA_ "SignalLongName" SG_ 423 TCFS_Cltch1FltStat "Transmission Clutch Fault Status : Clutch 1 Fault Status";
BA_ "PacketOrder" SG_ 423 TCFS_Cltch1FltStat 1;
BA_ "SignalType" SG_ 423 TCFS_Cltch1FltStat "ENM";
BA_ "VNSigAllNodes" SG_ 423 TCFS_Cltch1FltStat 1;
BA_ "SignalLongName" SG_ 423 TCAS_Cltch5AvlbltyStat "Transmission Clutch Availability Status : Clutch 5 Availability Status";
BA_ "PacketOrder" SG_ 423 TCAS_Cltch5AvlbltyStat 5;
BA_ "SignalType" SG_ 423 TCAS_Cltch5AvlbltyStat "ENM";
BA_ "VNSigAllNodes" SG_ 423 TCAS_Cltch5AvlbltyStat 1;
BA_ "SignalLongName" SG_ 423 TCAS_Cltch4AvlbltyStat "Transmission Clutch Availability Status : Clutch 4 Availability Status";
BA_ "PacketOrder" SG_ 423 TCAS_Cltch4AvlbltyStat 4;
BA_ "SignalType" SG_ 423 TCAS_Cltch4AvlbltyStat "ENM";
BA_ "VNSigAllNodes" SG_ 423 TCAS_Cltch4AvlbltyStat 1;
BA_ "SignalLongName" SG_ 423 TCAS_Cltch3AvlbltyStat "Transmission Clutch Availability Status : Clutch 3 Availability Status";
BA_ "PacketOrder" SG_ 423 TCAS_Cltch3AvlbltyStat 3;
BA_ "SignalType" SG_ 423 TCAS_Cltch3AvlbltyStat "ENM";
BA_ "VNSigAllNodes" SG_ 423 TCAS_Cltch3AvlbltyStat 1;
BA_ "SignalLongName" SG_ 423 TCAS_Cltch2AvlbltyStat "Transmission Clutch Availability Status : Clutch 2 Availability Status";
BA_ "PacketOrder" SG_ 423 TCAS_Cltch2AvlbltyStat 2;
BA_ "SignalType" SG_ 423 TCAS_Cltch2AvlbltyStat "ENM";
BA_ "VNSigAllNodes" SG_ 423 TCAS_Cltch2AvlbltyStat 1;
BA_ "SignalLongName" SG_ 423 TCAS_Cltch1AvlbltyStat "Transmission Clutch Availability Status : Clutch 1 Availability Status";
BA_ "PacketOrder" SG_ 423 TCAS_Cltch1AvlbltyStat 1;
BA_ "SignalType" SG_ 423 TCAS_Cltch1AvlbltyStat "ENM";
BA_ "VNSigAllNodes" SG_ 423 TCAS_Cltch1AvlbltyStat 1;
BA_ "SignalLongName" SG_ 901 TrnsMtrBCoolFlwEst "Transmission Motor B Cooling Flow Estimated";
BA_ "SignalType" SG_ 901 TrnsMtrBCoolFlwEst "UNM";
BA_ "VNSigAllNodes" SG_ 901 TrnsMtrBCoolFlwEst 1;
BA_ "SignalLongName" SG_ 901 TrnsMtrACoolFlwEst "Transmission Motor A Cooling Flow Estimated";
BA_ "SignalType" SG_ 901 TrnsMtrACoolFlwEst "UNM";
BA_ "VNSigAllNodes" SG_ 901 TrnsMtrACoolFlwEst 1;
BA_ "SignalLongName" SG_ 901 TrnsLubeFlwEst "Transmission Lube Flow Estimated";
BA_ "SignalType" SG_ 901 TrnsLubeFlwEst "UNM";
BA_ "VNSigAllNodes" SG_ 901 TrnsLubeFlwEst 1;
BA_ "SignalLongName" SG_ 1919 DTCI_DTCFaultType_77F "Diagnostic Trouble Code Information Extended 77F : Diagnostic Trouble Code Fault Type";
BA_ "PacketOrder" SG_ 1919 DTCI_DTCFaultType_77F 20;
BA_ "SignalType" SG_ 1919 DTCI_DTCFaultType_77F "ENM";
BA_ "VNSigAllNodes" SG_ 1919 DTCI_DTCFaultType_77F 1;
BA_ "SignalLongName" SG_ 1919 DTCI_CodeSupported_77F "Diagnostic Trouble Code Information Extended 77F : Code Supported";
BA_ "PacketOrder" SG_ 1919 DTCI_CodeSupported_77F 19;
BA_ "SignalType" SG_ 1919 DTCI_CodeSupported_77F "BLN";
BA_ "VNSigAllNodes" SG_ 1919 DTCI_CodeSupported_77F 1;
BA_ "SignalLongName" SG_ 1919 DTCI_CurrentStatus_77F "Diagnostic Trouble Code Information Extended 77F : Current Status";
BA_ "PacketOrder" SG_ 1919 DTCI_CurrentStatus_77F 18;
BA_ "SignalType" SG_ 1919 DTCI_CurrentStatus_77F "BLN";
BA_ "VNSigAllNodes" SG_ 1919 DTCI_CurrentStatus_77F 1;
BA_ "SignalLongName" SG_ 1919 DTCI_TstNPsdCdClrdSt_77F "Diagnostic Trouble Code Information Extended 77F : Test Not Passed Since Code Cleared Status";
BA_ "PacketOrder" SG_ 1919 DTCI_TstNPsdCdClrdSt_77F 17;
BA_ "SignalType" SG_ 1919 DTCI_TstNPsdCdClrdSt_77F "BLN";
BA_ "VNSigAllNodes" SG_ 1919 DTCI_TstNPsdCdClrdSt_77F 1;
BA_ "SignalLongName" SG_ 1919 DTCI_TstFldCdClrdStat_77F "Diagnostic Trouble Code Information Extended 77F : Test Failed Since Code Cleared Status";
BA_ "PacketOrder" SG_ 1919 DTCI_TstFldCdClrdStat_77F 16;
BA_ "SignalType" SG_ 1919 DTCI_TstFldCdClrdStat_77F "BLN";
BA_ "VNSigAllNodes" SG_ 1919 DTCI_TstFldCdClrdStat_77F 1;
BA_ "SignalLongName" SG_ 1919 DTCI_HistStat_77F "Diagnostic Trouble Code Information Extended 77F : History Status";
BA_ "PacketOrder" SG_ 1919 DTCI_HistStat_77F 15;
BA_ "SignalType" SG_ 1919 DTCI_HistStat_77F "BLN";
BA_ "VNSigAllNodes" SG_ 1919 DTCI_HistStat_77F 1;
BA_ "SignalLongName" SG_ 1919 DTCI_TstNPsdPwrUpSt_77F "Diagnostic Trouble Code Information Extended 77F : Test Not Passed Since Power Up Status";
BA_ "PacketOrder" SG_ 1919 DTCI_TstNPsdPwrUpSt_77F 14;
BA_ "SignalType" SG_ 1919 DTCI_TstNPsdPwrUpSt_77F "BLN";
BA_ "VNSigAllNodes" SG_ 1919 DTCI_TstNPsdPwrUpSt_77F 1;
BA_ "SignalLongName" SG_ 1919 DTCI_TstFldPwrUpSt_77F "Diagnostic Trouble Code Information Extended 77F : Test Failed Since Power Up Status";
BA_ "PacketOrder" SG_ 1919 DTCI_TstFldPwrUpSt_77F 13;
BA_ "SignalType" SG_ 1919 DTCI_TstFldPwrUpSt_77F "BLN";
BA_ "VNSigAllNodes" SG_ 1919 DTCI_TstFldPwrUpSt_77F 1;
BA_ "SignalLongName" SG_ 1919 DTCI_WrnIndRqdSt_77F "Diagnostic Trouble Code Information Extended 77F : Warning Indicator Requested Status";
BA_ "PacketOrder" SG_ 1919 DTCI_WrnIndRqdSt_77F 12;
BA_ "SignalType" SG_ 1919 DTCI_WrnIndRqdSt_77F "BLN";
BA_ "VNSigAllNodes" SG_ 1919 DTCI_WrnIndRqdSt_77F 1;
BA_ "SignalLongName" SG_ 1919 DTCI_DTCFailType_77F "Diagnostic Trouble Code Information Extended 77F : Diagnostic Trouble Code Failure Type";
BA_ "PacketOrder" SG_ 1919 DTCI_DTCFailType_77F 11;
BA_ "SignalType" SG_ 1919 DTCI_DTCFailType_77F "UNM";
BA_ "VNSigAllNodes" SG_ 1919 DTCI_DTCFailType_77F 1;
BA_ "SignalLongName" SG_ 1919 DTCI_DTCNumber_77F "Diagnostic Trouble Code Information Extended 77F : Diagnostic Trouble Code Number";
BA_ "PacketOrder" SG_ 1919 DTCI_DTCNumber_77F 10;
BA_ "SignalType" SG_ 1919 DTCI_DTCNumber_77F "UNM";
BA_ "VNSigAllNodes" SG_ 1919 DTCI_DTCNumber_77F 1;
BA_ "SignalLongName" SG_ 1919 DTCI_DTCSource_77F "Diagnostic Trouble Code Information Extended 77F : Diagnostic Trouble Code Source";
BA_ "PacketOrder" SG_ 1919 DTCI_DTCSource_77F 9;
BA_ "SignalType" SG_ 1919 DTCI_DTCSource_77F "UNM";
BA_ "VNSigAllNodes" SG_ 1919 DTCI_DTCSource_77F 1;
BA_ "SignalLongName" SG_ 1919 DTCI_DTCTriggered_77F "Diagnostic Trouble Code Information Extended 77F : Diagnostic Trouble Code Triggered";
BA_ "PacketOrder" SG_ 1919 DTCI_DTCTriggered_77F 8;
BA_ "SignalType" SG_ 1919 DTCI_DTCTriggered_77F "BLN";
BA_ "VNSigAllNodes" SG_ 1919 DTCI_DTCTriggered_77F 1;
BA_ "SignalLongName" SG_ 1919 DTCIUnused7_77F "Diagnostic Trouble Code Information Extended 77F : Unused 7";
BA_ "PacketOrder" SG_ 1919 DTCIUnused7_77F 7;
BA_ "SignalType" SG_ 1919 DTCIUnused7_77F "BLN";
BA_ "VNSigAllNodes" SG_ 1919 DTCIUnused7_77F 1;
BA_ "SignalLongName" SG_ 1919 DTCIUnused6_77F "Diagnostic Trouble Code Information Extended 77F : Unused 6";
BA_ "PacketOrder" SG_ 1919 DTCIUnused6_77F 6;
BA_ "SignalType" SG_ 1919 DTCIUnused6_77F "BLN";
BA_ "VNSigAllNodes" SG_ 1919 DTCIUnused6_77F 1;
BA_ "SignalLongName" SG_ 1919 DTCIUnused5_77F "Diagnostic Trouble Code Information Extended 77F : Unused 5";
BA_ "PacketOrder" SG_ 1919 DTCIUnused5_77F 5;
BA_ "SignalType" SG_ 1919 DTCIUnused5_77F "BLN";
BA_ "VNSigAllNodes" SG_ 1919 DTCIUnused5_77F 1;
BA_ "SignalLongName" SG_ 1919 DTCIUnused4_77F "Diagnostic Trouble Code Information Extended 77F : Unused 4";
BA_ "PacketOrder" SG_ 1919 DTCIUnused4_77F 4;
BA_ "SignalType" SG_ 1919 DTCIUnused4_77F "BLN";
BA_ "VNSigAllNodes" SG_ 1919 DTCIUnused4_77F 1;
BA_ "SignalLongName" SG_ 1919 DTCIUnused3_77F "Diagnostic Trouble Code Information Extended 77F : Unused 3";
BA_ "PacketOrder" SG_ 1919 DTCIUnused3_77F 3;
BA_ "SignalType" SG_ 1919 DTCIUnused3_77F "BLN";
BA_ "VNSigAllNodes" SG_ 1919 DTCIUnused3_77F 1;
BA_ "SignalLongName" SG_ 1919 DTCIUnused2_77F "Diagnostic Trouble Code Information Extended 77F : Unused 2";
BA_ "PacketOrder" SG_ 1919 DTCIUnused2_77F 2;
BA_ "SignalType" SG_ 1919 DTCIUnused2_77F "BLN";
BA_ "VNSigAllNodes" SG_ 1919 DTCIUnused2_77F 1;
BA_ "SignalLongName" SG_ 1919 DTCIUnused1_77F "Diagnostic Trouble Code Information Extended 77F : Unused 1";
BA_ "PacketOrder" SG_ 1919 DTCIUnused1_77F 1;
BA_ "SignalType" SG_ 1919 DTCIUnused1_77F "BLN";
BA_ "VNSigAllNodes" SG_ 1919 DTCIUnused1_77F 1;
BA_ "SignalLongName" SG_ 2026 DgnInf "Diagnostic Information";
BA_ "SignalType" SG_ 2026 DgnInf "UNM";
BA_ "VNSigSLHSSharedDiagnostic" SG_ 2026 DgnInf 1;
BA_ "VNSigAllNodes" SG_ 2026 DgnInf 1;
BA_ "GenSigDeltaValue" SG_ 2026 DgnInf 1;
BA_ "GenSigSendType" SG_ 2026 DgnInf 12;
BA_ "SignalLongName" SG_ 1514 DgnInf "Diagnostic Information";
BA_ "SignalType" SG_ 1514 DgnInf "UNM";
BA_ "VNSigSLHSSharedDiagnostic" SG_ 1514 DgnInf 1;
BA_ "VNSigAllNodes" SG_ 1514 DgnInf 1;
BA_ "GenSigDeltaValue" SG_ 1514 DgnInf 1;
BA_ "GenSigSendType" SG_ 1514 DgnInf 12;
BA_ "SignalLongName" SG_ 1801 DgnInf "Diagnostic Information";
BA_ "SignalType" SG_ 1801 DgnInf "UNM";
BA_ "VNSigSLHSSharedDiagnostic" SG_ 1801 DgnInf 1;
BA_ "VNSigAllNodes" SG_ 1801 DgnInf 1;
BA_ "GenSigDeltaValue" SG_ 1801 DgnInf 1;
BA_ "GenSigSendType" SG_ 1801 DgnInf 12;
BA_ "SignalLongName" SG_ 591 DgnInf "Diagnostic Information";
BA_ "SignalType" SG_ 591 DgnInf "UNM";
BA_ "VNSigSLHSSharedDiagnostic" SG_ 591 DgnInf 1;
BA_ "VNSigAllNodes" SG_ 591 DgnInf 1;
BA_ "GenSigDeltaValue" SG_ 591 DgnInf 1;
BA_ "GenSigSendType" SG_ 591 DgnInf 12;
BA_ "SignalLongName" SG_ 1799 DgnInf "Diagnostic Information";
BA_ "SignalType" SG_ 1799 DgnInf "UNM";
BA_ "VNSigSLHSSharedDiagnostic" SG_ 1799 DgnInf 1;
BA_ "VNSigAllNodes" SG_ 1799 DgnInf 1;
BA_ "GenSigDeltaValue" SG_ 1799 DgnInf 1;
BA_ "GenSigSendType" SG_ 1799 DgnInf 12;
BA_ "SignalLongName" SG_ 1359 DgnInf_HS54F "Diagnostic Information HS54F";
BA_ "SignalType" SG_ 1359 DgnInf_HS54F "UNM";
BA_ "VNSigSLHSSharedDiagnostic" SG_ 1359 DgnInf_HS54F 1;
BA_ "VNSigAllNodes" SG_ 1359 DgnInf_HS54F 1;
BA_ "SignalLongName" SG_ 1914 DTCI_DTCFaultType_77A "Diagnostic Trouble Code Information Extended 77A : Diagnostic Trouble Code Fault Type";
BA_ "PacketOrder" SG_ 1914 DTCI_DTCFaultType_77A 20;
BA_ "SignalType" SG_ 1914 DTCI_DTCFaultType_77A "ENM";
BA_ "VNSigAllNodes" SG_ 1914 DTCI_DTCFaultType_77A 1;
BA_ "SignalLongName" SG_ 1914 DTCI_CodeSupported_77A "Diagnostic Trouble Code Information Extended 77A : Code Supported";
BA_ "PacketOrder" SG_ 1914 DTCI_CodeSupported_77A 19;
BA_ "SignalType" SG_ 1914 DTCI_CodeSupported_77A "BLN";
BA_ "VNSigAllNodes" SG_ 1914 DTCI_CodeSupported_77A 1;
BA_ "SignalLongName" SG_ 1914 DTCI_CurrentStatus_77A "Diagnostic Trouble Code Information Extended 77A : Current Status";
BA_ "PacketOrder" SG_ 1914 DTCI_CurrentStatus_77A 18;
BA_ "SignalType" SG_ 1914 DTCI_CurrentStatus_77A "BLN";
BA_ "VNSigAllNodes" SG_ 1914 DTCI_CurrentStatus_77A 1;
BA_ "SignalLongName" SG_ 1914 DTCI_TstNPsdCdClrdSt_77A "Diagnostic Trouble Code Information Extended 77A : Test Not Passed Since Code Cleared Status";
BA_ "PacketOrder" SG_ 1914 DTCI_TstNPsdCdClrdSt_77A 17;
BA_ "SignalType" SG_ 1914 DTCI_TstNPsdCdClrdSt_77A "BLN";
BA_ "VNSigAllNodes" SG_ 1914 DTCI_TstNPsdCdClrdSt_77A 1;
BA_ "SignalLongName" SG_ 1914 DTCI_TstFldCdClrdStat_77A "Diagnostic Trouble Code Information Extended 77A : Test Failed Since Code Cleared Status";
BA_ "PacketOrder" SG_ 1914 DTCI_TstFldCdClrdStat_77A 16;
BA_ "SignalType" SG_ 1914 DTCI_TstFldCdClrdStat_77A "BLN";
BA_ "VNSigAllNodes" SG_ 1914 DTCI_TstFldCdClrdStat_77A 1;
BA_ "SignalLongName" SG_ 1914 DTCI_HistStat_77A "Diagnostic Trouble Code Information Extended 77A : History Status";
BA_ "PacketOrder" SG_ 1914 DTCI_HistStat_77A 15;
BA_ "SignalType" SG_ 1914 DTCI_HistStat_77A "BLN";
BA_ "VNSigAllNodes" SG_ 1914 DTCI_HistStat_77A 1;
BA_ "SignalLongName" SG_ 1914 DTCI_TstNPsdPwrUpSt_77A "Diagnostic Trouble Code Information Extended 77A : Test Not Passed Since Power Up Status";
BA_ "PacketOrder" SG_ 1914 DTCI_TstNPsdPwrUpSt_77A 14;
BA_ "SignalType" SG_ 1914 DTCI_TstNPsdPwrUpSt_77A "BLN";
BA_ "VNSigAllNodes" SG_ 1914 DTCI_TstNPsdPwrUpSt_77A 1;
BA_ "SignalLongName" SG_ 1914 DTCI_TstFldPwrUpSt_77A "Diagnostic Trouble Code Information Extended 77A : Test Failed Since Power Up Status";
BA_ "PacketOrder" SG_ 1914 DTCI_TstFldPwrUpSt_77A 13;
BA_ "SignalType" SG_ 1914 DTCI_TstFldPwrUpSt_77A "BLN";
BA_ "VNSigAllNodes" SG_ 1914 DTCI_TstFldPwrUpSt_77A 1;
BA_ "SignalLongName" SG_ 1914 DTCI_WrnIndRqdSt_77A "Diagnostic Trouble Code Information Extended 77A : Warning Indicator Requested Status";
BA_ "PacketOrder" SG_ 1914 DTCI_WrnIndRqdSt_77A 12;
BA_ "SignalType" SG_ 1914 DTCI_WrnIndRqdSt_77A "BLN";
BA_ "VNSigAllNodes" SG_ 1914 DTCI_WrnIndRqdSt_77A 1;
BA_ "SignalLongName" SG_ 1914 DTCI_DTCFailType_77A "Diagnostic Trouble Code Information Extended 77A : Diagnostic Trouble Code Failure Type";
BA_ "PacketOrder" SG_ 1914 DTCI_DTCFailType_77A 11;
BA_ "SignalType" SG_ 1914 DTCI_DTCFailType_77A "UNM";
BA_ "VNSigAllNodes" SG_ 1914 DTCI_DTCFailType_77A 1;
BA_ "SignalLongName" SG_ 1914 DTCI_DTCNumber_77A "Diagnostic Trouble Code Information Extended 77A : Diagnostic Trouble Code Number";
BA_ "PacketOrder" SG_ 1914 DTCI_DTCNumber_77A 10;
BA_ "SignalType" SG_ 1914 DTCI_DTCNumber_77A "UNM";
BA_ "VNSigAllNodes" SG_ 1914 DTCI_DTCNumber_77A 1;
BA_ "SignalLongName" SG_ 1914 DTCI_DTCSource_77A "Diagnostic Trouble Code Information Extended 77A : Diagnostic Trouble Code Source";
BA_ "PacketOrder" SG_ 1914 DTCI_DTCSource_77A 9;
BA_ "SignalType" SG_ 1914 DTCI_DTCSource_77A "UNM";
BA_ "VNSigAllNodes" SG_ 1914 DTCI_DTCSource_77A 1;
BA_ "SignalLongName" SG_ 1914 DTCI_DTCTriggered_77A "Diagnostic Trouble Code Information Extended 77A : Diagnostic Trouble Code Triggered";
BA_ "PacketOrder" SG_ 1914 DTCI_DTCTriggered_77A 8;
BA_ "SignalType" SG_ 1914 DTCI_DTCTriggered_77A "BLN";
BA_ "VNSigAllNodes" SG_ 1914 DTCI_DTCTriggered_77A 1;
BA_ "SignalLongName" SG_ 1914 DTCIUnused7_77A "Diagnostic Trouble Code Information Extended 77A : Unused 7";
BA_ "PacketOrder" SG_ 1914 DTCIUnused7_77A 7;
BA_ "SignalType" SG_ 1914 DTCIUnused7_77A "BLN";
BA_ "VNSigAllNodes" SG_ 1914 DTCIUnused7_77A 1;
BA_ "SignalLongName" SG_ 1914 DTCIUnused6_77A "Diagnostic Trouble Code Information Extended 77A : Unused 6";
BA_ "PacketOrder" SG_ 1914 DTCIUnused6_77A 6;
BA_ "SignalType" SG_ 1914 DTCIUnused6_77A "BLN";
BA_ "VNSigAllNodes" SG_ 1914 DTCIUnused6_77A 1;
BA_ "SignalLongName" SG_ 1914 DTCIUnused5_77A "Diagnostic Trouble Code Information Extended 77A : Unused 5";
BA_ "PacketOrder" SG_ 1914 DTCIUnused5_77A 5;
BA_ "SignalType" SG_ 1914 DTCIUnused5_77A "BLN";
BA_ "VNSigAllNodes" SG_ 1914 DTCIUnused5_77A 1;
BA_ "SignalLongName" SG_ 1914 DTCIUnused4_77A "Diagnostic Trouble Code Information Extended 77A : Unused 4";
BA_ "PacketOrder" SG_ 1914 DTCIUnused4_77A 4;
BA_ "SignalType" SG_ 1914 DTCIUnused4_77A "BLN";
BA_ "VNSigAllNodes" SG_ 1914 DTCIUnused4_77A 1;
BA_ "SignalLongName" SG_ 1914 DTCIUnused3_77A "Diagnostic Trouble Code Information Extended 77A : Unused 3";
BA_ "PacketOrder" SG_ 1914 DTCIUnused3_77A 3;
BA_ "SignalType" SG_ 1914 DTCIUnused3_77A "BLN";
BA_ "VNSigAllNodes" SG_ 1914 DTCIUnused3_77A 1;
BA_ "SignalLongName" SG_ 1914 DTCIUnused2_77A "Diagnostic Trouble Code Information Extended 77A : Unused 2";
BA_ "PacketOrder" SG_ 1914 DTCIUnused2_77A 2;
BA_ "SignalType" SG_ 1914 DTCIUnused2_77A "BLN";
BA_ "VNSigAllNodes" SG_ 1914 DTCIUnused2_77A 1;
BA_ "SignalLongName" SG_ 1914 DTCIUnused1_77A "Diagnostic Trouble Code Information Extended 77A : Unused 1";
BA_ "PacketOrder" SG_ 1914 DTCIUnused1_77A 1;
BA_ "SignalType" SG_ 1914 DTCIUnused1_77A "BLN";
BA_ "VNSigAllNodes" SG_ 1914 DTCIUnused1_77A 1;
BA_ "SignalLongName" SG_ 1615 DgnInf "Diagnostic Information";
BA_ "SignalType" SG_ 1615 DgnInf "UNM";
BA_ "VNSigSLHSSharedDiagnostic" SG_ 1615 DgnInf 1;
BA_ "VNSigAllNodes" SG_ 1615 DgnInf 1;
BA_ "GenSigDeltaValue" SG_ 1615 DgnInf 1;
BA_ "GenSigSendType" SG_ 1615 DgnInf 12;
BA_ "SignalLongName" SG_ 1800 DgnInf "Diagnostic Information";
BA_ "SignalType" SG_ 1800 DgnInf "UNM";
BA_ "VNSigSLHSSharedDiagnostic" SG_ 1800 DgnInf 1;
BA_ "VNSigAllNodes" SG_ 1800 DgnInf 1;
BA_ "GenSigDeltaValue" SG_ 1800 DgnInf 1;
BA_ "GenSigSendType" SG_ 1800 DgnInf 12;
BA_ "SignalLongName" SG_ 1810 DgnInf "Diagnostic Information";
BA_ "SignalType" SG_ 1810 DgnInf "UNM";
BA_ "VNSigSLHSSharedDiagnostic" SG_ 1810 DgnInf 1;
BA_ "VNSigAllNodes" SG_ 1810 DgnInf 1;
BA_ "GenSigDeltaValue" SG_ 1810 DgnInf 1;
BA_ "GenSigSendType" SG_ 1810 DgnInf 12;
BA_ "SignalLongName" SG_ 578 DgnInf "Diagnostic Information";
BA_ "SignalType" SG_ 578 DgnInf "UNM";
BA_ "VNSigSLHSSharedDiagnostic" SG_ 578 DgnInf 1;
BA_ "VNSigAllNodes" SG_ 578 DgnInf 1;
BA_ "GenSigDeltaValue" SG_ 578 DgnInf 1;
BA_ "GenSigSendType" SG_ 578 DgnInf 12;
BA_ "SignalLongName" SG_ 1798 DgnInf "Diagnostic Information";
BA_ "SignalType" SG_ 1798 DgnInf "UNM";
BA_ "VNSigSLHSSharedDiagnostic" SG_ 1798 DgnInf 1;
BA_ "VNSigAllNodes" SG_ 1798 DgnInf 1;
BA_ "GenSigDeltaValue" SG_ 1798 DgnInf 1;
BA_ "GenSigSendType" SG_ 1798 DgnInf 12;
BA_ "SignalLongName" SG_ 1808 DgnInf "Diagnostic Information";
BA_ "SignalType" SG_ 1808 DgnInf "UNM";
BA_ "VNSigSLHSSharedDiagnostic" SG_ 1808 DgnInf 1;
BA_ "VNSigAllNodes" SG_ 1808 DgnInf 1;
BA_ "GenSigDeltaValue" SG_ 1808 DgnInf 1;
BA_ "GenSigSendType" SG_ 1808 DgnInf 12;
BA_ "SignalLongName" SG_ 1912 DTCI_DTCFaultType_778 "Diagnostic Trouble Code Information Extended 778 : Diagnostic Trouble Code Fault Type";
BA_ "PacketOrder" SG_ 1912 DTCI_DTCFaultType_778 20;
BA_ "SignalType" SG_ 1912 DTCI_DTCFaultType_778 "ENM";
BA_ "VNSigAllNodes" SG_ 1912 DTCI_DTCFaultType_778 1;
BA_ "SignalLongName" SG_ 1912 DTCI_CodeSupported_778 "Diagnostic Trouble Code Information Extended 778 : Code Supported";
BA_ "PacketOrder" SG_ 1912 DTCI_CodeSupported_778 19;
BA_ "SignalType" SG_ 1912 DTCI_CodeSupported_778 "BLN";
BA_ "VNSigAllNodes" SG_ 1912 DTCI_CodeSupported_778 1;
BA_ "SignalLongName" SG_ 1912 DTCI_CurrentStatus_778 "Diagnostic Trouble Code Information Extended 778 : Current Status";
BA_ "PacketOrder" SG_ 1912 DTCI_CurrentStatus_778 18;
BA_ "SignalType" SG_ 1912 DTCI_CurrentStatus_778 "BLN";
BA_ "VNSigAllNodes" SG_ 1912 DTCI_CurrentStatus_778 1;
BA_ "SignalLongName" SG_ 1912 DTCI_TstNPsdCdClrdSt_778 "Diagnostic Trouble Code Information Extended 778 : Test Not Passed Since Code Cleared Status";
BA_ "PacketOrder" SG_ 1912 DTCI_TstNPsdCdClrdSt_778 17;
BA_ "SignalType" SG_ 1912 DTCI_TstNPsdCdClrdSt_778 "BLN";
BA_ "VNSigAllNodes" SG_ 1912 DTCI_TstNPsdCdClrdSt_778 1;
BA_ "SignalLongName" SG_ 1912 DTCI_TstFldCdClrdStat_778 "Diagnostic Trouble Code Information Extended 778 : Test Failed Since Code Cleared Status";
BA_ "PacketOrder" SG_ 1912 DTCI_TstFldCdClrdStat_778 16;
BA_ "SignalType" SG_ 1912 DTCI_TstFldCdClrdStat_778 "BLN";
BA_ "VNSigAllNodes" SG_ 1912 DTCI_TstFldCdClrdStat_778 1;
BA_ "SignalLongName" SG_ 1912 DTCI_HistStat_778 "Diagnostic Trouble Code Information Extended 778 : History Status";
BA_ "PacketOrder" SG_ 1912 DTCI_HistStat_778 15;
BA_ "SignalType" SG_ 1912 DTCI_HistStat_778 "BLN";
BA_ "VNSigAllNodes" SG_ 1912 DTCI_HistStat_778 1;
BA_ "SignalLongName" SG_ 1912 DTCI_TstNPsdPwrUpSt_778 "Diagnostic Trouble Code Information Extended 778 : Test Not Passed Since Power Up Status";
BA_ "PacketOrder" SG_ 1912 DTCI_TstNPsdPwrUpSt_778 14;
BA_ "SignalType" SG_ 1912 DTCI_TstNPsdPwrUpSt_778 "BLN";
BA_ "VNSigAllNodes" SG_ 1912 DTCI_TstNPsdPwrUpSt_778 1;
BA_ "SignalLongName" SG_ 1912 DTCI_TstFldPwrUpSt_778 "Diagnostic Trouble Code Information Extended 778 : Test Failed Since Power Up Status";
BA_ "PacketOrder" SG_ 1912 DTCI_TstFldPwrUpSt_778 13;
BA_ "SignalType" SG_ 1912 DTCI_TstFldPwrUpSt_778 "BLN";
BA_ "VNSigAllNodes" SG_ 1912 DTCI_TstFldPwrUpSt_778 1;
BA_ "SignalLongName" SG_ 1912 DTCI_WrnIndRqdSt_778 "Diagnostic Trouble Code Information Extended 778 : Warning Indicator Requested Status";
BA_ "PacketOrder" SG_ 1912 DTCI_WrnIndRqdSt_778 12;
BA_ "SignalType" SG_ 1912 DTCI_WrnIndRqdSt_778 "BLN";
BA_ "VNSigAllNodes" SG_ 1912 DTCI_WrnIndRqdSt_778 1;
BA_ "SignalLongName" SG_ 1912 DTCI_DTCFailType_778 "Diagnostic Trouble Code Information Extended 778 : Diagnostic Trouble Code Failure Type";
BA_ "PacketOrder" SG_ 1912 DTCI_DTCFailType_778 11;
BA_ "SignalType" SG_ 1912 DTCI_DTCFailType_778 "UNM";
BA_ "VNSigAllNodes" SG_ 1912 DTCI_DTCFailType_778 1;
BA_ "SignalLongName" SG_ 1912 DTCI_DTCNumber_778 "Diagnostic Trouble Code Information Extended 778 : Diagnostic Trouble Code Number";
BA_ "PacketOrder" SG_ 1912 DTCI_DTCNumber_778 10;
BA_ "SignalType" SG_ 1912 DTCI_DTCNumber_778 "UNM";
BA_ "VNSigAllNodes" SG_ 1912 DTCI_DTCNumber_778 1;
BA_ "SignalLongName" SG_ 1912 DTCI_DTCSource_778 "Diagnostic Trouble Code Information Extended 778 : Diagnostic Trouble Code Source";
BA_ "PacketOrder" SG_ 1912 DTCI_DTCSource_778 9;
BA_ "SignalType" SG_ 1912 DTCI_DTCSource_778 "UNM";
BA_ "VNSigAllNodes" SG_ 1912 DTCI_DTCSource_778 1;
BA_ "SignalLongName" SG_ 1912 DTCI_DTCTriggered_778 "Diagnostic Trouble Code Information Extended 778 : Diagnostic Trouble Code Triggered";
BA_ "PacketOrder" SG_ 1912 DTCI_DTCTriggered_778 8;
BA_ "SignalType" SG_ 1912 DTCI_DTCTriggered_778 "BLN";
BA_ "VNSigAllNodes" SG_ 1912 DTCI_DTCTriggered_778 1;
BA_ "SignalLongName" SG_ 1912 DTCIUnused7_778 "Diagnostic Trouble Code Information Extended 778 : Unused 7";
BA_ "PacketOrder" SG_ 1912 DTCIUnused7_778 7;
BA_ "SignalType" SG_ 1912 DTCIUnused7_778 "BLN";
BA_ "VNSigAllNodes" SG_ 1912 DTCIUnused7_778 1;
BA_ "SignalLongName" SG_ 1912 DTCIUnused6_778 "Diagnostic Trouble Code Information Extended 778 : Unused 6";
BA_ "PacketOrder" SG_ 1912 DTCIUnused6_778 6;
BA_ "SignalType" SG_ 1912 DTCIUnused6_778 "BLN";
BA_ "VNSigAllNodes" SG_ 1912 DTCIUnused6_778 1;
BA_ "SignalLongName" SG_ 1912 DTCIUnused5_778 "Diagnostic Trouble Code Information Extended 778 : Unused 5";
BA_ "PacketOrder" SG_ 1912 DTCIUnused5_778 5;
BA_ "SignalType" SG_ 1912 DTCIUnused5_778 "BLN";
BA_ "VNSigAllNodes" SG_ 1912 DTCIUnused5_778 1;
BA_ "SignalLongName" SG_ 1912 DTCIUnused4_778 "Diagnostic Trouble Code Information Extended 778 : Unused 4";
BA_ "PacketOrder" SG_ 1912 DTCIUnused4_778 4;
BA_ "SignalType" SG_ 1912 DTCIUnused4_778 "BLN";
BA_ "VNSigAllNodes" SG_ 1912 DTCIUnused4_778 1;
BA_ "SignalLongName" SG_ 1912 DTCIUnused3_778 "Diagnostic Trouble Code Information Extended 778 : Unused 3";
BA_ "PacketOrder" SG_ 1912 DTCIUnused3_778 3;
BA_ "SignalType" SG_ 1912 DTCIUnused3_778 "BLN";
BA_ "VNSigAllNodes" SG_ 1912 DTCIUnused3_778 1;
BA_ "SignalLongName" SG_ 1912 DTCIUnused2_778 "Diagnostic Trouble Code Information Extended 778 : Unused 2";
BA_ "PacketOrder" SG_ 1912 DTCIUnused2_778 2;
BA_ "SignalType" SG_ 1912 DTCIUnused2_778 "BLN";
BA_ "VNSigAllNodes" SG_ 1912 DTCIUnused2_778 1;
BA_ "SignalLongName" SG_ 1912 DTCIUnused1_778 "Diagnostic Trouble Code Information Extended 778 : Unused 1";
BA_ "PacketOrder" SG_ 1912 DTCIUnused1_778 1;
BA_ "SignalType" SG_ 1912 DTCIUnused1_778 "BLN";
BA_ "VNSigAllNodes" SG_ 1912 DTCIUnused1_778 1;
BA_ "SignalLongName" SG_ 1346 DgnInf_HS542 "Diagnostic Information HS542";
BA_ "SignalType" SG_ 1346 DgnInf_HS542 "UNM";
BA_ "VNSigSLHSSharedDiagnostic" SG_ 1346 DgnInf_HS542 1;
BA_ "VNSigAllNodes" SG_ 1346 DgnInf_HS542 1;
BA_ "SignalLongName" SG_ 1602 DgnInf "Diagnostic Information";
BA_ "SignalType" SG_ 1602 DgnInf "UNM";
BA_ "VNSigSLHSSharedDiagnostic" SG_ 1602 DgnInf 1;
BA_ "VNSigAllNodes" SG_ 1602 DgnInf 1;
BA_ "GenSigDeltaValue" SG_ 1602 DgnInf 1;
BA_ "GenSigSendType" SG_ 1602 DgnInf 12;
BA_ "SignalLongName" SG_ 388 LKADrvAppldTrq "Lane Keeping Assist Driver Applied Torque";
BA_ "SignalType" SG_ 388 LKADrvAppldTrq "SNM";
BA_ "VNSigAllNodes" SG_ 388 LKADrvAppldTrq 1;
BA_ "SignalLongName" SG_ 388 HndsOffStrWhlDtStV "Hands Off Steering Wheel Detection State Validity";
BA_ "SignalType" SG_ 388 HndsOffStrWhlDtStV "ENM";
BA_ "VNSigAllNodes" SG_ 388 HndsOffStrWhlDtStV 1;
BA_ "SignalLongName" SG_ 388 HndsOffStrWhlDtSt "Hands Off Steering Wheel Detection State";
BA_ "SignalType" SG_ 388 HndsOffStrWhlDtSt "ENM";
BA_ "VNSigAllNodes" SG_ 388 HndsOffStrWhlDtSt 1;
BA_ "SignalLongName" SG_ 388 HndsOffStrWhlDtMd "Hands Off Steering Wheel Detection Mode";
BA_ "SignalType" SG_ 388 HndsOffStrWhlDtMd "ENM";
BA_ "VNSigAllNodes" SG_ 388 HndsOffStrWhlDtMd 1;
BA_ "SignalLongName" SG_ 388 LKATrqOvrlStatChksm "Lane Keeping Assist Torque Overlay Status Checksum";
BA_ "SignalType" SG_ 388 LKATrqOvrlStatChksm "UNM";
BA_ "VNSigAllNodes" SG_ 388 LKATrqOvrlStatChksm 1;
BA_ "SignalLongName" SG_ 388 LKATrqOvrlDltTrqDlvd "Lane Keeping Assist Torque Overlay Delta Torque Delivered";
BA_ "SignalType" SG_ 388 LKATrqOvrlDltTrqDlvd "SNM";
BA_ "VNSigAllNodes" SG_ 388 LKATrqOvrlDltTrqDlvd 1;
BA_ "SignalLongName" SG_ 388 LKATrqOvrlDlvdRC "Lane Keeping Assist Torque Overlay Delivered Rolling Count";
BA_ "SignalType" SG_ 388 LKATrqOvrlDlvdRC "UNM";
BA_ "VNSigAllNodes" SG_ 388 LKATrqOvrlDlvdRC 1;
BA_ "SignalLongName" SG_ 388 LKAElPwrStTtlTqDlvd "Lane Keeping Assist Electrical Power Steering Total Torque Delivered";
BA_ "SignalType" SG_ 388 LKAElPwrStTtlTqDlvd "SNM";
BA_ "VNSigAllNodes" SG_ 388 LKAElPwrStTtlTqDlvd 1;
BA_ "SignalLongName" SG_ 388 LKATrqOvrlTrqDStat "Lane Keeping Assist Torque Overlay Torque Delivered Status";
BA_ "SignalType" SG_ 388 LKATrqOvrlTrqDStat "ENM";
BA_ "VNSigAllNodes" SG_ 388 LKATrqOvrlTrqDStat 1;
BA_ "SignalLongName" SG_ 388 LKADrvAppldTrqV "Lane Keeping Assist Driver Applied Torque Validity";
BA_ "SignalType" SG_ 388 LKADrvAppldTrqV "ENM";
BA_ "VNSigAllNodes" SG_ 388 LKADrvAppldTrqV 1;
BA_ "SignalLongName" SG_ 1611 DgnInf "Diagnostic Information";
BA_ "SignalType" SG_ 1611 DgnInf "UNM";
BA_ "VNSigSLHSSharedDiagnostic" SG_ 1611 DgnInf 1;
BA_ "VNSigAllNodes" SG_ 1611 DgnInf 1;
BA_ "GenSigDeltaValue" SG_ 1611 DgnInf 1;
BA_ "GenSigSendType" SG_ 1611 DgnInf 12;
BA_ "SignalLongName" SG_ 546 ThrmlRefCmpIGBTTmp "Thermal Refrigerant Compressor Insulated Gate Bipolar Transistor Temperature";
BA_ "SignalType" SG_ 546 ThrmlRefCmpIGBTTmp "UNM";
BA_ "VNSigAllNodes" SG_ 546 ThrmlRefCmpIGBTTmp 1;
BA_ "SignalLongName" SG_ 546 CmpSnsrDataARC "Compressor Sensor Data Alive Rolling Count";
BA_ "SignalType" SG_ 546 CmpSnsrDataARC "UNM";
BA_ "VNSigAllNodes" SG_ 546 CmpSnsrDataARC 1;
BA_ "SignalLongName" SG_ 546 ThrmlRefCmpCPUHtSkTmp "Thermal Refrigerant Compressor Central Processing Unit Heat Sink Temperature";
BA_ "SignalType" SG_ 546 ThrmlRefCmpCPUHtSkTmp "UNM";
BA_ "VNSigAllNodes" SG_ 546 ThrmlRefCmpCPUHtSkTmp 1;
BA_ "SignalLongName" SG_ 546 ThrmlRefCmpHVInHRsln "Thermal Refrigerant Compressor High Voltage Input High Resolution";
BA_ "SignalType" SG_ 546 ThrmlRefCmpHVInHRsln "UNM";
BA_ "VNSigAllNodes" SG_ 546 ThrmlRefCmpHVInHRsln 1;
BA_ "SignalLongName" SG_ 546 ThrmlRfCmprElctrCrnt "Thermal Refrigerant Compressor Electrical Current";
BA_ "SignalType" SG_ 546 ThrmlRfCmprElctrCrnt "UNM";
BA_ "VNSigAllNodes" SG_ 546 ThrmlRfCmprElctrCrnt 1;
BA_ "SignalLongName" SG_ 546 ThrmlRefCompSpdFdbck "Thermal Refrigerant Compressor Speed Feedback";
BA_ "SignalType" SG_ 546 ThrmlRefCompSpdFdbck "UNM";
BA_ "VNSigAllNodes" SG_ 546 ThrmlRefCompSpdFdbck 1;
BA_ "SignalLongName" SG_ 546 ThrmlRefCompStatFdbck "Thermal Refrigerant Compressor Status Feedback";
BA_ "SignalType" SG_ 546 ThrmlRefCompStatFdbck "ENM";
BA_ "VNSigAllNodes" SG_ 546 ThrmlRefCompStatFdbck 1;
BA_ "SignalLongName" SG_ 390 HybCrpCstCrvRq "Hybrid Creep Coast Curve Request";
BA_ "SignalType" SG_ 390 HybCrpCstCrvRq "ENM";
BA_ "VNSigAllNodes" SG_ 390 HybCrpCstCrvRq 1;
BA_ "SignalLongName" SG_ 390 TransFldPmpMtrDrtd "Transmission Fluid Pump Motor Derated";
BA_ "SignalType" SG_ 390 TransFldPmpMtrDrtd "BLN";
BA_ "VNSigAllNodes" SG_ 390 TransFldPmpMtrDrtd 1;
BA_ "SignalLongName" SG_ 390 RdHVInvRatVltV "Redundant High Voltage Inverter Rationalized Voltage Validity";
BA_ "SignalType" SG_ 390 RdHVInvRatVltV "ENM";
BA_ "VNSigAllNodes" SG_ 390 RdHVInvRatVltV 1;
BA_ "SignalLongName" SG_ 390 RdHVInvRatVlt "Redundant High Voltage Inverter Rationalized Voltage";
BA_ "SignalType" SG_ 390 RdHVInvRatVlt "UNM";
BA_ "VNSigAllNodes" SG_ 390 RdHVInvRatVlt 1;
BA_ "SignalLongName" SG_ 390 EngActDmpgDsblReq "Engine Active Damping Disable Requested";
BA_ "SignalType" SG_ 390 EngActDmpgDsblReq "BLN";
BA_ "VNSigAllNodes" SG_ 390 EngActDmpgDsblReq 1;
BA_ "SignalLongName" SG_ 390 HybRdcdTrqCapMd1Cmnd "Hybrid Reduced Torque Capacity Mode 1 Commanded";
BA_ "SignalType" SG_ 390 HybRdcdTrqCapMd1Cmnd "BLN";
BA_ "VNSigAllNodes" SG_ 390 HybRdcdTrqCapMd1Cmnd 1;
BA_ "SignalLongName" SG_ 390 HybExtndDcFuelCORq "Hybrid Extended Deceleration Fuel Cut Off Requested";
BA_ "SignalType" SG_ 390 HybExtndDcFuelCORq "BLN";
BA_ "VNSigAllNodes" SG_ 390 HybExtndDcFuelCORq 1;
BA_ "SignalLongName" SG_ 390 EstMtrPwrLossV "Estimated Motor Power Loss Validity";
BA_ "SignalType" SG_ 390 EstMtrPwrLossV "ENM";
BA_ "VNSigAllNodes" SG_ 390 EstMtrPwrLossV 1;
BA_ "SignalLongName" SG_ 390 EstMtrPwrLoss "Estimated Motor Power Loss";
BA_ "SignalType" SG_ 390 EstMtrPwrLoss "UNM";
BA_ "VNSigAllNodes" SG_ 390 EstMtrPwrLoss 1;
BA_ "SignalLongName" SG_ 390 HybCmmFailRdPwrCmd "Hybrid Communication Failure Reduced Power Commanded";
BA_ "SignalType" SG_ 390 HybCmmFailRdPwrCmd "BLN";
BA_ "VNSigAllNodes" SG_ 390 HybCmmFailRdPwrCmd 1;
BA_ "SignalLongName" SG_ 390 HybCmmdEngTrqLmtd "Hybrid Commanded Engine Torque Limited";
BA_ "SignalType" SG_ 390 HybCmmdEngTrqLmtd "UNM";
BA_ "VNSigAllNodes" SG_ 390 HybCmmdEngTrqLmtd 1;
BA_ "SignalLongName" SG_ 390 HybACCompRq "Hybrid Air Conditioning Compressor Request";
BA_ "SignalType" SG_ 390 HybACCompRq "ENM";
BA_ "VNSigAllNodes" SG_ 390 HybACCompRq 1;
BA_ "SignalLongName" SG_ 390 HybGrdBrkgAct "Hybrid Grade Braking Active";
BA_ "SignalType" SG_ 390 HybGrdBrkgAct "BLN";
BA_ "VNSigAllNodes" SG_ 390 HybGrdBrkgAct 1;
BA_ "SignalLongName" SG_ 390 HESSI_EngStrtTyp "Hybrid Engine Start Stop Information : Engine Start Type";
BA_ "PacketOrder" SG_ 390 HESSI_EngStrtTyp 2;
BA_ "SignalType" SG_ 390 HESSI_EngStrtTyp "ENM";
BA_ "VNSigAllNodes" SG_ 390 HESSI_EngStrtTyp 1;
BA_ "SignalLongName" SG_ 390 HESSI_EngStrtStpMd "Hybrid Engine Start Stop Information : Engine Start Stop Mode";
BA_ "PacketOrder" SG_ 390 HESSI_EngStrtStpMd 1;
BA_ "SignalType" SG_ 390 HESSI_EngStrtStpMd "ENM";
BA_ "VNSigAllNodes" SG_ 390 HESSI_EngStrtStpMd 1;
BA_ "SignalLongName" SG_ 390 HybCrnkAbrtd "Hybrid Crank Aborted";
BA_ "SignalType" SG_ 390 HybCrnkAbrtd "BLN";
BA_ "VNSigAllNodes" SG_ 390 HybCrnkAbrtd 1;
BA_ "SignalLongName" SG_ 390 CnvntlEngStrtEnbld "Conventional Engine Start Enabled";
BA_ "SignalType" SG_ 390 CnvntlEngStrtEnbld "BLN";
BA_ "VNSigAllNodes" SG_ 390 CnvntlEngStrtEnbld 1;
BA_ "SignalLongName" SG_ 390 HybDFCOReq "Hybrid Deceleration Fuel Cut Off Request";
BA_ "SignalType" SG_ 390 HybDFCOReq "ENM";
BA_ "VNSigAllNodes" SG_ 390 HybDFCOReq 1;
BA_ "SignalLongName" SG_ 390 RdPTHVCntrReq "Redundant Powertrain High Voltage Contactor Request";
BA_ "SignalType" SG_ 390 RdPTHVCntrReq "ENM";
BA_ "VNSigAllNodes" SG_ 390 RdPTHVCntrReq 1;
BA_ "SignalLongName" SG_ 1355 DgnInf_HS54B "Diagnostic Information HS54B";
BA_ "SignalType" SG_ 1355 DgnInf_HS54B "UNM";
BA_ "VNSigSLHSSharedDiagnostic" SG_ 1355 DgnInf_HS54B 1;
BA_ "VNSigAllNodes" SG_ 1355 DgnInf_HS54B 1;
BA_ "SignalLongName" SG_ 418 SecTrnGrRatInfoARC "Secure Transmission Gear Ratio Info Alive Rolling Count";
BA_ "SignalType" SG_ 418 SecTrnGrRatInfoARC "UNM";
BA_ "VNSigAllNodes" SG_ 418 SecTrnGrRatInfoARC 1;
BA_ "SignalLongName" SG_ 418 SecTrnGrRatInfoPVal "Secure Transmission Gear Ratio Info Protection Value";
BA_ "SignalType" SG_ 418 SecTrnGrRatInfoPVal "UNM";
BA_ "VNSigAllNodes" SG_ 418 SecTrnGrRatInfoPVal 1;
BA_ "SignalLongName" SG_ 418 STGRI_SecTrnGrRatV "Secure Transmission Gear Ratio Info : Secure Transmission Gear Ratio Validity";
BA_ "PacketOrder" SG_ 418 STGRI_SecTrnGrRatV 3;
BA_ "SignalType" SG_ 418 STGRI_SecTrnGrRatV "ENM";
BA_ "VNSigAllNodes" SG_ 418 STGRI_SecTrnGrRatV 1;
BA_ "SignalLongName" SG_ 418 STGRI_SecTrnGrRat "Secure Transmission Gear Ratio Info : Secure Transmission Gear Ratio";
BA_ "PacketOrder" SG_ 418 STGRI_SecTrnGrRat 2;
BA_ "SignalType" SG_ 418 STGRI_SecTrnGrRat "UNM";
BA_ "VNSigAllNodes" SG_ 418 STGRI_SecTrnGrRat 1;
BA_ "SignalLongName" SG_ 418 STGRI_TransGrRatSt "Secure Transmission Gear Ratio Info : Transmission Gear Ratio State";
BA_ "PacketOrder" SG_ 418 STGRI_TransGrRatSt 1;
BA_ "SignalType" SG_ 418 STGRI_TransGrRatSt "ENM";
BA_ "VNSigAllNodes" SG_ 418 STGRI_TransGrRatSt 1;
BA_ "SignalLongName" SG_ 418 SecTransEstGearInfoARC "Secure Transmission Estimated Gear Info Alive Rolling Count";
BA_ "SignalType" SG_ 418 SecTransEstGearInfoARC "UNM";
BA_ "VNSigAllNodes" SG_ 418 SecTransEstGearInfoARC 1;
BA_ "SignalLongName" SG_ 418 SecTransEstGearInfoPVal "Secure Transmission Estimated Gear Info Protection Value";
BA_ "SignalType" SG_ 418 SecTransEstGearInfoPVal "UNM";
BA_ "VNSigAllNodes" SG_ 418 SecTransEstGearInfoPVal 1;
BA_ "SignalLongName" SG_ 418 STEGI_SecTransEstGearV "Secure Transmission Estimated Gear Info : Secure Transmission Estimated Gear Validity";
BA_ "PacketOrder" SG_ 418 STEGI_SecTransEstGearV 2;
BA_ "SignalType" SG_ 418 STEGI_SecTransEstGearV "ENM";
BA_ "VNSigAllNodes" SG_ 418 STEGI_SecTransEstGearV 1;
BA_ "SignalLongName" SG_ 418 STEGI_SecTransEstGear "Secure Transmission Estimated Gear Info : Secure Transmission Estimated Gear";
BA_ "PacketOrder" SG_ 418 STEGI_SecTransEstGear 1;
BA_ "SignalType" SG_ 418 STEGI_SecTransEstGear "ENM";
BA_ "VNSigAllNodes" SG_ 418 STEGI_SecTransEstGear 1;
BA_ "SignalLongName" SG_ 1236 CGMSDCII_DataVal "Central Gateway Module Serial Data Calibration Identification Information : Data Value";
BA_ "PacketOrder" SG_ 1236 CGMSDCII_DataVal 3;
BA_ "SignalType" SG_ 1236 CGMSDCII_DataVal "UNM";
BA_ "VNSigAllNodes" SG_ 1236 CGMSDCII_DataVal 1;
BA_ "SignalLongName" SG_ 1236 CGMSDCII_DataIndx "Central Gateway Module Serial Data Calibration Identification Information : Data Index";
BA_ "PacketOrder" SG_ 1236 CGMSDCII_DataIndx 2;
BA_ "SignalType" SG_ 1236 CGMSDCII_DataIndx "ENM";
BA_ "VNSigAllNodes" SG_ 1236 CGMSDCII_DataIndx 1;
BA_ "SignalLongName" SG_ 1236 CGMSDCII_DataStat "Central Gateway Module Serial Data Calibration Identification Information : Data Status";
BA_ "PacketOrder" SG_ 1236 CGMSDCII_DataStat 1;
BA_ "SignalType" SG_ 1236 CGMSDCII_DataStat "ENM";
BA_ "VNSigAllNodes" SG_ 1236 CGMSDCII_DataStat 1;
BA_ "SignalLongName" SG_ 1236 CGMRCII_DataVal "Central Gateway Module Routing Calibration Identification Information : Data Value";
BA_ "PacketOrder" SG_ 1236 CGMRCII_DataVal 3;
BA_ "SignalType" SG_ 1236 CGMRCII_DataVal "UNM";
BA_ "VNSigAllNodes" SG_ 1236 CGMRCII_DataVal 1;
BA_ "SignalLongName" SG_ 1236 CGMRCII_DataIndx "Central Gateway Module Routing Calibration Identification Information : Data Index";
BA_ "PacketOrder" SG_ 1236 CGMRCII_DataIndx 2;
BA_ "SignalType" SG_ 1236 CGMRCII_DataIndx "ENM";
BA_ "VNSigAllNodes" SG_ 1236 CGMRCII_DataIndx 1;
BA_ "SignalLongName" SG_ 1236 CGMRCII_DataStat "Central Gateway Module Routing Calibration Identification Information : Data Status";
BA_ "PacketOrder" SG_ 1236 CGMRCII_DataStat 1;
BA_ "SignalType" SG_ 1236 CGMRCII_DataStat "ENM";
BA_ "VNSigAllNodes" SG_ 1236 CGMRCII_DataStat 1;
BA_ "SignalLongName" SG_ 1236 CGMOCII_DataVal "Central Gateway Module OBD Calibration Identification Information : Data Value";
BA_ "PacketOrder" SG_ 1236 CGMOCII_DataVal 3;
BA_ "SignalType" SG_ 1236 CGMOCII_DataVal "UNM";
BA_ "VNSigAllNodes" SG_ 1236 CGMOCII_DataVal 1;
BA_ "SignalLongName" SG_ 1236 CGMOCII_DataIndx "Central Gateway Module OBD Calibration Identification Information : Data Index";
BA_ "PacketOrder" SG_ 1236 CGMOCII_DataIndx 2;
BA_ "SignalType" SG_ 1236 CGMOCII_DataIndx "ENM";
BA_ "VNSigAllNodes" SG_ 1236 CGMOCII_DataIndx 1;
BA_ "SignalLongName" SG_ 1236 CGMOCII_DataStat "Central Gateway Module OBD Calibration Identification Information : Data Status";
BA_ "PacketOrder" SG_ 1236 CGMOCII_DataStat 1;
BA_ "SignalType" SG_ 1236 CGMOCII_DataStat "ENM";
BA_ "VNSigAllNodes" SG_ 1236 CGMOCII_DataStat 1;
BA_ "SignalLongName" SG_ 1236 CGMSII_DataVal "Central Gateway Module Software Identification Information : Data Value";
BA_ "PacketOrder" SG_ 1236 CGMSII_DataVal 3;
BA_ "SignalType" SG_ 1236 CGMSII_DataVal "UNM";
BA_ "VNSigAllNodes" SG_ 1236 CGMSII_DataVal 1;
BA_ "SignalLongName" SG_ 1236 CGMSII_DataIndx "Central Gateway Module Software Identification Information : Data Index";
BA_ "PacketOrder" SG_ 1236 CGMSII_DataIndx 2;
BA_ "SignalType" SG_ 1236 CGMSII_DataIndx "ENM";
BA_ "VNSigAllNodes" SG_ 1236 CGMSII_DataIndx 1;
BA_ "SignalLongName" SG_ 1236 CGMSII_DataStat "Central Gateway Module Software Identification Information : Data Status";
BA_ "PacketOrder" SG_ 1236 CGMSII_DataStat 1;
BA_ "SignalType" SG_ 1236 CGMSII_DataStat "ENM";
BA_ "VNSigAllNodes" SG_ 1236 CGMSII_DataStat 1;
BA_ "SignalLongName" SG_ 1195 TransTempOpRgn "Transmission Temperature Operating Region";
BA_ "SignalType" SG_ 1195 TransTempOpRgn "ENM";
BA_ "VNSigAllNodes" SG_ 1195 TransTempOpRgn 1;
BA_ "SignalLongName" SG_ 1195 TransOilTempAltValV "Transmission Oil Temperature Alternate Value Validity";
BA_ "SignalType" SG_ 1195 TransOilTempAltValV "ENM";
BA_ "VNSigAllNodes" SG_ 1195 TransOilTempAltValV 1;
BA_ "SignalLongName" SG_ 1195 TransOilTempAltValM "Transmission Oil Temperature Alternate Value Mask";
BA_ "SignalType" SG_ 1195 TransOilTempAltValM "ENM";
BA_ "VNSigAllNodes" SG_ 1195 TransOilTempAltValM 1;
BA_ "SignalLongName" SG_ 1195 TransOilTempAltVal "Transmission Oil Temperature Alternate Value";
BA_ "SignalType" SG_ 1195 TransOilTempAltVal "UNM";
BA_ "VNSigAllNodes" SG_ 1195 TransOilTempAltVal 1;
BA_ "SignalLongName" SG_ 1195 TransOilTgtTemp "Transmission Oil Target Temperature";
BA_ "SignalType" SG_ 1195 TransOilTgtTemp "UNM";
BA_ "VNSigAllNodes" SG_ 1195 TransOilTgtTemp 1;
BA_ "SignalLongName" SG_ 612 PPSTmBrstID "Precise Position Time Burst ID";
BA_ "SignalType" SG_ 612 PPSTmBrstID "UNM";
BA_ "VNSigAllNodes" SG_ 612 PPSTmBrstID 1;
BA_ "SignalLongName" SG_ 612 PPSTmChksm "Precise Position Time Checksum";
BA_ "SignalType" SG_ 612 PPSTmChksm "UNM";
BA_ "VNSigAllNodes" SG_ 612 PPSTmChksm 1;
BA_ "SignalLongName" SG_ 612 PPSTmdayV "Precise Position Time of Day Validity";
BA_ "SignalType" SG_ 612 PPSTmdayV "ENM";
BA_ "VNSigAllNodes" SG_ 612 PPSTmdayV 1;
BA_ "SignalLongName" SG_ 612 PPSCldrYrV "Precise Position Calendar Year Validity";
BA_ "SignalType" SG_ 612 PPSCldrYrV "ENM";
BA_ "VNSigAllNodes" SG_ 612 PPSCldrYrV 1;
BA_ "SignalLongName" SG_ 612 PPSCldrDayV "Precise Position Calendar Day Validity";
BA_ "SignalType" SG_ 612 PPSCldrDayV "ENM";
BA_ "VNSigAllNodes" SG_ 612 PPSCldrDayV 1;
BA_ "SignalLongName" SG_ 612 PPSCldrDay "Precise Position Calendar Day";
BA_ "SignalType" SG_ 612 PPSCldrDay "UNM";
BA_ "VNSigAllNodes" SG_ 612 PPSCldrDay 1;
BA_ "SignalLongName" SG_ 612 PPSCldrYr "Precise Position Calendar Year";
BA_ "SignalType" SG_ 612 PPSCldrYr "UNM";
BA_ "VNSigAllNodes" SG_ 612 PPSCldrYr 1;
BA_ "SignalLongName" SG_ 612 PPSTmday "Precise Position Time of Day";
BA_ "SignalType" SG_ 612 PPSTmday "UNM";
BA_ "VNSigAllNodes" SG_ 612 PPSTmday 1;
BA_ "SignalLongName" SG_ 189 TransOilPmpOfRqd "Transmission Oil Pump Off Requested";
BA_ "SignalType" SG_ 189 TransOilPmpOfRqd "BLN";
BA_ "VNSigAllNodes" SG_ 189 TransOilPmpOfRqd 1;
BA_ "SignalLongName" SG_ 189 TransMnPressEstmd "Transmission Main Pressure Estimated";
BA_ "SignalType" SG_ 189 TransMnPressEstmd "UNM";
BA_ "VNSigAllNodes" SG_ 189 TransMnPressEstmd 1;
BA_ "SignalLongName" SG_ 189 TrnsInpMinSpdRq "Transmission Input Minimum Speed Request";
BA_ "SignalType" SG_ 189 TrnsInpMinSpdRq "ENM";
BA_ "VNSigAllNodes" SG_ 189 TrnsInpMinSpdRq 1;
BA_ "SignalLongName" SG_ 189 TrnsHydPrsDsrd "Transmission Hydraulic Pressure Desired";
BA_ "SignalType" SG_ 189 TrnsHydPrsDsrd "UNM";
BA_ "VNSigAllNodes" SG_ 189 TrnsHydPrsDsrd 1;
BA_ "SignalLongName" SG_ 189 TransAuxPumpSpdDsrd "Transmission Auxiliary Pump Speed Desired";
BA_ "SignalType" SG_ 189 TransAuxPumpSpdDsrd "UNM";
BA_ "VNSigAllNodes" SG_ 189 TransAuxPumpSpdDsrd 1;
BA_ "SignalLongName" SG_ 189 HybDisengCruzCmnd "Hybrid Disengage Cruise Commanded";
BA_ "SignalType" SG_ 189 HybDisengCruzCmnd "BLN";
BA_ "VNSigAllNodes" SG_ 189 HybDisengCruzCmnd 1;
BA_ "GenSigStartValue" SG_ 189 TransVehTopSpdLim 255;
BA_ "SignalLongName" SG_ 189 TransVehTopSpdLim "Transmission Vehicle Top Speed Limit Value";
BA_ "SignalType" SG_ 189 TransVehTopSpdLim "UNM";
BA_ "VNSigAllNodes" SG_ 189 TransVehTopSpdLim 1;
BA_ "SignalLongName" SG_ 189 TransMinVoltReq "Transmission Minimum Voltage Request";
BA_ "SignalType" SG_ 189 TransMinVoltReq "UNM";
BA_ "VNSigAllNodes" SG_ 189 TransMinVoltReq 1;
BA_ "SignalLongName" SG_ 189 TrnsRtoCntlSysFlt "Transmission Ratio Control System Fault";
BA_ "SignalType" SG_ 189 TrnsRtoCntlSysFlt "BLN";
BA_ "VNSigAllNodes" SG_ 189 TrnsRtoCntlSysFlt 1;
BA_ "SignalLongName" SG_ 422 TrnsStatTrkMdOvrd "Transmission State Track Mode Override";
BA_ "SignalType" SG_ 422 TrnsStatTrkMdOvrd "ENM";
BA_ "VNSigAllNodes" SG_ 422 TrnsStatTrkMdOvrd 1;
BA_ "SignalLongName" SG_ 422 DuTrkPlsWdCrkPrmStARC "Dual Track Pulse Width Crank Permission Status Alive Rolling Count";
BA_ "SignalType" SG_ 422 DuTrkPlsWdCrkPrmStARC "UNM";
BA_ "VNSigAllNodes" SG_ 422 DuTrkPlsWdCrkPrmStARC 1;
BA_ "SignalLongName" SG_ 422 DTPWCPS_CrnkPrmV "Dual Track Pulse Width Crank Permission Status : Crank Permission Validity";
BA_ "PacketOrder" SG_ 422 DTPWCPS_CrnkPrmV 2;
BA_ "SignalType" SG_ 422 DTPWCPS_CrnkPrmV "ENM";
BA_ "VNSigAllNodes" SG_ 422 DTPWCPS_CrnkPrmV 1;
BA_ "SignalLongName" SG_ 422 DTPWCPS_CrnkPrm "Dual Track Pulse Width Crank Permission Status : Crank Permission";
BA_ "PacketOrder" SG_ 422 DTPWCPS_CrnkPrm 1;
BA_ "SignalType" SG_ 422 DTPWCPS_CrnkPrm "ENM";
BA_ "VNSigAllNodes" SG_ 422 DTPWCPS_CrnkPrm 1;
BA_ "SignalLongName" SG_ 422 DuTrkPlsWdCrkPrmStPVal "Dual Track Pulse Width Crank Permission Status Protection Value";
BA_ "SignalType" SG_ 422 DuTrkPlsWdCrkPrmStPVal "UNM";
BA_ "VNSigAllNodes" SG_ 422 DuTrkPlsWdCrkPrmStPVal 1;
BA_ "SignalLongName" SG_ 422 TrnsAuxPrsDisOvrrdOn "Transmission Auxiliary Pressure Discharge Override On";
BA_ "SignalType" SG_ 422 TrnsAuxPrsDisOvrrdOn "BLN";
BA_ "VNSigAllNodes" SG_ 422 TrnsAuxPrsDisOvrrdOn 1;
BA_ "SignalLongName" SG_ 422 TransEngShtdwnReqdPVa "Transmission Engine Shutdown Requested Protection Value";
BA_ "SignalType" SG_ 422 TransEngShtdwnReqdPVa "UNM";
BA_ "VNSigAllNodes" SG_ 422 TransEngShtdwnReqdPVa 1;
BA_ "SignalLongName" SG_ 422 TrnsEngShtdwnRqARC "Transmission Engine Shutdown Requested Alive Rolling Count";
BA_ "SignalType" SG_ 422 TrnsEngShtdwnRqARC "UNM";
BA_ "VNSigAllNodes" SG_ 422 TrnsEngShtdwnRqARC 1;
BA_ "SignalLongName" SG_ 422 TransEngShtdwnRqd "Transmission Engine Shutdown Requested";
BA_ "SignalType" SG_ 422 TransEngShtdwnRqd "BLN";
BA_ "VNSigAllNodes" SG_ 422 TransEngShtdwnRqd 1;
BA_ "SignalLongName" SG_ 422 TransCrksftTqLoadV "Transmission Crankshaft Torque Load Validity";
BA_ "SignalType" SG_ 422 TransCrksftTqLoadV "ENM";
BA_ "VNSigAllNodes" SG_ 422 TransCrksftTqLoadV 1;
BA_ "SignalLongName" SG_ 422 TransCrksftTqLoad "Transmission Crankshaft Torque Load";
BA_ "SignalType" SG_ 422 TransCrksftTqLoad "UNM";
BA_ "VNSigAllNodes" SG_ 422 TransCrksftTqLoad 1;
BA_ "SignalLongName" SG_ 422 TrStPTGrdBrkDsMdOvr "Transmission State Powertrain Grade Braking  Disable Mode Override";
BA_ "SignalType" SG_ 422 TrStPTGrdBrkDsMdOvr "ENM";
BA_ "VNSigAllNodes" SG_ 422 TrStPTGrdBrkDsMdOvr 1;
BA_ "SignalLongName" SG_ 422 TrnsHybEngSrtStpOvrd "Transmission Hybrid Engine Start Stop Override";
BA_ "SignalType" SG_ 422 TrnsHybEngSrtStpOvrd "ENM";
BA_ "VNSigAllNodes" SG_ 422 TrnsHybEngSrtStpOvrd 1;
BA_ "SignalLongName" SG_ 1189 TransAirFlwPrcntRq "Transmission Air Flow Percent Request";
BA_ "SignalType" SG_ 1189 TransAirFlwPrcntRq "UNM";
BA_ "VNSigAllNodes" SG_ 1189 TransAirFlwPrcntRq 1;
BA_ "SignalLongName" SG_ 393 TrnsTrqCap "Transmission Torque Capacity";
BA_ "SignalType" SG_ 393 TrnsTrqCap "UNM";
BA_ "VNSigAllNodes" SG_ 393 TrnsTrqCap 1;
BA_ "SignalLongName" SG_ 393 TIDCTR_TrqIntvTyp "Transmission Immediate Directional Crankshaft Torque Request : Torque Intervention Type";
BA_ "PacketOrder" SG_ 393 TIDCTR_TrqIntvTyp 3;
BA_ "SignalType" SG_ 393 TIDCTR_TrqIntvTyp "ENM";
BA_ "VNSigAllNodes" SG_ 393 TIDCTR_TrqIntvTyp 1;
BA_ "SignalLongName" SG_ 393 TIDCTR_TrqReqVal "Transmission Immediate Directional Crankshaft Torque Request : Torque Request Value";
BA_ "PacketOrder" SG_ 393 TIDCTR_TrqReqVal 2;
BA_ "SignalType" SG_ 393 TIDCTR_TrqReqVal "UNM";
BA_ "VNSigAllNodes" SG_ 393 TIDCTR_TrqReqVal 1;
BA_ "SignalLongName" SG_ 393 TIDCTR_TrqRespTyp "Transmission Immediate Directional Crankshaft Torque Request : Torque Response Type";
BA_ "PacketOrder" SG_ 393 TIDCTR_TrqRespTyp 1;
BA_ "SignalType" SG_ 393 TIDCTR_TrqRespTyp "ENM";
BA_ "VNSigAllNodes" SG_ 393 TIDCTR_TrqRespTyp 1;
BA_ "SignalLongName" SG_ 393 TrnsPdCrkshftTqRqPVa "Transmission Predicted Crankshaft Torque Request Protection Value";
BA_ "SignalType" SG_ 393 TrnsPdCrkshftTqRqPVa "UNM";
BA_ "VNSigAllNodes" SG_ 393 TrnsPdCrkshftTqRqPVa 1;
BA_ "SignalLongName" SG_ 393 TPCTR_TorqReqVal "Transmission Predicted Crankshaft Torque Request : Torque Request Value";
BA_ "PacketOrder" SG_ 393 TPCTR_TorqReqVal 2;
BA_ "SignalType" SG_ 393 TPCTR_TorqReqVal "UNM";
BA_ "VNSigAllNodes" SG_ 393 TPCTR_TorqReqVal 1;
BA_ "SignalLongName" SG_ 393 TPCTR_TrqIntrvnTyp "Transmission Predicted Crankshaft Torque Request : Torque Intervention Type";
BA_ "PacketOrder" SG_ 393 TPCTR_TrqIntrvnTyp 1;
BA_ "SignalType" SG_ 393 TPCTR_TrqIntrvnTyp "ENM";
BA_ "VNSigAllNodes" SG_ 393 TPCTR_TrqIntrvnTyp 1;
BA_ "SignalLongName" SG_ 393 TrnsTrqRqALC "Transmission Torque Request Alive Rolling Count";
BA_ "SignalType" SG_ 393 TrnsTrqRqALC "UNM";
BA_ "VNSigAllNodes" SG_ 393 TrnsTrqRqALC 1;
BA_ "SignalLongName" SG_ 719 RrVrtlBmpAxlTrqCmdRC "Rear Virtual Bumper Axle Torque Command Rolling Count";
BA_ "SignalType" SG_ 719 RrVrtlBmpAxlTrqCmdRC "UNM";
BA_ "VNSigAllNodes" SG_ 719 RrVrtlBmpAxlTrqCmdRC 1;
BA_ "SignalLongName" SG_ 719 RrVrtlBmpAxlTrqCmdProtVal "Rear Virtual Bumper Axle Torque Command Protection Value";
BA_ "SignalType" SG_ 719 RrVrtlBmpAxlTrqCmdProtVal "UNM";
BA_ "VNSigAllNodes" SG_ 719 RrVrtlBmpAxlTrqCmdProtVal 1;
BA_ "SignalLongName" SG_ 719 RVBATC_AxlTrqRqstAct "Rear Virtual Bumper Axle Torque Command : Axle Torque Request Active";
BA_ "PacketOrder" SG_ 719 RVBATC_AxlTrqRqstAct 1;
BA_ "SignalType" SG_ 719 RVBATC_AxlTrqRqstAct "BLN";
BA_ "VNSigAllNodes" SG_ 719 RVBATC_AxlTrqRqstAct 1;
BA_ "GenSigStartValue" SG_ 719 RVBATC_AxlTrqRqst 32767;
BA_ "SignalLongName" SG_ 719 RVBATC_AxlTrqRqst "Rear Virtual Bumper Axle Torque Command : Axle Torque Request";
BA_ "PacketOrder" SG_ 719 RVBATC_AxlTrqRqst 2;
BA_ "SignalType" SG_ 719 RVBATC_AxlTrqRqst "UNM";
BA_ "VNSigAllNodes" SG_ 719 RVBATC_AxlTrqRqst 1;
BA_ "SignalLongName" SG_ 717 ColPrSysAxlTrqCmdProtVal "Collision Preparation System Axle Torque Command Protection Value";
BA_ "SignalType" SG_ 717 ColPrSysAxlTrqCmdProtVal "UNM";
BA_ "VNSigAllNodes" SG_ 717 ColPrSysAxlTrqCmdProtVal 1;
BA_ "SignalLongName" SG_ 717 CPSATC_AxlTrqRqstAct "Collision Preparation System Axle Torque Command : Axle Torque Request Active";
BA_ "PacketOrder" SG_ 717 CPSATC_AxlTrqRqstAct 1;
BA_ "SignalType" SG_ 717 CPSATC_AxlTrqRqstAct "BLN";
BA_ "VNSigAllNodes" SG_ 717 CPSATC_AxlTrqRqstAct 1;
BA_ "GenSigStartValue" SG_ 717 CPSATC_AxlTrqRqst 32767;
BA_ "SignalLongName" SG_ 717 CPSATC_AxlTrqRqst "Collision Preparation System Axle Torque Command : Axle Torque Request";
BA_ "PacketOrder" SG_ 717 CPSATC_AxlTrqRqst 2;
BA_ "SignalType" SG_ 717 CPSATC_AxlTrqRqst "UNM";
BA_ "VNSigAllNodes" SG_ 717 CPSATC_AxlTrqRqst 1;
BA_ "SignalLongName" SG_ 717 ColPrSysAxlTrqCmdRC "Collision Preparation System Axle Torque Command Rolling Count";
BA_ "SignalType" SG_ 717 ColPrSysAxlTrqCmdRC "UNM";
BA_ "VNSigAllNodes" SG_ 717 ColPrSysAxlTrqCmdRC 1;
BA_ "SignalLongName" SG_ 1005 EnhSvVehTopSpdLmR "Enhanced Services Vehicle Top Speed Limit Request";
BA_ "SignalType" SG_ 1005 EnhSvVehTopSpdLmR "ENM";
BA_ "VNSigAllNodes" SG_ 1005 EnhSvVehTopSpdLmR 1;
BA_ "SignalLongName" SG_ 1005 EnhSvVTpSpdLVlARC "Enhanced Services Vehicle Top Speed Limit Value Alive Rolling Count";
BA_ "SignalType" SG_ 1005 EnhSvVTpSpdLVlARC "UNM";
BA_ "VNSigAllNodes" SG_ 1005 EnhSvVTpSpdLVlARC 1;
BA_ "SignalLongName" SG_ 1005 EnhSvVehTopSpdLimP "Enhanced Services Vehicle Top Speed Limit Password";
BA_ "SignalType" SG_ 1005 EnhSvVehTopSpdLimP "UNM";
BA_ "VNSigAllNodes" SG_ 1005 EnhSvVehTopSpdLimP 1;
BA_ "GenSigStartValue" SG_ 1005 EnhSvVehTopSpdLim 255;
BA_ "SignalLongName" SG_ 1005 EnhSvVehTopSpdLim "Enhanced Services Vehicle Top Speed Limit Value";
BA_ "SignalType" SG_ 1005 EnhSvVehTopSpdLim "UNM";
BA_ "VNSigAllNodes" SG_ 1005 EnhSvVehTopSpdLim 1;
BA_ "GenSigDeltaValue" SG_ 1005 EnhSvVehTopSpdLim 1;
BA_ "GenSigSendType" SG_ 1005 EnhSvVehTopSpdLim 12;
BA_ "SignalLongName" SG_ 431 TrnsInpCltchStatV "Transmission Input Clutch Status Validity";
BA_ "SignalType" SG_ 431 TrnsInpCltchStatV "ENM";
BA_ "VNSigAllNodes" SG_ 431 TrnsInpCltchStatV 1;
BA_ "SignalLongName" SG_ 431 TransCrnkPermsnStatV "Transmission Crank Permission Status Validity";
BA_ "SignalType" SG_ 431 TransCrnkPermsnStatV "ENM";
BA_ "VNSigAllNodes" SG_ 431 TransCrnkPermsnStatV 1;
BA_ "GenSigStartValue" SG_ 431 TransVehTopSpdLim 255;
BA_ "SignalLongName" SG_ 431 TransVehTopSpdLim "Transmission Vehicle Top Speed Limit Value";
BA_ "SignalType" SG_ 431 TransVehTopSpdLim "UNM";
BA_ "VNSigAllNodes" SG_ 431 TransVehTopSpdLim 1;
BA_ "SignalLongName" SG_ 431 TransMinVoltReq "Transmission Minimum Voltage Request";
BA_ "SignalType" SG_ 431 TransMinVoltReq "UNM";
BA_ "VNSigAllNodes" SG_ 431 TransMinVoltReq 1;
BA_ "SignalLongName" SG_ 431 TDslPrtFltrIdlRgtnMdAtv "Transmission Diesel Particulate Filter Idle Regeneration Mode Active";
BA_ "SignalType" SG_ 431 TDslPrtFltrIdlRgtnMdAtv "BLN";
BA_ "VNSigAllNodes" SG_ 431 TDslPrtFltrIdlRgtnMdAtv 1;
BA_ "SignalLongName" SG_ 431 DrvlneTrqStabStat "Driveline Torque Stability Status";
BA_ "SignalType" SG_ 431 DrvlneTrqStabStat "ENM";
BA_ "VNSigAllNodes" SG_ 431 DrvlneTrqStabStat 1;
BA_ "SignalLongName" SG_ 431 TrnsTrqCnvCltCmdMdF "Transmission Torque Converter Clutch Commanded Mode Failure";
BA_ "SignalType" SG_ 431 TrnsTrqCnvCltCmdMdF "BLN";
BA_ "VNSigAllNodes" SG_ 431 TrnsTrqCnvCltCmdMdF 1;
BA_ "SignalLongName" SG_ 431 AutoTransGrSftDirectFl "Automatic Transmission Gear Shift Direction Failure";
BA_ "SignalType" SG_ 431 AutoTransGrSftDirectFl "BLN";
BA_ "VNSigAllNodes" SG_ 431 AutoTransGrSftDirectFl 1;
BA_ "SignalLongName" SG_ 431 AutoTransGrSftDirect "Automatic Transmission Gear Shift Direction";
BA_ "SignalType" SG_ 431 AutoTransGrSftDirect "ENM";
BA_ "VNSigAllNodes" SG_ 431 AutoTransGrSftDirect 1;
BA_ "GenSigStartValue" SG_ 431 TrnsTrqCnvCltCmndMd 7;
BA_ "SignalLongName" SG_ 431 TrnsTrqCnvCltCmndMd "Transmission Torque Converter Clutch Commanded Mode";
BA_ "SignalType" SG_ 431 TrnsTrqCnvCltCmndMd "ENM";
BA_ "VNSigAllNodes" SG_ 431 TrnsTrqCnvCltCmndMd 1;
BA_ "SignalLongName" SG_ 431 TrnsTrqCnvCltDsrSlp "Transmission Torque Converter Clutch Desired Slip";
BA_ "SignalType" SG_ 431 TrnsTrqCnvCltDsrSlp "SNM";
BA_ "VNSigAllNodes" SG_ 431 TrnsTrqCnvCltDsrSlp 1;
BA_ "SignalLongName" SG_ 431 TrnsStWntrMdOvrd "Transmission State Winter Mode Override";
BA_ "SignalType" SG_ 431 TrnsStWntrMdOvrd "ENM";
BA_ "VNSigAllNodes" SG_ 431 TrnsStWntrMdOvrd 1;
BA_ "SignalLongName" SG_ 431 TrnsStTwHaulMdOvrd "Transmission State Tow Haul Mode Override";
BA_ "SignalType" SG_ 431 TrnsStTwHaulMdOvrd "ENM";
BA_ "VNSigAllNodes" SG_ 431 TrnsStTwHaulMdOvrd 1;
BA_ "SignalLongName" SG_ 431 TrnsStSprtMdOvrd "Transmission State Sport Mode Override";
BA_ "SignalType" SG_ 431 TrnsStSprtMdOvrd "ENM";
BA_ "VNSigAllNodes" SG_ 431 TrnsStSprtMdOvrd 1;
BA_ "SignalLongName" SG_ 431 TrnsStEconMdOvrd "Transmission State Economy Mode Override";
BA_ "SignalType" SG_ 431 TrnsStEconMdOvrd "ENM";
BA_ "VNSigAllNodes" SG_ 431 TrnsStEconMdOvrd 1;
BA_ "SignalLongName" SG_ 431 TrnsInpCltchStat "Transmission Input Clutch Status";
BA_ "SignalType" SG_ 431 TrnsInpCltchStat "ENM";
BA_ "VNSigAllNodes" SG_ 431 TrnsInpCltchStat 1;
BA_ "SignalLongName" SG_ 431 TrnsAntcptdCrpTrqRRnV "Transmission Anticipated Creep Torque Reduced Range Validity";
BA_ "SignalType" SG_ 431 TrnsAntcptdCrpTrqRRnV "ENM";
BA_ "VNSigAllNodes" SG_ 431 TrnsAntcptdCrpTrqRRnV 1;
BA_ "SignalLongName" SG_ 431 TrnsAntcptdCrpTrqRRn "Transmission Anticipated Creep Torque Reduced Range";
BA_ "SignalType" SG_ 431 TrnsAntcptdCrpTrqRRn "UNM";
BA_ "VNSigAllNodes" SG_ 431 TrnsAntcptdCrpTrqRRn 1;
BA_ "SignalLongName" SG_ 431 TrnCltAdpAtv "Transmission Clutch Adaptation Active";
BA_ "SignalType" SG_ 431 TrnCltAdpAtv "BLN";
BA_ "VNSigAllNodes" SG_ 431 TrnCltAdpAtv 1;
BA_ "SignalLongName" SG_ 431 TransCrnkPermsnStat "Transmission Crank Permission Status";
BA_ "SignalType" SG_ 431 TransCrnkPermsnStat "ENM";
BA_ "VNSigAllNodes" SG_ 431 TransCrnkPermsnStat 1;
BA_ "SignalLongName" SG_ 431 WrmUpShftPtrn "Warm Up Shift Pattern Status";
BA_ "SignalType" SG_ 431 WrmUpShftPtrn "ENM";
BA_ "VNSigAllNodes" SG_ 431 WrmUpShftPtrn 1;
BA_ "SignalLongName" SG_ 409 TrnsAliveRC_199 "Transmission Alive Rolling Count 199";
BA_ "SignalType" SG_ 409 TrnsAliveRC_199 "UNM";
BA_ "VNSigAllNodes" SG_ 409 TrnsAliveRC_199 1;
BA_ "SignalLongName" SG_ 409 TDslPrtFltrIdlRgtnMdAtv "Transmission Diesel Particulate Filter Idle Regeneration Mode Active";
BA_ "SignalType" SG_ 409 TDslPrtFltrIdlRgtnMdAtv "BLN";
BA_ "VNSigAllNodes" SG_ 409 TDslPrtFltrIdlRgtnMdAtv 1;
BA_ "SignalLongName" SG_ 409 TransMinVoltReq "Transmission Minimum Voltage Request";
BA_ "SignalType" SG_ 409 TransMinVoltReq "UNM";
BA_ "VNSigAllNodes" SG_ 409 TransMinVoltReq 1;
BA_ "GenSigStartValue" SG_ 409 TransVehTopSpdLim 255;
BA_ "SignalLongName" SG_ 409 TransVehTopSpdLim "Transmission Vehicle Top Speed Limit Value";
BA_ "SignalType" SG_ 409 TransVehTopSpdLim "UNM";
BA_ "VNSigAllNodes" SG_ 409 TransVehTopSpdLim 1;
BA_ "SignalLongName" SG_ 409 TrnsTrqRqProt "Transmission Torque Request Protection";
BA_ "SignalType" SG_ 409 TrnsTrqRqProt "UNM";
BA_ "VNSigAllNodes" SG_ 409 TrnsTrqRqProt 1;
BA_ "SignalLongName" SG_ 409 TTRLT_TorqReqVal "Transmission Torque Request Long-term : Torque Request Value";
BA_ "PacketOrder" SG_ 409 TTRLT_TorqReqVal 3;
BA_ "SignalType" SG_ 409 TTRLT_TorqReqVal "UNM";
BA_ "VNSigAllNodes" SG_ 409 TTRLT_TorqReqVal 1;
BA_ "SignalLongName" SG_ 409 TTRLT_TqRdnRlznSgg "Transmission Torque Request Long-term : Torque Reduction Realization Suggestion";
BA_ "PacketOrder" SG_ 409 TTRLT_TqRdnRlznSgg 2;
BA_ "SignalType" SG_ 409 TTRLT_TqRdnRlznSgg "ENM";
BA_ "VNSigAllNodes" SG_ 409 TTRLT_TqRdnRlznSgg 1;
BA_ "SignalLongName" SG_ 409 TTRLT_TorqInvntnTyp "Transmission Torque Request Long-term : Torque Intervention Type";
BA_ "PacketOrder" SG_ 409 TTRLT_TorqInvntnTyp 1;
BA_ "SignalType" SG_ 409 TTRLT_TorqInvntnTyp "ENM";
BA_ "VNSigAllNodes" SG_ 409 TTRLT_TorqInvntnTyp 1;
BA_ "SignalLongName" SG_ 409 TTRST_TorqReqVal "Transmission Torque Request Short-term : Torque Request Value";
BA_ "PacketOrder" SG_ 409 TTRST_TorqReqVal 2;
BA_ "SignalType" SG_ 409 TTRST_TorqReqVal "UNM";
BA_ "VNSigAllNodes" SG_ 409 TTRST_TorqReqVal 1;
BA_ "SignalLongName" SG_ 409 TTRST_TorqInvntnTyp "Transmission Torque Request Short-term : Torque Intervention Type";
BA_ "PacketOrder" SG_ 409 TTRST_TorqInvntnTyp 1;
BA_ "SignalType" SG_ 409 TTRST_TorqInvntnTyp "ENM";
BA_ "VNSigAllNodes" SG_ 409 TTRST_TorqInvntnTyp 1;
BA_ "SignalLongName" SG_ 2016 DgnInf "Diagnostic Information";
BA_ "SignalType" SG_ 2016 DgnInf "UNM";
BA_ "VNSigSLHSSharedDiagnostic" SG_ 2016 DgnInf 1;
BA_ "VNSigAllNodes" SG_ 2016 DgnInf 1;
BA_ "GenSigDeltaValue" SG_ 2016 DgnInf 1;
BA_ "GenSigSendType" SG_ 2016 DgnInf 12;
BA_ "SignalLongName" SG_ 420 SecDrvIntndCrksftTrqARC "Secure Driver Intended Crankshaft Torque Alive Rolling Count";
BA_ "SignalType" SG_ 420 SecDrvIntndCrksftTrqARC "UNM";
BA_ "VNSigAllNodes" SG_ 420 SecDrvIntndCrksftTrqARC 1;
BA_ "SignalLongName" SG_ 420 SecDrvIntndCrksftTrqPVal "Secure Driver Intended Crankshaft Torque Protection Value";
BA_ "SignalType" SG_ 420 SecDrvIntndCrksftTrqPVal "UNM";
BA_ "VNSigAllNodes" SG_ 420 SecDrvIntndCrksftTrqPVal 1;
BA_ "SignalLongName" SG_ 420 SecDrvIntndCrksftTrq "Secure Driver Intended Crankshaft Torque";
BA_ "SignalType" SG_ 420 SecDrvIntndCrksftTrq "UNM";
BA_ "VNSigAllNodes" SG_ 420 SecDrvIntndCrksftTrq 1;
BA_ "SignalLongName" SG_ 558 CmpDataPktARC "Compressor Data Packet Alive Rolling Count";
BA_ "SignalType" SG_ 558 CmpDataPktARC "UNM";
BA_ "VNSigAllNodes" SG_ 558 CmpDataPktARC 1;
BA_ "SignalLongName" SG_ 558 CDP_HVDevShtdnCdARCSt "Compressor Data Packet : High Voltage Device Shutdown Commanded Alive Rolling Count State";
BA_ "PacketOrder" SG_ 558 CDP_HVDevShtdnCdARCSt 5;
BA_ "SignalType" SG_ 558 CDP_HVDevShtdnCdARCSt "ENM";
BA_ "VNSigAllNodes" SG_ 558 CDP_HVDevShtdnCdARCSt 1;
BA_ "SignalLongName" SG_ 558 CDP_CmpSpdReqARCSt "Compressor Data Packet : Compressor Speed Request Alive Rolling Count State";
BA_ "PacketOrder" SG_ 558 CDP_CmpSpdReqARCSt 4;
BA_ "SignalType" SG_ 558 CDP_CmpSpdReqARCSt "ENM";
BA_ "VNSigAllNodes" SG_ 558 CDP_CmpSpdReqARCSt 1;
BA_ "SignalLongName" SG_ 558 CDP_CmpLossCommOcc "Compressor Data Packet : Compressor Loss of Communication Occurred";
BA_ "PacketOrder" SG_ 558 CDP_CmpLossCommOcc 3;
BA_ "SignalType" SG_ 558 CDP_CmpLossCommOcc "BLN";
BA_ "VNSigAllNodes" SG_ 558 CDP_CmpLossCommOcc 1;
BA_ "SignalLongName" SG_ 558 CDP_CmpWkUp "Compressor Data Packet : Compressor Wake up";
BA_ "PacketOrder" SG_ 558 CDP_CmpWkUp 2;
BA_ "SignalType" SG_ 558 CDP_CmpWkUp "BLN";
BA_ "VNSigAllNodes" SG_ 558 CDP_CmpWkUp 1;
BA_ "SignalLongName" SG_ 558 CDP_CmpRunCrnk "Compressor Data Packet : Compressor Run Crank";
BA_ "PacketOrder" SG_ 558 CDP_CmpRunCrnk 1;
BA_ "SignalType" SG_ 558 CDP_CmpRunCrnk "BLN";
BA_ "VNSigAllNodes" SG_ 558 CDP_CmpRunCrnk 1;
BA_ "SignalLongName" SG_ 558 CmpSnsrDevStPktARC "Compressor Device State Packet Alive Rolling Count";
BA_ "SignalType" SG_ 558 CmpSnsrDevStPktARC "UNM";
BA_ "VNSigAllNodes" SG_ 558 CmpSnsrDevStPktARC 1;
BA_ "SignalLongName" SG_ 558 CDSP_CmpOvrTmpSt "Compressor Device State Packet : Compressor Over Temperature State";
BA_ "PacketOrder" SG_ 558 CDSP_CmpOvrTmpSt 5;
BA_ "SignalType" SG_ 558 CDSP_CmpOvrTmpSt "ENM";
BA_ "VNSigAllNodes" SG_ 558 CDSP_CmpOvrTmpSt 1;
BA_ "SignalLongName" SG_ 558 CDSP_CmpHVAbnrlOrVltSt "Compressor Device State Packet : Compressor High Voltage Abnormal Over Voltage State";
BA_ "PacketOrder" SG_ 558 CDSP_CmpHVAbnrlOrVltSt 4;
BA_ "SignalType" SG_ 558 CDSP_CmpHVAbnrlOrVltSt "ENM";
BA_ "VNSigAllNodes" SG_ 558 CDSP_CmpHVAbnrlOrVltSt 1;
BA_ "SignalLongName" SG_ 558 CDSP_CmpHVUndrVltgSt "Compressor Device State Packet : Compressor High Voltage Under Voltage State";
BA_ "PacketOrder" SG_ 558 CDSP_CmpHVUndrVltgSt 3;
BA_ "SignalType" SG_ 558 CDSP_CmpHVUndrVltgSt "ENM";
BA_ "VNSigAllNodes" SG_ 558 CDSP_CmpHVUndrVltgSt 1;
BA_ "SignalLongName" SG_ 558 CDSP_CmpHVOvrVltgSt "Compressor Device State Packet : Compressor High Voltage Over Voltage State";
BA_ "PacketOrder" SG_ 558 CDSP_CmpHVOvrVltgSt 2;
BA_ "SignalType" SG_ 558 CDSP_CmpHVOvrVltgSt "ENM";
BA_ "VNSigAllNodes" SG_ 558 CDSP_CmpHVOvrVltgSt 1;
BA_ "SignalLongName" SG_ 558 CDSP_CmpHVOvrCrntSt "Compressor Device State Packet : Compressor High Voltage Over Current State";
BA_ "PacketOrder" SG_ 558 CDSP_CmpHVOvrCrntSt 1;
BA_ "SignalType" SG_ 558 CDSP_CmpHVOvrCrntSt "ENM";
BA_ "VNSigAllNodes" SG_ 558 CDSP_CmpHVOvrCrntSt 1;
BA_ "SignalLongName" SG_ 558 CDSP_OvrTempWrnInd "Compressor Device State Packet : Over Temperature Warning Indication";
BA_ "PacketOrder" SG_ 558 CDSP_OvrTempWrnInd 15;
BA_ "SignalType" SG_ 558 CDSP_OvrTempWrnInd "BLN";
BA_ "VNSigAllNodes" SG_ 558 CDSP_OvrTempWrnInd 1;
BA_ "SignalLongName" SG_ 558 CDSP_CmpDgrdOp "Compressor Device State Packet : Compressor Degraded Operation";
BA_ "PacketOrder" SG_ 558 CDSP_CmpDgrdOp 14;
BA_ "SignalType" SG_ 558 CDSP_CmpDgrdOp "BLN";
BA_ "VNSigAllNodes" SG_ 558 CDSP_CmpDgrdOp 1;
BA_ "SignalLongName" SG_ 558 CDSP_CmpIntShdwnFltSt "Compressor Device State Packet : Compressor Internal Shutdown Fault State";
BA_ "PacketOrder" SG_ 558 CDSP_CmpIntShdwnFltSt 13;
BA_ "SignalType" SG_ 558 CDSP_CmpIntShdwnFltSt "ENM";
BA_ "VNSigAllNodes" SG_ 558 CDSP_CmpIntShdwnFltSt 1;
BA_ "SignalLongName" SG_ 558 CDSP_CmpIntRecblFltSt "Compressor Device State Packet : Compressor Internal Recoverable Fault State";
BA_ "PacketOrder" SG_ 558 CDSP_CmpIntRecblFltSt 12;
BA_ "SignalType" SG_ 558 CDSP_CmpIntRecblFltSt "ENM";
BA_ "VNSigAllNodes" SG_ 558 CDSP_CmpIntRecblFltSt 1;
BA_ "SignalLongName" SG_ 558 CDSP_CmpOpOvrldSt "Compressor Device State Packet : Compressor Output Overload State";
BA_ "PacketOrder" SG_ 558 CDSP_CmpOpOvrldSt 11;
BA_ "SignalType" SG_ 558 CDSP_CmpOpOvrldSt "ENM";
BA_ "VNSigAllNodes" SG_ 558 CDSP_CmpOpOvrldSt 1;
BA_ "SignalLongName" SG_ 558 CDSP_CmpDrCrctFltSt "Compressor Device State Packet : Compressor Drive Circuit Fault State";
BA_ "PacketOrder" SG_ 558 CDSP_CmpDrCrctFltSt 10;
BA_ "SignalType" SG_ 558 CDSP_CmpDrCrctFltSt "ENM";
BA_ "VNSigAllNodes" SG_ 558 CDSP_CmpDrCrctFltSt 1;
BA_ "SignalLongName" SG_ 558 CDSP_CmpMtrPerfFltSt "Compressor Device State Packet : Compressor Motor Performance Fault State";
BA_ "PacketOrder" SG_ 558 CDSP_CmpMtrPerfFltSt 9;
BA_ "SignalType" SG_ 558 CDSP_CmpMtrPerfFltSt "ENM";
BA_ "VNSigAllNodes" SG_ 558 CDSP_CmpMtrPerfFltSt 1;
BA_ "SignalLongName" SG_ 558 CDSP_CmpEEPROMFltSt "Compressor Device State Packet : Compressor Electrically Erasable Programmable Read-Only Memory Fault State";
BA_ "PacketOrder" SG_ 558 CDSP_CmpEEPROMFltSt 8;
BA_ "SignalType" SG_ 558 CDSP_CmpEEPROMFltSt "ENM";
BA_ "VNSigAllNodes" SG_ 558 CDSP_CmpEEPROMFltSt 1;
BA_ "SignalLongName" SG_ 558 CDSP_CmpROMFltSt "Compressor Device State Packet : Compressor Read Only Memory Fault State";
BA_ "PacketOrder" SG_ 558 CDSP_CmpROMFltSt 7;
BA_ "SignalType" SG_ 558 CDSP_CmpROMFltSt "ENM";
BA_ "VNSigAllNodes" SG_ 558 CDSP_CmpROMFltSt 1;
BA_ "SignalLongName" SG_ 558 CDSP_CmpRAMFltSt "Compressor Device State Packet : Compressor Random Access Memory Fault State";
BA_ "PacketOrder" SG_ 558 CDSP_CmpRAMFltSt 6;
BA_ "SignalType" SG_ 558 CDSP_CmpRAMFltSt "ENM";
BA_ "VNSigAllNodes" SG_ 558 CDSP_CmpRAMFltSt 1;
BA_ "SignalLongName" SG_ 558 CmpSnsrStPktARC "Compressor Sensor State Packet Alive Rolling Count";
BA_ "SignalType" SG_ 558 CmpSnsrStPktARC "UNM";
BA_ "VNSigAllNodes" SG_ 558 CmpSnsrStPktARC 1;
BA_ "SignalLongName" SG_ 558 CSSP_CmpIGBTTpOtRgLSt "Compressor Sensor State Packet : Compressor Insulated Gate Bipolar Transistor Temperature Out of Range Low State";
BA_ "PacketOrder" SG_ 558 CSSP_CmpIGBTTpOtRgLSt 8;
BA_ "SignalType" SG_ 558 CSSP_CmpIGBTTpOtRgLSt "ENM";
BA_ "VNSigAllNodes" SG_ 558 CSSP_CmpIGBTTpOtRgLSt 1;
BA_ "SignalLongName" SG_ 558 CSSP_CmpIGBTTpOtRgHSt "Compressor Sensor State Packet : Compressor Insulated Gate Bipolar Transistor Temperature Out of Range High State";
BA_ "PacketOrder" SG_ 558 CSSP_CmpIGBTTpOtRgHSt 7;
BA_ "SignalType" SG_ 558 CSSP_CmpIGBTTpOtRgHSt "ENM";
BA_ "VNSigAllNodes" SG_ 558 CSSP_CmpIGBTTpOtRgHSt 1;
BA_ "SignalLongName" SG_ 558 CSSP_CmpCPUTmpOtRgLSt "Compressor Sensor State Packet : Compressor Central Processing Unit Temperature Out of Range Low State";
BA_ "PacketOrder" SG_ 558 CSSP_CmpCPUTmpOtRgLSt 6;
BA_ "SignalType" SG_ 558 CSSP_CmpCPUTmpOtRgLSt "ENM";
BA_ "VNSigAllNodes" SG_ 558 CSSP_CmpCPUTmpOtRgLSt 1;
BA_ "SignalLongName" SG_ 558 CSSP_CmpCPUTmpOtRgHSt "Compressor Sensor State Packet : Compressor Central Processing Unit Temperature Out of Range High State";
BA_ "PacketOrder" SG_ 558 CSSP_CmpCPUTmpOtRgHSt 5;
BA_ "SignalType" SG_ 558 CSSP_CmpCPUTmpOtRgHSt "ENM";
BA_ "VNSigAllNodes" SG_ 558 CSSP_CmpCPUTmpOtRgHSt 1;
BA_ "SignalLongName" SG_ 558 CSSP_CmpHVSnsOtRgLSt "Compressor Sensor State Packet : Compressor High Voltage Sensor Out of Range Low State";
BA_ "PacketOrder" SG_ 558 CSSP_CmpHVSnsOtRgLSt 4;
BA_ "SignalType" SG_ 558 CSSP_CmpHVSnsOtRgLSt "ENM";
BA_ "VNSigAllNodes" SG_ 558 CSSP_CmpHVSnsOtRgLSt 1;
BA_ "SignalLongName" SG_ 558 CSSP_CmpHVSnsOtRgHSt "Compressor Sensor State Packet : Compressor High Voltage Sensor Out of Range High State";
BA_ "PacketOrder" SG_ 558 CSSP_CmpHVSnsOtRgHSt 3;
BA_ "SignalType" SG_ 558 CSSP_CmpHVSnsOtRgHSt "ENM";
BA_ "VNSigAllNodes" SG_ 558 CSSP_CmpHVSnsOtRgHSt 1;
BA_ "SignalLongName" SG_ 558 CSSP_CmpPhCrntOtRgLSt "Compressor Sensor State Packet : Compressor Phase Current Out of Range Low State";
BA_ "PacketOrder" SG_ 558 CSSP_CmpPhCrntOtRgLSt 2;
BA_ "SignalType" SG_ 558 CSSP_CmpPhCrntOtRgLSt "ENM";
BA_ "VNSigAllNodes" SG_ 558 CSSP_CmpPhCrntOtRgLSt 1;
BA_ "SignalLongName" SG_ 558 CSSP_CmpPhCrntOtRgHSt "Compressor Sensor State Packet : Compressor Phase Current Out of Range High State";
BA_ "PacketOrder" SG_ 558 CSSP_CmpPhCrntOtRgHSt 1;
BA_ "SignalType" SG_ 558 CSSP_CmpPhCrntOtRgHSt "ENM";
BA_ "VNSigAllNodes" SG_ 558 CSSP_CmpPhCrntOtRgHSt 1;
BA_ "SignalLongName" SG_ 550 ACCMCII_DtBtG "Air Compressor Control Module Calibration Identification : Data Byte G";
BA_ "PacketOrder" SG_ 550 ACCMCII_DtBtG 10;
BA_ "SignalType" SG_ 550 ACCMCII_DtBtG "ASC";
BA_ "VNSigAllNodes" SG_ 550 ACCMCII_DtBtG 1;
BA_ "SignalLongName" SG_ 550 ACCMCII_DtBtF "Air Compressor Control Module Calibration Identification : Data Byte F";
BA_ "PacketOrder" SG_ 550 ACCMCII_DtBtF 9;
BA_ "SignalType" SG_ 550 ACCMCII_DtBtF "ASC";
BA_ "VNSigAllNodes" SG_ 550 ACCMCII_DtBtF 1;
BA_ "SignalLongName" SG_ 550 ACCMCII_DtBtE "Air Compressor Control Module Calibration Identification : Data Byte E";
BA_ "PacketOrder" SG_ 550 ACCMCII_DtBtE 8;
BA_ "SignalType" SG_ 550 ACCMCII_DtBtE "ASC";
BA_ "VNSigAllNodes" SG_ 550 ACCMCII_DtBtE 1;
BA_ "SignalLongName" SG_ 550 ACCMCII_DtBtD "Air Compressor Control Module Calibration Identification : Data Byte D";
BA_ "PacketOrder" SG_ 550 ACCMCII_DtBtD 7;
BA_ "SignalType" SG_ 550 ACCMCII_DtBtD "ASC";
BA_ "VNSigAllNodes" SG_ 550 ACCMCII_DtBtD 1;
BA_ "SignalLongName" SG_ 550 ACCMCII_DtBtC "Air Compressor Control Module Calibration Identification : Data Byte C";
BA_ "PacketOrder" SG_ 550 ACCMCII_DtBtC 6;
BA_ "SignalType" SG_ 550 ACCMCII_DtBtC "ASC";
BA_ "VNSigAllNodes" SG_ 550 ACCMCII_DtBtC 1;
BA_ "SignalLongName" SG_ 550 ACCMCII_DtBtB "Air Compressor Control Module Calibration Identification : Data Byte B";
BA_ "PacketOrder" SG_ 550 ACCMCII_DtBtB 5;
BA_ "SignalType" SG_ 550 ACCMCII_DtBtB "ASC";
BA_ "VNSigAllNodes" SG_ 550 ACCMCII_DtBtB 1;
BA_ "SignalLongName" SG_ 550 ACCMCII_DtBtA "Air Compressor Control Module Calibration Identification : Data Byte A";
BA_ "PacketOrder" SG_ 550 ACCMCII_DtBtA 4;
BA_ "SignalType" SG_ 550 ACCMCII_DtBtA "ASC";
BA_ "VNSigAllNodes" SG_ 550 ACCMCII_DtBtA 1;
BA_ "SignalLongName" SG_ 550 ACCMCII_SeqNum "Air Compressor Control Module Calibration Identification : Sequence Number";
BA_ "PacketOrder" SG_ 550 ACCMCII_SeqNum 3;
BA_ "SignalType" SG_ 550 ACCMCII_SeqNum "UNM";
BA_ "VNSigAllNodes" SG_ 550 ACCMCII_SeqNum 1;
BA_ "SignalLongName" SG_ 550 ACCMCII_Index "Air Compressor Control Module Calibration Identification : Index";
BA_ "PacketOrder" SG_ 550 ACCMCII_Index 1;
BA_ "SignalType" SG_ 550 ACCMCII_Index "UNM";
BA_ "VNSigAllNodes" SG_ 550 ACCMCII_Index 1;
BA_ "SignalLongName" SG_ 550 ACCMCII_DatStat "Air Compressor Control Module Calibration Identification : Data Status";
BA_ "PacketOrder" SG_ 550 ACCMCII_DatStat 2;
BA_ "SignalType" SG_ 550 ACCMCII_DatStat "ENM";
BA_ "VNSigAllNodes" SG_ 550 ACCMCII_DatStat 1;
BA_ "SignalLongName" SG_ 504 EngCylDsrdFirngFractn "Engine Cylinder Desired Firing Fraction";
BA_ "SignalType" SG_ 504 EngCylDsrdFirngFractn "UNM";
BA_ "VNSigAllNodes" SG_ 504 EngCylDsrdFirngFractn 1;
BA_ "SignalLongName" SG_ 504 EngCylCalcFirngFractn "Engine Cylinder Calculated Firing Fraction";
BA_ "SignalType" SG_ 504 EngCylCalcFirngFractn "UNM";
BA_ "VNSigAllNodes" SG_ 504 EngCylCalcFirngFractn 1;
BA_ "SignalLongName" SG_ 730 PlatAnlgMdSwPVal "Platform Analog Mode Switch Protection Value";
BA_ "SignalType" SG_ 730 PlatAnlgMdSwPVal "UNM";
BA_ "VNSigAllNodes" SG_ 730 PlatAnlgMdSwPVal 1;
BA_ "SignalLongName" SG_ 730 PlatAnlgMdSwARC "Platform Analog Mode Switch Alive Rolling Count";
BA_ "SignalType" SG_ 730 PlatAnlgMdSwARC "UNM";
BA_ "VNSigAllNodes" SG_ 730 PlatAnlgMdSwARC 1;
BA_ "SignalLongName" SG_ 730 PAMS_DrvMdSwStck "Platform Analog Mode Switch : Driver Mode Switch Stuck";
BA_ "PacketOrder" SG_ 730 PAMS_DrvMdSwStck 6;
BA_ "SignalType" SG_ 730 PAMS_DrvMdSwStck "BLN";
BA_ "VNSigAllNodes" SG_ 730 PAMS_DrvMdSwStck 1;
BA_ "SignalLongName" SG_ 730 PAMS_Sw4Stck "Platform Analog Mode Switch : Switch 4 Stuck";
BA_ "PacketOrder" SG_ 730 PAMS_Sw4Stck 5;
BA_ "SignalType" SG_ 730 PAMS_Sw4Stck "BLN";
BA_ "VNSigAllNodes" SG_ 730 PAMS_Sw4Stck 1;
BA_ "SignalLongName" SG_ 730 PAMS_Sw3Stck "Platform Analog Mode Switch : Switch 3 Stuck";
BA_ "PacketOrder" SG_ 730 PAMS_Sw3Stck 4;
BA_ "SignalType" SG_ 730 PAMS_Sw3Stck "BLN";
BA_ "VNSigAllNodes" SG_ 730 PAMS_Sw3Stck 1;
BA_ "SignalLongName" SG_ 730 PAMS_Sw2Stck "Platform Analog Mode Switch : Switch 2 Stuck";
BA_ "PacketOrder" SG_ 730 PAMS_Sw2Stck 3;
BA_ "SignalType" SG_ 730 PAMS_Sw2Stck "BLN";
BA_ "VNSigAllNodes" SG_ 730 PAMS_Sw2Stck 1;
BA_ "SignalLongName" SG_ 730 PAMS_Sw1Stck "Platform Analog Mode Switch : Switch 1 Stuck";
BA_ "PacketOrder" SG_ 730 PAMS_Sw1Stck 2;
BA_ "SignalType" SG_ 730 PAMS_Sw1Stck "BLN";
BA_ "VNSigAllNodes" SG_ 730 PAMS_Sw1Stck 1;
BA_ "SignalLongName" SG_ 730 PAMS_SwStat "Platform Analog Mode Switch : Switch Status";
BA_ "PacketOrder" SG_ 730 PAMS_SwStat 1;
BA_ "SignalType" SG_ 730 PAMS_SwStat "ENM";
BA_ "VNSigAllNodes" SG_ 730 PAMS_SwStat 1;
BA_ "SignalLongName" SG_ 458 ACCAxlTrqReqStatPVal "Adaptive Cruise Control Axle Torque Request Status Protection Value";
BA_ "SignalType" SG_ 458 ACCAxlTrqReqStatPVal "UNM";
BA_ "VNSigAllNodes" SG_ 458 ACCAxlTrqReqStatPVal 1;
BA_ "SignalLongName" SG_ 458 ACCAxlTrqReqStat "Adaptive Cruise Control Axle Torque Request Status";
BA_ "SignalType" SG_ 458 ACCAxlTrqReqStat "ENM";
BA_ "VNSigAllNodes" SG_ 458 ACCAxlTrqReqStat 1;
BA_ "SignalLongName" SG_ 458 DrRqdAxleTrqPVal "Driver Requested Axle Torque Protection Value";
BA_ "SignalType" SG_ 458 DrRqdAxleTrqPVal "UNM";
BA_ "VNSigAllNodes" SG_ 458 DrRqdAxleTrqPVal 1;
BA_ "SignalLongName" SG_ 458 DrRqdAxleTrqARC "Driver Requested Axle Torque Alive Rolling Count";
BA_ "SignalType" SG_ 458 DrRqdAxleTrqARC "UNM";
BA_ "VNSigAllNodes" SG_ 458 DrRqdAxleTrqARC 1;
BA_ "SignalLongName" SG_ 458 DRAT_TrqIncr "Driver Requested Axle Torque : Torque Increase";
BA_ "PacketOrder" SG_ 458 DRAT_TrqIncr 1;
BA_ "SignalType" SG_ 458 DRAT_TrqIncr "BLN";
BA_ "VNSigAllNodes" SG_ 458 DRAT_TrqIncr 1;
BA_ "SignalLongName" SG_ 458 DRAT_TrqVal "Driver Requested Axle Torque : Torque Value";
BA_ "PacketOrder" SG_ 458 DRAT_TrqVal 2;
BA_ "SignalType" SG_ 458 DRAT_TrqVal "UNM";
BA_ "VNSigAllNodes" SG_ 458 DRAT_TrqVal 1;
BA_ "SignalLongName" SG_ 426 EngStlSvrActARC "Engine Stall Saver Active Alive Rolling Count";
BA_ "SignalType" SG_ 426 EngStlSvrActARC "UNM";
BA_ "VNSigAllNodes" SG_ 426 EngStlSvrActARC 1;
BA_ "SignalLongName" SG_ 426 EngStlSvrAct "Engine Stall Saver Active";
BA_ "SignalType" SG_ 426 EngStlSvrAct "BLN";
BA_ "VNSigAllNodes" SG_ 426 EngStlSvrAct 1;
BA_ "SignalLongName" SG_ 426 EngPstnSnsngOpMode "Engine Position Sensing Operating Mode";
BA_ "SignalType" SG_ 426 EngPstnSnsngOpMode "ENM";
BA_ "VNSigAllNodes" SG_ 426 EngPstnSnsngOpMode 1;
BA_ "SignalLongName" SG_ 426 AuxTransPrsCmndOn "Auxiliary Transmission Pressure Commanded On";
BA_ "SignalType" SG_ 426 AuxTransPrsCmndOn "BLN";
BA_ "VNSigAllNodes" SG_ 426 AuxTransPrsCmndOn 1;
BA_ "SignalLongName" SG_ 426 EVTCS_CmdTrqCapMd "Engine Variable Torque Capacity Status : Commanded Torque Capacity Mode";
BA_ "PacketOrder" SG_ 426 EVTCS_CmdTrqCapMd 2;
BA_ "SignalType" SG_ 426 EVTCS_CmdTrqCapMd "ENM";
BA_ "VNSigAllNodes" SG_ 426 EVTCS_CmdTrqCapMd 1;
BA_ "SignalLongName" SG_ 426 EVTCS_CrntTrqCapMd "Engine Variable Torque Capacity Status : Current Torque Capacity Mode";
BA_ "PacketOrder" SG_ 426 EVTCS_CrntTrqCapMd 1;
BA_ "SignalType" SG_ 426 EVTCS_CrntTrqCapMd "ENM";
BA_ "VNSigAllNodes" SG_ 426 EVTCS_CrntTrqCapMd 1;
BA_ "SignalLongName" SG_ 426 EngPrdctStdyStTorq "Engine Predicted Steady State Torque";
BA_ "SignalType" SG_ 426 EngPrdctStdyStTorq "UNM";
BA_ "VNSigAllNodes" SG_ 426 EngPrdctStdyStTorq 1;
BA_ "SignalLongName" SG_ 426 EngPrdctStdyStTorqV "Engine Predicted Steady State Torque Validity";
BA_ "SignalType" SG_ 426 EngPrdctStdyStTorqV "ENM";
BA_ "VNSigAllNodes" SG_ 426 EngPrdctStdyStTorqV 1;
BA_ "SignalLongName" SG_ 426 CrnkShftTrqMinOffCapV "Crankshaft Torque Minimum Off Capacity Validity";
BA_ "SignalType" SG_ 426 CrnkShftTrqMinOffCapV "ENM";
BA_ "VNSigAllNodes" SG_ 426 CrnkShftTrqMinOffCapV 1;
BA_ "SignalLongName" SG_ 426 CrnkShftTrqMinOffCap "Crankshaft Torque Minimum Off Capacity";
BA_ "SignalType" SG_ 426 CrnkShftTrqMinOffCap "UNM";
BA_ "VNSigAllNodes" SG_ 426 CrnkShftTrqMinOffCap 1;
BA_ "SignalLongName" SG_ 426 CrksftTqMinRunImCapV "Crankshaft Torque Minimum Run Immediate Capacity Validity";
BA_ "SignalType" SG_ 426 CrksftTqMinRunImCapV "ENM";
BA_ "VNSigAllNodes" SG_ 426 CrksftTqMinRunImCapV 1;
BA_ "SignalLongName" SG_ 426 CrksftTqMinRunImCap "Crankshaft Torque Minimum Run Immediate Capacity";
BA_ "SignalType" SG_ 426 CrksftTqMinRunImCap "UNM";
BA_ "VNSigAllNodes" SG_ 426 CrksftTqMinRunImCap 1;
BA_ "SignalLongName" SG_ 405 EngDistFuelMdDefltd "Engine Distributed Fuel Mode Defaulted";
BA_ "SignalType" SG_ 405 EngDistFuelMdDefltd "BLN";
BA_ "VNSigAllNodes" SG_ 405 EngDistFuelMdDefltd 1;
BA_ "SignalLongName" SG_ 405 EngInjEnbldD "Engine Injector Enabled D";
BA_ "SignalType" SG_ 405 EngInjEnbldD "BLN";
BA_ "VNSigAllNodes" SG_ 405 EngInjEnbldD 1;
BA_ "SignalLongName" SG_ 405 EngInjEnbldC "Engine Injector Enabled C";
BA_ "SignalType" SG_ 405 EngInjEnbldC "BLN";
BA_ "VNSigAllNodes" SG_ 405 EngInjEnbldC 1;
BA_ "SignalLongName" SG_ 405 EngInjEnbldB "Engine Injector Enabled B";
BA_ "SignalType" SG_ 405 EngInjEnbldB "BLN";
BA_ "VNSigAllNodes" SG_ 405 EngInjEnbldB 1;
BA_ "SignalLongName" SG_ 405 EngInjEnbldA "Engine Injector Enabled A";
BA_ "SignalType" SG_ 405 EngInjEnbldA "BLN";
BA_ "VNSigAllNodes" SG_ 405 EngInjEnbldA 1;
BA_ "SignalLongName" SG_ 405 ThrPosV "Throttle Position Validity";
BA_ "SignalType" SG_ 405 ThrPosV "ENM";
BA_ "VNSigAllNodes" SG_ 405 ThrPosV 1;
BA_ "SignalLongName" SG_ 405 ThrPos "Throttle Position";
BA_ "SignalType" SG_ 405 ThrPos "UNM";
BA_ "VNSigAllNodes" SG_ 405 ThrPos 1;
BA_ "SignalLongName" SG_ 405 MassAirFloV "Mass Air Flow Validity";
BA_ "SignalType" SG_ 405 MassAirFloV "ENM";
BA_ "VNSigAllNodes" SG_ 405 MassAirFloV 1;
BA_ "SignalLongName" SG_ 405 MassAirFlo "Mass Air Flow";
BA_ "SignalType" SG_ 405 MassAirFlo "UNM";
BA_ "VNSigAllNodes" SG_ 405 MassAirFlo 1;
BA_ "SignalLongName" SG_ 405 EngManfldAbsPrsERV "Engine Manifold Absolute Pressure Extended Range Validity";
BA_ "SignalType" SG_ 405 EngManfldAbsPrsERV "ENM";
BA_ "VNSigAllNodes" SG_ 405 EngManfldAbsPrsERV 1;
BA_ "SignalLongName" SG_ 405 EngManfldAbsPrsER "Engine Manifold Absolute Pressure Extended Range";
BA_ "SignalType" SG_ 405 EngManfldAbsPrsER "UNM";
BA_ "VNSigAllNodes" SG_ 405 EngManfldAbsPrsER 1;
BA_ "SignalLongName" SG_ 442 CrksftTqMinImCapV "Crankshaft Torque Minimum Immediate Capacity Validity";
BA_ "SignalType" SG_ 442 CrksftTqMinImCapV "ENM";
BA_ "VNSigAllNodes" SG_ 442 CrksftTqMinImCapV 1;
BA_ "SignalLongName" SG_ 442 CrksftTqMinImCap "Crankshaft Torque Minimum Immediate Capacity";
BA_ "SignalType" SG_ 442 CrksftTqMinImCap "UNM";
BA_ "VNSigAllNodes" SG_ 442 CrksftTqMinImCap 1;
BA_ "SignalLongName" SG_ 442 DrvIntndCrksftTrqRw "Driver Intended Crankshaft Torque Raw";
BA_ "SignalType" SG_ 442 DrvIntndCrksftTrqRw "UNM";
BA_ "VNSigAllNodes" SG_ 442 DrvIntndCrksftTrqRw 1;
BA_ "SignalLongName" SG_ 442 DrvIntndCrksftTrqMin "Driver Intended Crankshaft Torque Minimum";
BA_ "SignalType" SG_ 442 DrvIntndCrksftTrqMin "UNM";
BA_ "VNSigAllNodes" SG_ 442 DrvIntndCrksftTrqMin 1;
BA_ "SignalLongName" SG_ 442 DrvIntndCrksftTrq "Driver Intended Crankshaft Torque";
BA_ "SignalType" SG_ 442 DrvIntndCrksftTrq "UNM";
BA_ "VNSigAllNodes" SG_ 442 DrvIntndCrksftTrq 1;
BA_ "SignalLongName" SG_ 442 CrksftMaxTrqLmtV "Crankshaft Maximum Torque Limit Validity";
BA_ "SignalType" SG_ 442 CrksftMaxTrqLmtV "ENM";
BA_ "VNSigAllNodes" SG_ 442 CrksftMaxTrqLmtV 1;
BA_ "SignalLongName" SG_ 442 CrksftMaxTrqLmt "Crankshaft Maximum Torque Limit";
BA_ "SignalType" SG_ 442 CrksftMaxTrqLmt "UNM";
BA_ "VNSigAllNodes" SG_ 442 CrksftMaxTrqLmt 1;
BA_ "SignalLongName" SG_ 1417 PrplsnTrqRelCap "Propulsion Torque Relative Capability";
BA_ "SignalType" SG_ 1417 PrplsnTrqRelCap "UNM";
BA_ "VNSigAllNodes" SG_ 1417 PrplsnTrqRelCap 1;
BA_ "SignalLongName" SG_ 1417 ETC_MinTorq "Engine Torque Capability : Minimum Torque";
BA_ "PacketOrder" SG_ 1417 ETC_MinTorq 7;
BA_ "SignalType" SG_ 1417 ETC_MinTorq "UNM";
BA_ "VNSigAllNodes" SG_ 1417 ETC_MinTorq 1;
BA_ "SignalLongName" SG_ 1417 ETC_MinRunTorq "Engine Torque Capability : Minimum Run Torque";
BA_ "PacketOrder" SG_ 1417 ETC_MinRunTorq 6;
BA_ "SignalType" SG_ 1417 ETC_MinRunTorq "UNM";
BA_ "VNSigAllNodes" SG_ 1417 ETC_MinRunTorq 1;
BA_ "SignalLongName" SG_ 1417 ETC_MaxTorq "Engine Torque Capability : Maximum Torque";
BA_ "PacketOrder" SG_ 1417 ETC_MaxTorq 5;
BA_ "SignalType" SG_ 1417 ETC_MaxTorq "UNM";
BA_ "VNSigAllNodes" SG_ 1417 ETC_MaxTorq 1;
BA_ "SignalLongName" SG_ 1417 ETC_RefEngSpd "Engine Torque Capability : Reference Engine Speed";
BA_ "PacketOrder" SG_ 1417 ETC_RefEngSpd 4;
BA_ "SignalType" SG_ 1417 ETC_RefEngSpd "UNM";
BA_ "VNSigAllNodes" SG_ 1417 ETC_RefEngSpd 1;
BA_ "SignalLongName" SG_ 1417 ETC_UnsdRsrvd "Engine Torque Capability : Unused and Reserved";
BA_ "PacketOrder" SG_ 1417 ETC_UnsdRsrvd 3;
BA_ "SignalType" SG_ 1417 ETC_UnsdRsrvd "UNM";
BA_ "VNSigAllNodes" SG_ 1417 ETC_UnsdRsrvd 1;
BA_ "SignalLongName" SG_ 1417 ETC_FrmCntr "Engine Torque Capability : Frame Counter";
BA_ "PacketOrder" SG_ 1417 ETC_FrmCntr 2;
BA_ "SignalType" SG_ 1417 ETC_FrmCntr "UNM";
BA_ "VNSigAllNodes" SG_ 1417 ETC_FrmCntr 1;
BA_ "SignalLongName" SG_ 1417 ETC_EngOpMd "Engine Torque Capability : Engine Operating Mode";
BA_ "PacketOrder" SG_ 1417 ETC_EngOpMd 1;
BA_ "SignalType" SG_ 1417 ETC_EngOpMd "ENM";
BA_ "VNSigAllNodes" SG_ 1417 ETC_EngOpMd 1;
BA_REL_ "GenSigTimeoutTime" BU_SG_REL_ CGM_HS SG_ 568 a_12VSysVlt 250;
BA_REL_ "GenSigTimeoutMsg" BU_SG_REL_ CGM_HS SG_ 568 a_12VSysVlt 568;
BA_REL_ "GenSigSuprvResp" BU_SG_REL_ CGM_HS SG_ 568 a_12VSysVlt 1;
BA_REL_ "GenSigTimeoutTime" BU_SG_REL_ CGM_HS SG_ 1919 DTCI_DTCFaultType_77F 2500;
BA_REL_ "GenSigTimeoutMsg" BU_SG_REL_ CGM_HS SG_ 1919 DTCI_DTCFaultType_77F 1919;
BA_REL_ "GenSigSuprvResp" BU_SG_REL_ CGM_HS SG_ 1919 DTCI_DTCFaultType_77F 1;
BA_REL_ "GenSigTimeoutTime" BU_SG_REL_ CGM_HS SG_ 1919 DTCI_CodeSupported_77F 2500;
BA_REL_ "GenSigTimeoutMsg" BU_SG_REL_ CGM_HS SG_ 1919 DTCI_CodeSupported_77F 1919;
BA_REL_ "GenSigSuprvResp" BU_SG_REL_ CGM_HS SG_ 1919 DTCI_CodeSupported_77F 1;
BA_REL_ "GenSigTimeoutTime" BU_SG_REL_ CGM_HS SG_ 1919 DTCI_CurrentStatus_77F 2500;
BA_REL_ "GenSigTimeoutMsg" BU_SG_REL_ CGM_HS SG_ 1919 DTCI_CurrentStatus_77F 1919;
BA_REL_ "GenSigSuprvResp" BU_SG_REL_ CGM_HS SG_ 1919 DTCI_CurrentStatus_77F 1;
BA_REL_ "GenSigTimeoutTime" BU_SG_REL_ CGM_HS SG_ 1919 DTCI_TstNPsdCdClrdSt_77F 2500;
BA_REL_ "GenSigTimeoutMsg" BU_SG_REL_ CGM_HS SG_ 1919 DTCI_TstNPsdCdClrdSt_77F 1919;
BA_REL_ "GenSigSuprvResp" BU_SG_REL_ CGM_HS SG_ 1919 DTCI_TstNPsdCdClrdSt_77F 1;
BA_REL_ "GenSigTimeoutTime" BU_SG_REL_ CGM_HS SG_ 1919 DTCI_TstFldCdClrdStat_77F 2500;
BA_REL_ "GenSigTimeoutMsg" BU_SG_REL_ CGM_HS SG_ 1919 DTCI_TstFldCdClrdStat_77F 1919;
BA_REL_ "GenSigSuprvResp" BU_SG_REL_ CGM_HS SG_ 1919 DTCI_TstFldCdClrdStat_77F 1;
BA_REL_ "GenSigTimeoutTime" BU_SG_REL_ CGM_HS SG_ 1919 DTCI_HistStat_77F 2500;
BA_REL_ "GenSigTimeoutMsg" BU_SG_REL_ CGM_HS SG_ 1919 DTCI_HistStat_77F 1919;
BA_REL_ "GenSigSuprvResp" BU_SG_REL_ CGM_HS SG_ 1919 DTCI_HistStat_77F 1;
BA_REL_ "GenSigTimeoutTime" BU_SG_REL_ CGM_HS SG_ 1919 DTCI_TstNPsdPwrUpSt_77F 2500;
BA_REL_ "GenSigTimeoutMsg" BU_SG_REL_ CGM_HS SG_ 1919 DTCI_TstNPsdPwrUpSt_77F 1919;
BA_REL_ "GenSigSuprvResp" BU_SG_REL_ CGM_HS SG_ 1919 DTCI_TstNPsdPwrUpSt_77F 1;
BA_REL_ "GenSigTimeoutTime" BU_SG_REL_ CGM_HS SG_ 1919 DTCI_TstFldPwrUpSt_77F 2500;
BA_REL_ "GenSigTimeoutMsg" BU_SG_REL_ CGM_HS SG_ 1919 DTCI_TstFldPwrUpSt_77F 1919;
BA_REL_ "GenSigSuprvResp" BU_SG_REL_ CGM_HS SG_ 1919 DTCI_TstFldPwrUpSt_77F 1;
BA_REL_ "GenSigTimeoutTime" BU_SG_REL_ CGM_HS SG_ 1919 DTCI_WrnIndRqdSt_77F 2500;
BA_REL_ "GenSigTimeoutMsg" BU_SG_REL_ CGM_HS SG_ 1919 DTCI_WrnIndRqdSt_77F 1919;
BA_REL_ "GenSigSuprvResp" BU_SG_REL_ CGM_HS SG_ 1919 DTCI_WrnIndRqdSt_77F 1;
BA_REL_ "GenSigTimeoutTime" BU_SG_REL_ CGM_HS SG_ 1919 DTCI_DTCFailType_77F 2500;
BA_REL_ "GenSigTimeoutMsg" BU_SG_REL_ CGM_HS SG_ 1919 DTCI_DTCFailType_77F 1919;
BA_REL_ "GenSigSuprvResp" BU_SG_REL_ CGM_HS SG_ 1919 DTCI_DTCFailType_77F 1;
BA_REL_ "GenSigTimeoutTime" BU_SG_REL_ CGM_HS SG_ 1919 DTCI_DTCNumber_77F 2500;
BA_REL_ "GenSigTimeoutMsg" BU_SG_REL_ CGM_HS SG_ 1919 DTCI_DTCNumber_77F 1919;
BA_REL_ "GenSigSuprvResp" BU_SG_REL_ CGM_HS SG_ 1919 DTCI_DTCNumber_77F 1;
BA_REL_ "GenSigTimeoutTime" BU_SG_REL_ CGM_HS SG_ 1919 DTCI_DTCSource_77F 2500;
BA_REL_ "GenSigTimeoutMsg" BU_SG_REL_ CGM_HS SG_ 1919 DTCI_DTCSource_77F 1919;
BA_REL_ "GenSigSuprvResp" BU_SG_REL_ CGM_HS SG_ 1919 DTCI_DTCSource_77F 1;
BA_REL_ "GenSigTimeoutTime" BU_SG_REL_ CGM_HS SG_ 1919 DTCI_DTCTriggered_77F 2500;
BA_REL_ "GenSigTimeoutMsg" BU_SG_REL_ CGM_HS SG_ 1919 DTCI_DTCTriggered_77F 1919;
BA_REL_ "GenSigSuprvResp" BU_SG_REL_ CGM_HS SG_ 1919 DTCI_DTCTriggered_77F 1;
BA_REL_ "GenSigTimeoutTime" BU_SG_REL_ CGM_HS SG_ 1919 DTCIUnused7_77F 2500;
BA_REL_ "GenSigTimeoutMsg" BU_SG_REL_ CGM_HS SG_ 1919 DTCIUnused7_77F 1919;
BA_REL_ "GenSigSuprvResp" BU_SG_REL_ CGM_HS SG_ 1919 DTCIUnused7_77F 1;
BA_REL_ "GenSigTimeoutTime" BU_SG_REL_ CGM_HS SG_ 1919 DTCIUnused6_77F 2500;
BA_REL_ "GenSigTimeoutMsg" BU_SG_REL_ CGM_HS SG_ 1919 DTCIUnused6_77F 1919;
BA_REL_ "GenSigSuprvResp" BU_SG_REL_ CGM_HS SG_ 1919 DTCIUnused6_77F 1;
BA_REL_ "GenSigTimeoutTime" BU_SG_REL_ CGM_HS SG_ 1919 DTCIUnused5_77F 2500;
BA_REL_ "GenSigTimeoutMsg" BU_SG_REL_ CGM_HS SG_ 1919 DTCIUnused5_77F 1919;
BA_REL_ "GenSigSuprvResp" BU_SG_REL_ CGM_HS SG_ 1919 DTCIUnused5_77F 1;
BA_REL_ "GenSigTimeoutTime" BU_SG_REL_ CGM_HS SG_ 1919 DTCIUnused4_77F 2500;
BA_REL_ "GenSigTimeoutMsg" BU_SG_REL_ CGM_HS SG_ 1919 DTCIUnused4_77F 1919;
BA_REL_ "GenSigSuprvResp" BU_SG_REL_ CGM_HS SG_ 1919 DTCIUnused4_77F 1;
BA_REL_ "GenSigTimeoutTime" BU_SG_REL_ CGM_HS SG_ 1919 DTCIUnused3_77F 2500;
BA_REL_ "GenSigTimeoutMsg" BU_SG_REL_ CGM_HS SG_ 1919 DTCIUnused3_77F 1919;
BA_REL_ "GenSigSuprvResp" BU_SG_REL_ CGM_HS SG_ 1919 DTCIUnused3_77F 1;
BA_REL_ "GenSigTimeoutTime" BU_SG_REL_ CGM_HS SG_ 1919 DTCIUnused2_77F 2500;
BA_REL_ "GenSigTimeoutMsg" BU_SG_REL_ CGM_HS SG_ 1919 DTCIUnused2_77F 1919;
BA_REL_ "GenSigSuprvResp" BU_SG_REL_ CGM_HS SG_ 1919 DTCIUnused2_77F 1;
BA_REL_ "GenSigTimeoutTime" BU_SG_REL_ CGM_HS SG_ 1919 DTCIUnused1_77F 2500;
BA_REL_ "GenSigTimeoutMsg" BU_SG_REL_ CGM_HS SG_ 1919 DTCIUnused1_77F 1919;
BA_REL_ "GenSigSuprvResp" BU_SG_REL_ CGM_HS SG_ 1919 DTCIUnused1_77F 1;
BA_REL_ "GenSigTimeoutTime" BU_SG_REL_ CGM_HS SG_ 388 LKADrvAppldTrq 250;
BA_REL_ "GenSigTimeoutMsg" BU_SG_REL_ CGM_HS SG_ 388 LKADrvAppldTrq 388;
BA_REL_ "GenSigSuprvResp" BU_SG_REL_ CGM_HS SG_ 388 LKADrvAppldTrq 1;
BA_REL_ "GenSigTimeoutTime" BU_SG_REL_ CGM_HS SG_ 388 HndsOffStrWhlDtSt 250;
BA_REL_ "GenSigTimeoutMsg" BU_SG_REL_ CGM_HS SG_ 388 HndsOffStrWhlDtSt 388;
BA_REL_ "GenSigSuprvResp" BU_SG_REL_ CGM_HS SG_ 388 HndsOffStrWhlDtSt 1;
BA_REL_ "GenSigTimeoutTime" BU_SG_REL_ CGM_HS SG_ 388 HndsOffStrWhlDtMd 250;
BA_REL_ "GenSigTimeoutMsg" BU_SG_REL_ CGM_HS SG_ 388 HndsOffStrWhlDtMd 388;
BA_REL_ "GenSigSuprvResp" BU_SG_REL_ CGM_HS SG_ 388 HndsOffStrWhlDtMd 1;
BA_REL_ "GenSigTimeoutTime" BU_SG_REL_ CGM_HS SG_ 388 LKATrqOvrlDltTrqDlvd 250;
BA_REL_ "GenSigTimeoutMsg" BU_SG_REL_ CGM_HS SG_ 388 LKATrqOvrlDltTrqDlvd 388;
BA_REL_ "GenSigSuprvResp" BU_SG_REL_ CGM_HS SG_ 388 LKATrqOvrlDltTrqDlvd 1;
BA_REL_ "GenSigTimeoutTime" BU_SG_REL_ CGM_HS SG_ 388 LKAElPwrStTtlTqDlvd 250;
BA_REL_ "GenSigTimeoutMsg" BU_SG_REL_ CGM_HS SG_ 388 LKAElPwrStTtlTqDlvd 388;
BA_REL_ "GenSigSuprvResp" BU_SG_REL_ CGM_HS SG_ 388 LKAElPwrStTtlTqDlvd 1;
BA_REL_ "GenSigTimeoutTime" BU_SG_REL_ CGM_HS SG_ 388 LKATrqOvrlTrqDStat 250;
BA_REL_ "GenSigTimeoutMsg" BU_SG_REL_ CGM_HS SG_ 388 LKATrqOvrlTrqDStat 388;
BA_REL_ "GenSigSuprvResp" BU_SG_REL_ CGM_HS SG_ 388 LKATrqOvrlTrqDStat 1;
BA_REL_ "GenSigTimeoutTime" BU_SG_REL_ BSM_HS SG_ 546 ThrmlRefCmpIGBTTmp 500;
BA_REL_ "GenSigTimeoutMsg" BU_SG_REL_ BSM_HS SG_ 546 ThrmlRefCmpIGBTTmp 546;
BA_REL_ "GenSigSuprvResp" BU_SG_REL_ BSM_HS SG_ 546 ThrmlRefCmpIGBTTmp 1;
BA_REL_ "GenSigTimeoutTime" BU_SG_REL_ BSM_HS SG_ 546 ThrmlRefCmpCPUHtSkTmp 500;
BA_REL_ "GenSigTimeoutMsg" BU_SG_REL_ BSM_HS SG_ 546 ThrmlRefCmpCPUHtSkTmp 546;
BA_REL_ "GenSigSuprvResp" BU_SG_REL_ BSM_HS SG_ 546 ThrmlRefCmpCPUHtSkTmp 1;
BA_REL_ "GenSigTimeoutTime" BU_SG_REL_ BSM_HS SG_ 546 ThrmlRefCmpHVInHRsln 500;
BA_REL_ "GenSigTimeoutMsg" BU_SG_REL_ BSM_HS SG_ 546 ThrmlRefCmpHVInHRsln 546;
BA_REL_ "GenSigSuprvResp" BU_SG_REL_ BSM_HS SG_ 546 ThrmlRefCmpHVInHRsln 1;
BA_REL_ "GenSigTimeoutTime" BU_SG_REL_ BSM_HS SG_ 546 ThrmlRfCmprElctrCrnt 500;
BA_REL_ "GenSigTimeoutMsg" BU_SG_REL_ BSM_HS SG_ 546 ThrmlRfCmprElctrCrnt 546;
BA_REL_ "GenSigSuprvResp" BU_SG_REL_ BSM_HS SG_ 546 ThrmlRfCmprElctrCrnt 1;
BA_REL_ "GenSigTimeoutTime" BU_SG_REL_ BSM_HS SG_ 546 ThrmlRefCompSpdFdbck 500;
BA_REL_ "GenSigTimeoutMsg" BU_SG_REL_ BSM_HS SG_ 546 ThrmlRefCompSpdFdbck 546;
BA_REL_ "GenSigSuprvResp" BU_SG_REL_ BSM_HS SG_ 546 ThrmlRefCompSpdFdbck 1;
BA_REL_ "GenSigTimeoutTime" BU_SG_REL_ BSM_HS SG_ 546 ThrmlRefCompStatFdbck 500;
BA_REL_ "GenSigTimeoutMsg" BU_SG_REL_ BSM_HS SG_ 546 ThrmlRefCompStatFdbck 546;
BA_REL_ "GenSigSuprvResp" BU_SG_REL_ BSM_HS SG_ 546 ThrmlRefCompStatFdbck 1;
BA_REL_ "GenSigTimeoutTime" BU_SG_REL_ BSM_HS SG_ 390 RdHVInvRatVlt 500;
BA_REL_ "GenSigTimeoutMsg" BU_SG_REL_ BSM_HS SG_ 390 RdHVInvRatVlt 390;
BA_REL_ "GenSigVBitResp" BU_SG_REL_ BSM_HS SG_ 390 RdHVInvRatVlt 1;
BA_REL_ "GenSigSuprvResp" BU_SG_REL_ BSM_HS SG_ 390 RdHVInvRatVlt 1;
BA_REL_ "GenSigTimeoutTime" BU_SG_REL_ BSM_HS SG_ 390 HESSI_EngStrtTyp 500;
BA_REL_ "GenSigTimeoutMsg" BU_SG_REL_ BSM_HS SG_ 390 HESSI_EngStrtTyp 390;
BA_REL_ "GenSigSuprvResp" BU_SG_REL_ BSM_HS SG_ 390 HESSI_EngStrtTyp 1;
BA_REL_ "GenSigTimeoutTime" BU_SG_REL_ BSM_HS SG_ 390 HESSI_EngStrtStpMd 500;
BA_REL_ "GenSigTimeoutMsg" BU_SG_REL_ BSM_HS SG_ 390 HESSI_EngStrtStpMd 390;
BA_REL_ "GenSigSuprvResp" BU_SG_REL_ BSM_HS SG_ 390 HESSI_EngStrtStpMd 1;
BA_REL_ "GenSigTimeoutTime" BU_SG_REL_ BSM_HS SG_ 390 RdPTHVCntrReq 500;
BA_REL_ "GenSigTimeoutMsg" BU_SG_REL_ BSM_HS SG_ 390 RdPTHVCntrReq 390;
BA_REL_ "GenSigSuprvResp" BU_SG_REL_ BSM_HS SG_ 390 RdPTHVCntrReq 1;
BA_REL_ "GenSigTimeoutTime" BU_SG_REL_ ECM_HS SG_ 418 STGRI_SecTrnGrRatV 250;
BA_REL_ "GenSigTimeoutMsg" BU_SG_REL_ ECM_HS SG_ 418 STGRI_SecTrnGrRatV 418;
BA_REL_ "GenSigSuprvResp" BU_SG_REL_ ECM_HS SG_ 418 STGRI_SecTrnGrRatV 2;
BA_REL_ "GenSigTimeoutTime" BU_SG_REL_ ECM_HS SG_ 418 STGRI_SecTrnGrRat 250;
BA_REL_ "GenSigTimeoutMsg" BU_SG_REL_ ECM_HS SG_ 418 STGRI_SecTrnGrRat 418;
BA_REL_ "GenSigSuprvResp" BU_SG_REL_ ECM_HS SG_ 418 STGRI_SecTrnGrRat 2;
BA_REL_ "GenSigTimeoutTime" BU_SG_REL_ ECM_HS SG_ 418 STGRI_TransGrRatSt 250;
BA_REL_ "GenSigTimeoutMsg" BU_SG_REL_ ECM_HS SG_ 418 STGRI_TransGrRatSt 418;
BA_REL_ "GenSigRxStartValue" BU_SG_REL_ ECM_HS SG_ 418 STGRI_TransGrRatSt "$1 - Normal";
BA_REL_ "GenSigSuprvRespSubValue" BU_SG_REL_ ECM_HS SG_ 418 STGRI_TransGrRatSt 5;
BA_REL_ "GenSigSuprvResp" BU_SG_REL_ ECM_HS SG_ 418 STGRI_TransGrRatSt 2;
BA_REL_ "GenSigTimeoutTime" BU_SG_REL_ ECM_HS SG_ 418 STEGI_SecTransEstGearV 250;
BA_REL_ "GenSigTimeoutMsg" BU_SG_REL_ ECM_HS SG_ 418 STEGI_SecTransEstGearV 418;
BA_REL_ "GenSigSuprvResp" BU_SG_REL_ ECM_HS SG_ 418 STEGI_SecTransEstGearV 1;
BA_REL_ "GenSigTimeoutTime" BU_SG_REL_ ECM_HS SG_ 418 STEGI_SecTransEstGear 250;
BA_REL_ "GenSigTimeoutMsg" BU_SG_REL_ ECM_HS SG_ 418 STEGI_SecTransEstGear 418;
BA_REL_ "GenSigSuprvResp" BU_SG_REL_ ECM_HS SG_ 418 STEGI_SecTransEstGear 1;
BA_REL_ "GenSigTimeoutTime" BU_SG_REL_ ECM_HS SG_ 1236 CGMSDCII_DataVal 2500;
BA_REL_ "GenSigTimeoutMsg" BU_SG_REL_ ECM_HS SG_ 1236 CGMSDCII_DataVal 1236;
BA_REL_ "GenSigSuprvResp" BU_SG_REL_ ECM_HS SG_ 1236 CGMSDCII_DataVal 1;
BA_REL_ "GenSigTimeoutTime" BU_SG_REL_ ECM_HS SG_ 1236 CGMSDCII_DataIndx 2500;
BA_REL_ "GenSigTimeoutMsg" BU_SG_REL_ ECM_HS SG_ 1236 CGMSDCII_DataIndx 1236;
BA_REL_ "GenSigSuprvResp" BU_SG_REL_ ECM_HS SG_ 1236 CGMSDCII_DataIndx 1;
BA_REL_ "GenSigTimeoutTime" BU_SG_REL_ ECM_HS SG_ 1236 CGMSDCII_DataStat 2500;
BA_REL_ "GenSigTimeoutMsg" BU_SG_REL_ ECM_HS SG_ 1236 CGMSDCII_DataStat 1236;
BA_REL_ "GenSigSuprvResp" BU_SG_REL_ ECM_HS SG_ 1236 CGMSDCII_DataStat 1;
BA_REL_ "GenSigTimeoutTime" BU_SG_REL_ ECM_HS SG_ 1236 CGMRCII_DataVal 2500;
BA_REL_ "GenSigTimeoutMsg" BU_SG_REL_ ECM_HS SG_ 1236 CGMRCII_DataVal 1236;
BA_REL_ "GenSigSuprvResp" BU_SG_REL_ ECM_HS SG_ 1236 CGMRCII_DataVal 1;
BA_REL_ "GenSigTimeoutTime" BU_SG_REL_ ECM_HS SG_ 1236 CGMRCII_DataIndx 2500;
BA_REL_ "GenSigTimeoutMsg" BU_SG_REL_ ECM_HS SG_ 1236 CGMRCII_DataIndx 1236;
BA_REL_ "GenSigSuprvResp" BU_SG_REL_ ECM_HS SG_ 1236 CGMRCII_DataIndx 1;
BA_REL_ "GenSigTimeoutTime" BU_SG_REL_ ECM_HS SG_ 1236 CGMRCII_DataStat 2500;
BA_REL_ "GenSigTimeoutMsg" BU_SG_REL_ ECM_HS SG_ 1236 CGMRCII_DataStat 1236;
BA_REL_ "GenSigSuprvResp" BU_SG_REL_ ECM_HS SG_ 1236 CGMRCII_DataStat 1;
BA_REL_ "GenSigTimeoutTime" BU_SG_REL_ ECM_HS SG_ 1236 CGMOCII_DataVal 2500;
BA_REL_ "GenSigTimeoutMsg" BU_SG_REL_ ECM_HS SG_ 1236 CGMOCII_DataVal 1236;
BA_REL_ "GenSigSuprvResp" BU_SG_REL_ ECM_HS SG_ 1236 CGMOCII_DataVal 1;
BA_REL_ "GenSigTimeoutTime" BU_SG_REL_ ECM_HS SG_ 1236 CGMOCII_DataIndx 2500;
BA_REL_ "GenSigTimeoutMsg" BU_SG_REL_ ECM_HS SG_ 1236 CGMOCII_DataIndx 1236;
BA_REL_ "GenSigSuprvResp" BU_SG_REL_ ECM_HS SG_ 1236 CGMOCII_DataIndx 1;
BA_REL_ "GenSigTimeoutTime" BU_SG_REL_ ECM_HS SG_ 1236 CGMOCII_DataStat 2500;
BA_REL_ "GenSigTimeoutMsg" BU_SG_REL_ ECM_HS SG_ 1236 CGMOCII_DataStat 1236;
BA_REL_ "GenSigSuprvResp" BU_SG_REL_ ECM_HS SG_ 1236 CGMOCII_DataStat 1;
BA_REL_ "GenSigTimeoutTime" BU_SG_REL_ ECM_HS SG_ 1236 CGMSII_DataVal 2500;
BA_REL_ "GenSigTimeoutMsg" BU_SG_REL_ ECM_HS SG_ 1236 CGMSII_DataVal 1236;
BA_REL_ "GenSigSuprvResp" BU_SG_REL_ ECM_HS SG_ 1236 CGMSII_DataVal 1;
BA_REL_ "GenSigTimeoutTime" BU_SG_REL_ ECM_HS SG_ 1236 CGMSII_DataIndx 2500;
BA_REL_ "GenSigTimeoutMsg" BU_SG_REL_ ECM_HS SG_ 1236 CGMSII_DataIndx 1236;
BA_REL_ "GenSigSuprvResp" BU_SG_REL_ ECM_HS SG_ 1236 CGMSII_DataIndx 1;
BA_REL_ "GenSigTimeoutTime" BU_SG_REL_ ECM_HS SG_ 1236 CGMSII_DataStat 2500;
BA_REL_ "GenSigTimeoutMsg" BU_SG_REL_ ECM_HS SG_ 1236 CGMSII_DataStat 1236;
BA_REL_ "GenSigSuprvResp" BU_SG_REL_ ECM_HS SG_ 1236 CGMSII_DataStat 1;
BA_REL_ "GenSigTimeoutTime" BU_SG_REL_ ECM_HS SG_ 1195 TransTempOpRgn 2500;
BA_REL_ "GenSigTimeoutMsg" BU_SG_REL_ ECM_HS SG_ 1195 TransTempOpRgn 1195;
BA_REL_ "GenSigSuprvResp" BU_SG_REL_ ECM_HS SG_ 1195 TransTempOpRgn 1;
BA_REL_ "GenSigTimeoutTime" BU_SG_REL_ ECM_HS SG_ 1195 TransOilTempAltVal 2500;
BA_REL_ "GenSigTimeoutMsg" BU_SG_REL_ ECM_HS SG_ 1195 TransOilTempAltVal 1195;
BA_REL_ "GenSigSuprvResp" BU_SG_REL_ ECM_HS SG_ 1195 TransOilTempAltVal 1;
BA_REL_ "GenSigTimeoutTime" BU_SG_REL_ ECM_HS SG_ 1195 TransOilTgtTemp 2500;
BA_REL_ "GenSigTimeoutMsg" BU_SG_REL_ ECM_HS SG_ 1195 TransOilTgtTemp 1195;
BA_REL_ "GenSigSuprvResp" BU_SG_REL_ ECM_HS SG_ 1195 TransOilTgtTemp 1;
BA_REL_ "GenSigTimeoutTime" BU_SG_REL_ ECM_HS SG_ 612 PPSCldrDay 250;
BA_REL_ "GenSigTimeoutMsg" BU_SG_REL_ ECM_HS SG_ 612 PPSCldrDay 612;
BA_REL_ "GenSigSuprvResp" BU_SG_REL_ ECM_HS SG_ 612 PPSCldrDay 1;
BA_REL_ "GenSigTimeoutTime" BU_SG_REL_ ECM_HS SG_ 612 PPSCldrYr 250;
BA_REL_ "GenSigTimeoutMsg" BU_SG_REL_ ECM_HS SG_ 612 PPSCldrYr 612;
BA_REL_ "GenSigSuprvResp" BU_SG_REL_ ECM_HS SG_ 612 PPSCldrYr 1;
BA_REL_ "GenSigTimeoutTime" BU_SG_REL_ ECM_HS SG_ 612 PPSTmday 250;
BA_REL_ "GenSigTimeoutMsg" BU_SG_REL_ ECM_HS SG_ 612 PPSTmday 612;
BA_REL_ "GenSigSuprvResp" BU_SG_REL_ ECM_HS SG_ 612 PPSTmday 1;
BA_REL_ "GenSigTimeoutTime" BU_SG_REL_ ECM_HS SG_ 189 HybDisengCruzCmnd 250;
BA_REL_ "GenSigTimeoutMsg" BU_SG_REL_ ECM_HS SG_ 189 HybDisengCruzCmnd 189;
BA_REL_ "GenSigSuprvResp" BU_SG_REL_ ECM_HS SG_ 189 HybDisengCruzCmnd 1;
BA_REL_ "GenSigTimeoutTime" BU_SG_REL_ ECM_HS SG_ 422 TrnsStatTrkMdOvrd 62;
BA_REL_ "GenSigTimeoutMsg" BU_SG_REL_ ECM_HS SG_ 422 TrnsStatTrkMdOvrd 422;
BA_REL_ "GenSigSuprvResp" BU_SG_REL_ ECM_HS SG_ 422 TrnsStatTrkMdOvrd 1;
BA_REL_ "GenSigTimeoutTime" BU_SG_REL_ ECM_HS SG_ 422 DTPWCPS_CrnkPrmV 62;
BA_REL_ "GenSigTimeoutMsg" BU_SG_REL_ ECM_HS SG_ 422 DTPWCPS_CrnkPrmV 422;
BA_REL_ "GenSigSuprvResp" BU_SG_REL_ ECM_HS SG_ 422 DTPWCPS_CrnkPrmV 1;
BA_REL_ "GenSigTimeoutTime" BU_SG_REL_ ECM_HS SG_ 422 DTPWCPS_CrnkPrm 62;
BA_REL_ "GenSigTimeoutMsg" BU_SG_REL_ ECM_HS SG_ 422 DTPWCPS_CrnkPrm 422;
BA_REL_ "GenSigSuprvResp" BU_SG_REL_ ECM_HS SG_ 422 DTPWCPS_CrnkPrm 1;
BA_REL_ "GenSigTimeoutTime" BU_SG_REL_ ECM_HS SG_ 422 TrnsAuxPrsDisOvrrdOn 62;
BA_REL_ "GenSigTimeoutMsg" BU_SG_REL_ ECM_HS SG_ 422 TrnsAuxPrsDisOvrrdOn 422;
BA_REL_ "GenSigSuprvResp" BU_SG_REL_ ECM_HS SG_ 422 TrnsAuxPrsDisOvrrdOn 1;
BA_REL_ "GenSigTimeoutTime" BU_SG_REL_ ECM_HS SG_ 422 TransEngShtdwnRqd 62;
BA_REL_ "GenSigTimeoutMsg" BU_SG_REL_ ECM_HS SG_ 422 TransEngShtdwnRqd 422;
BA_REL_ "GenSigSuprvResp" BU_SG_REL_ ECM_HS SG_ 422 TransEngShtdwnRqd 1;
BA_REL_ "GenSigTimeoutTime" BU_SG_REL_ ECM_HS SG_ 422 TransCrksftTqLoad 62;
BA_REL_ "GenSigTimeoutMsg" BU_SG_REL_ ECM_HS SG_ 422 TransCrksftTqLoad 422;
BA_REL_ "GenSigSuprvResp" BU_SG_REL_ ECM_HS SG_ 422 TransCrksftTqLoad 1;
BA_REL_ "GenSigTimeoutTime" BU_SG_REL_ ECM_HS SG_ 422 TrStPTGrdBrkDsMdOvr 62;
BA_REL_ "GenSigTimeoutMsg" BU_SG_REL_ ECM_HS SG_ 422 TrStPTGrdBrkDsMdOvr 422;
BA_REL_ "GenSigSuprvResp" BU_SG_REL_ ECM_HS SG_ 422 TrStPTGrdBrkDsMdOvr 1;
BA_REL_ "GenSigTimeoutTime" BU_SG_REL_ ECM_HS SG_ 422 TrnsHybEngSrtStpOvrd 62;
BA_REL_ "GenSigTimeoutMsg" BU_SG_REL_ ECM_HS SG_ 422 TrnsHybEngSrtStpOvrd 422;
BA_REL_ "GenSigSuprvResp" BU_SG_REL_ ECM_HS SG_ 422 TrnsHybEngSrtStpOvrd 1;
BA_REL_ "GenSigTimeoutTime" BU_SG_REL_ ECM_HS SG_ 1189 TransAirFlwPrcntRq 1250;
BA_REL_ "GenSigTimeoutMsg" BU_SG_REL_ ECM_HS SG_ 1189 TransAirFlwPrcntRq 1189;
BA_REL_ "GenSigSuprvResp" BU_SG_REL_ ECM_HS SG_ 1189 TransAirFlwPrcntRq 1;
BA_REL_ "GenSigTimeoutTime" BU_SG_REL_ ECM_HS SG_ 393 TIDCTR_TrqIntvTyp 250;
BA_REL_ "GenSigTimeoutMsg" BU_SG_REL_ ECM_HS SG_ 393 TIDCTR_TrqIntvTyp 393;
BA_REL_ "GenSigSuprvResp" BU_SG_REL_ ECM_HS SG_ 393 TIDCTR_TrqIntvTyp 1;
BA_REL_ "GenSigTimeoutTime" BU_SG_REL_ ECM_HS SG_ 393 TIDCTR_TrqReqVal 250;
BA_REL_ "GenSigTimeoutMsg" BU_SG_REL_ ECM_HS SG_ 393 TIDCTR_TrqReqVal 393;
BA_REL_ "GenSigSuprvResp" BU_SG_REL_ ECM_HS SG_ 393 TIDCTR_TrqReqVal 1;
BA_REL_ "GenSigTimeoutTime" BU_SG_REL_ ECM_HS SG_ 393 TIDCTR_TrqRespTyp 250;
BA_REL_ "GenSigTimeoutMsg" BU_SG_REL_ ECM_HS SG_ 393 TIDCTR_TrqRespTyp 393;
BA_REL_ "GenSigSuprvResp" BU_SG_REL_ ECM_HS SG_ 393 TIDCTR_TrqRespTyp 1;
BA_REL_ "GenSigTimeoutTime" BU_SG_REL_ ECM_HS SG_ 719 RrVrtlBmpAxlTrqCmdRC 250;
BA_REL_ "GenSigSuprvResp" BU_SG_REL_ ECM_HS SG_ 719 RrVrtlBmpAxlTrqCmdRC 1;
BA_REL_ "GenSigTimeoutTime" BU_SG_REL_ ECM_HS SG_ 719 RrVrtlBmpAxlTrqCmdProtVal 250;
BA_REL_ "GenSigSuprvResp" BU_SG_REL_ ECM_HS SG_ 719 RrVrtlBmpAxlTrqCmdProtVal 1;
BA_REL_ "GenSigTimeoutTime" BU_SG_REL_ ECM_HS SG_ 719 RVBATC_AxlTrqRqstAct 250;
BA_REL_ "GenSigSuprvResp" BU_SG_REL_ ECM_HS SG_ 719 RVBATC_AxlTrqRqstAct 1;
BA_REL_ "GenSigTimeoutTime" BU_SG_REL_ ECM_HS SG_ 719 RVBATC_AxlTrqRqst 250;
BA_REL_ "GenSigSuprvResp" BU_SG_REL_ ECM_HS SG_ 719 RVBATC_AxlTrqRqst 1;
BA_REL_ "GenSigTimeoutTime" BU_SG_REL_ ECM_HS SG_ 717 ColPrSysAxlTrqCmdProtVal 250;
BA_REL_ "GenSigSuprvResp" BU_SG_REL_ ECM_HS SG_ 717 ColPrSysAxlTrqCmdProtVal 1;
BA_REL_ "GenSigTimeoutTime" BU_SG_REL_ TCM_HS SG_ 717 CPSATC_AxlTrqRqstAct 250;
BA_REL_ "GenSigTimeoutMsg" BU_SG_REL_ TCM_HS SG_ 717 CPSATC_AxlTrqRqstAct 717;
BA_REL_ "GenSigSuprvResp" BU_SG_REL_ TCM_HS SG_ 717 CPSATC_AxlTrqRqstAct 1;
BA_REL_ "GenSigTimeoutTime" BU_SG_REL_ ECM_HS SG_ 717 CPSATC_AxlTrqRqstAct 250;
BA_REL_ "GenSigSuprvResp" BU_SG_REL_ ECM_HS SG_ 717 CPSATC_AxlTrqRqstAct 1;
BA_REL_ "GenSigTimeoutTime" BU_SG_REL_ TCM_HS SG_ 717 CPSATC_AxlTrqRqst 250;
BA_REL_ "GenSigTimeoutMsg" BU_SG_REL_ TCM_HS SG_ 717 CPSATC_AxlTrqRqst 717;
BA_REL_ "GenSigSuprvResp" BU_SG_REL_ TCM_HS SG_ 717 CPSATC_AxlTrqRqst 1;
BA_REL_ "GenSigTimeoutTime" BU_SG_REL_ ECM_HS SG_ 717 CPSATC_AxlTrqRqst 250;
BA_REL_ "GenSigSuprvResp" BU_SG_REL_ ECM_HS SG_ 717 CPSATC_AxlTrqRqst 1;
BA_REL_ "GenSigTimeoutTime" BU_SG_REL_ ECM_HS SG_ 717 ColPrSysAxlTrqCmdRC 250;
BA_REL_ "GenSigSuprvResp" BU_SG_REL_ ECM_HS SG_ 717 ColPrSysAxlTrqCmdRC 1;
BA_REL_ "GenSigRxStartValue" BU_SG_REL_ ECM_HS SG_ 1005 EnhSvVehTopSpdLmR "$0 - No Action";
BA_REL_ "GenSigTimeoutTime" BU_SG_REL_ ECM_HS SG_ 431 TransVehTopSpdLim 250;
BA_REL_ "GenSigTimeoutMsg" BU_SG_REL_ ECM_HS SG_ 431 TransVehTopSpdLim 431;
BA_REL_ "GenSigSuprvResp" BU_SG_REL_ ECM_HS SG_ 431 TransVehTopSpdLim 1;
BA_REL_ "GenSigTimeoutTime" BU_SG_REL_ ECM_HS SG_ 431 TransMinVoltReq 250;
BA_REL_ "GenSigTimeoutMsg" BU_SG_REL_ ECM_HS SG_ 431 TransMinVoltReq 431;
BA_REL_ "GenSigSuprvResp" BU_SG_REL_ ECM_HS SG_ 431 TransMinVoltReq 1;
BA_REL_ "GenSigTimeoutTime" BU_SG_REL_ ECM_HS SG_ 431 TDslPrtFltrIdlRgtnMdAtv 250;
BA_REL_ "GenSigTimeoutMsg" BU_SG_REL_ ECM_HS SG_ 431 TDslPrtFltrIdlRgtnMdAtv 431;
BA_REL_ "GenSigSuprvResp" BU_SG_REL_ ECM_HS SG_ 431 TDslPrtFltrIdlRgtnMdAtv 1;
BA_REL_ "GenSigTimeoutTime" BU_SG_REL_ ECM_HS SG_ 431 DrvlneTrqStabStat 250;
BA_REL_ "GenSigTimeoutMsg" BU_SG_REL_ ECM_HS SG_ 431 DrvlneTrqStabStat 431;
BA_REL_ "GenSigSuprvResp" BU_SG_REL_ ECM_HS SG_ 431 DrvlneTrqStabStat 1;
BA_REL_ "GenSigTimeoutTime" BU_SG_REL_ ECM_HS SG_ 431 TrnsTrqCnvCltDsrSlp 250;
BA_REL_ "GenSigTimeoutMsg" BU_SG_REL_ ECM_HS SG_ 431 TrnsTrqCnvCltDsrSlp 431;
BA_REL_ "GenSigSuprvResp" BU_SG_REL_ ECM_HS SG_ 431 TrnsTrqCnvCltDsrSlp 1;
BA_REL_ "GenSigTimeoutTime" BU_SG_REL_ ECM_HS SG_ 431 TrnsStWntrMdOvrd 250;
BA_REL_ "GenSigTimeoutMsg" BU_SG_REL_ ECM_HS SG_ 431 TrnsStWntrMdOvrd 431;
BA_REL_ "GenSigSuprvResp" BU_SG_REL_ ECM_HS SG_ 431 TrnsStWntrMdOvrd 1;
BA_REL_ "GenSigTimeoutTime" BU_SG_REL_ ECM_HS SG_ 431 TrnsStTwHaulMdOvrd 250;
BA_REL_ "GenSigTimeoutMsg" BU_SG_REL_ ECM_HS SG_ 431 TrnsStTwHaulMdOvrd 431;
BA_REL_ "GenSigSuprvResp" BU_SG_REL_ ECM_HS SG_ 431 TrnsStTwHaulMdOvrd 1;
BA_REL_ "GenSigTimeoutTime" BU_SG_REL_ ECM_HS SG_ 431 TrnsStSprtMdOvrd 250;
BA_REL_ "GenSigTimeoutMsg" BU_SG_REL_ ECM_HS SG_ 431 TrnsStSprtMdOvrd 431;
BA_REL_ "GenSigSuprvResp" BU_SG_REL_ ECM_HS SG_ 431 TrnsStSprtMdOvrd 1;
BA_REL_ "GenSigTimeoutTime" BU_SG_REL_ ECM_HS SG_ 431 TrnsStEconMdOvrd 250;
BA_REL_ "GenSigTimeoutMsg" BU_SG_REL_ ECM_HS SG_ 431 TrnsStEconMdOvrd 431;
BA_REL_ "GenSigSuprvResp" BU_SG_REL_ ECM_HS SG_ 431 TrnsStEconMdOvrd 1;
BA_REL_ "GenSigTimeoutTime" BU_SG_REL_ ECM_HS SG_ 409 TTRLT_TorqReqVal 31;
BA_REL_ "GenSigTimeoutMsg" BU_SG_REL_ ECM_HS SG_ 409 TTRLT_TorqReqVal 409;
BA_REL_ "GenSigSuprvResp" BU_SG_REL_ ECM_HS SG_ 409 TTRLT_TorqReqVal 1;
BA_REL_ "GenSigTimeoutTime" BU_SG_REL_ ECM_HS SG_ 409 TTRLT_TqRdnRlznSgg 31;
BA_REL_ "GenSigTimeoutMsg" BU_SG_REL_ ECM_HS SG_ 409 TTRLT_TqRdnRlznSgg 409;
BA_REL_ "GenSigSuprvResp" BU_SG_REL_ ECM_HS SG_ 409 TTRLT_TqRdnRlznSgg 1;
BA_REL_ "GenSigTimeoutTime" BU_SG_REL_ ECM_HS SG_ 409 TTRLT_TorqInvntnTyp 31;
BA_REL_ "GenSigTimeoutMsg" BU_SG_REL_ ECM_HS SG_ 409 TTRLT_TorqInvntnTyp 409;
BA_REL_ "GenSigSuprvResp" BU_SG_REL_ ECM_HS SG_ 409 TTRLT_TorqInvntnTyp 1;
BA_REL_ "GenSigTimeoutTime" BU_SG_REL_ ECM_HS SG_ 409 TTRST_TorqReqVal 31;
BA_REL_ "GenSigTimeoutMsg" BU_SG_REL_ ECM_HS SG_ 409 TTRST_TorqReqVal 409;
BA_REL_ "GenSigSuprvResp" BU_SG_REL_ ECM_HS SG_ 409 TTRST_TorqReqVal 1;
BA_REL_ "GenSigTimeoutTime" BU_SG_REL_ ECM_HS SG_ 409 TTRST_TorqInvntnTyp 31;
BA_REL_ "GenSigTimeoutMsg" BU_SG_REL_ ECM_HS SG_ 409 TTRST_TorqInvntnTyp 409;
BA_REL_ "GenSigSuprvResp" BU_SG_REL_ ECM_HS SG_ 409 TTRST_TorqInvntnTyp 1;
BA_REL_ "GenSigTimeoutTime" BU_SG_REL_ BSM_HS SG_ 558 CDP_HVDevShtdnCdARCSt 500;
BA_REL_ "GenSigTimeoutMsg" BU_SG_REL_ BSM_HS SG_ 558 CDP_HVDevShtdnCdARCSt 558;
BA_REL_ "GenSigSuprvResp" BU_SG_REL_ BSM_HS SG_ 558 CDP_HVDevShtdnCdARCSt 1;
BA_REL_ "GenSigTimeoutTime" BU_SG_REL_ BSM_HS SG_ 558 CDP_CmpSpdReqARCSt 500;
BA_REL_ "GenSigTimeoutMsg" BU_SG_REL_ BSM_HS SG_ 558 CDP_CmpSpdReqARCSt 558;
BA_REL_ "GenSigSuprvResp" BU_SG_REL_ BSM_HS SG_ 558 CDP_CmpSpdReqARCSt 1;
BA_REL_ "GenSigTimeoutTime" BU_SG_REL_ BSM_HS SG_ 558 CDP_CmpLossCommOcc 500;
BA_REL_ "GenSigTimeoutMsg" BU_SG_REL_ BSM_HS SG_ 558 CDP_CmpLossCommOcc 558;
BA_REL_ "GenSigSuprvResp" BU_SG_REL_ BSM_HS SG_ 558 CDP_CmpLossCommOcc 1;
BA_REL_ "GenSigTimeoutTime" BU_SG_REL_ BSM_HS SG_ 558 CDP_CmpWkUp 500;
BA_REL_ "GenSigTimeoutMsg" BU_SG_REL_ BSM_HS SG_ 558 CDP_CmpWkUp 558;
BA_REL_ "GenSigSuprvResp" BU_SG_REL_ BSM_HS SG_ 558 CDP_CmpWkUp 1;
BA_REL_ "GenSigTimeoutTime" BU_SG_REL_ BSM_HS SG_ 558 CDP_CmpRunCrnk 500;
BA_REL_ "GenSigTimeoutMsg" BU_SG_REL_ BSM_HS SG_ 558 CDP_CmpRunCrnk 558;
BA_REL_ "GenSigSuprvResp" BU_SG_REL_ BSM_HS SG_ 558 CDP_CmpRunCrnk 1;
BA_REL_ "GenSigTimeoutTime" BU_SG_REL_ BSM_HS SG_ 558 CDSP_CmpOvrTmpSt 500;
BA_REL_ "GenSigTimeoutMsg" BU_SG_REL_ BSM_HS SG_ 558 CDSP_CmpOvrTmpSt 558;
BA_REL_ "GenSigSuprvResp" BU_SG_REL_ BSM_HS SG_ 558 CDSP_CmpOvrTmpSt 1;
BA_REL_ "GenSigTimeoutTime" BU_SG_REL_ BSM_HS SG_ 558 CDSP_CmpHVAbnrlOrVltSt 500;
BA_REL_ "GenSigTimeoutMsg" BU_SG_REL_ BSM_HS SG_ 558 CDSP_CmpHVAbnrlOrVltSt 558;
BA_REL_ "GenSigSuprvResp" BU_SG_REL_ BSM_HS SG_ 558 CDSP_CmpHVAbnrlOrVltSt 1;
BA_REL_ "GenSigTimeoutTime" BU_SG_REL_ BSM_HS SG_ 558 CDSP_CmpHVUndrVltgSt 500;
BA_REL_ "GenSigTimeoutMsg" BU_SG_REL_ BSM_HS SG_ 558 CDSP_CmpHVUndrVltgSt 558;
BA_REL_ "GenSigSuprvResp" BU_SG_REL_ BSM_HS SG_ 558 CDSP_CmpHVUndrVltgSt 1;
BA_REL_ "GenSigTimeoutTime" BU_SG_REL_ BSM_HS SG_ 558 CDSP_CmpHVOvrVltgSt 500;
BA_REL_ "GenSigTimeoutMsg" BU_SG_REL_ BSM_HS SG_ 558 CDSP_CmpHVOvrVltgSt 558;
BA_REL_ "GenSigSuprvResp" BU_SG_REL_ BSM_HS SG_ 558 CDSP_CmpHVOvrVltgSt 1;
BA_REL_ "GenSigTimeoutTime" BU_SG_REL_ BSM_HS SG_ 558 CDSP_CmpHVOvrCrntSt 500;
BA_REL_ "GenSigTimeoutMsg" BU_SG_REL_ BSM_HS SG_ 558 CDSP_CmpHVOvrCrntSt 558;
BA_REL_ "GenSigSuprvResp" BU_SG_REL_ BSM_HS SG_ 558 CDSP_CmpHVOvrCrntSt 1;
BA_REL_ "GenSigTimeoutTime" BU_SG_REL_ BSM_HS SG_ 558 CDSP_OvrTempWrnInd 500;
BA_REL_ "GenSigTimeoutMsg" BU_SG_REL_ BSM_HS SG_ 558 CDSP_OvrTempWrnInd 558;
BA_REL_ "GenSigSuprvResp" BU_SG_REL_ BSM_HS SG_ 558 CDSP_OvrTempWrnInd 1;
BA_REL_ "GenSigTimeoutTime" BU_SG_REL_ BSM_HS SG_ 558 CDSP_CmpDgrdOp 500;
BA_REL_ "GenSigTimeoutMsg" BU_SG_REL_ BSM_HS SG_ 558 CDSP_CmpDgrdOp 558;
BA_REL_ "GenSigSuprvResp" BU_SG_REL_ BSM_HS SG_ 558 CDSP_CmpDgrdOp 1;
BA_REL_ "GenSigTimeoutTime" BU_SG_REL_ BSM_HS SG_ 558 CDSP_CmpIntShdwnFltSt 500;
BA_REL_ "GenSigTimeoutMsg" BU_SG_REL_ BSM_HS SG_ 558 CDSP_CmpIntShdwnFltSt 558;
BA_REL_ "GenSigSuprvResp" BU_SG_REL_ BSM_HS SG_ 558 CDSP_CmpIntShdwnFltSt 1;
BA_REL_ "GenSigTimeoutTime" BU_SG_REL_ BSM_HS SG_ 558 CDSP_CmpIntRecblFltSt 500;
BA_REL_ "GenSigTimeoutMsg" BU_SG_REL_ BSM_HS SG_ 558 CDSP_CmpIntRecblFltSt 558;
BA_REL_ "GenSigSuprvResp" BU_SG_REL_ BSM_HS SG_ 558 CDSP_CmpIntRecblFltSt 1;
BA_REL_ "GenSigTimeoutTime" BU_SG_REL_ BSM_HS SG_ 558 CDSP_CmpOpOvrldSt 500;
BA_REL_ "GenSigTimeoutMsg" BU_SG_REL_ BSM_HS SG_ 558 CDSP_CmpOpOvrldSt 558;
BA_REL_ "GenSigSuprvResp" BU_SG_REL_ BSM_HS SG_ 558 CDSP_CmpOpOvrldSt 1;
BA_REL_ "GenSigTimeoutTime" BU_SG_REL_ BSM_HS SG_ 558 CDSP_CmpDrCrctFltSt 500;
BA_REL_ "GenSigTimeoutMsg" BU_SG_REL_ BSM_HS SG_ 558 CDSP_CmpDrCrctFltSt 558;
BA_REL_ "GenSigSuprvResp" BU_SG_REL_ BSM_HS SG_ 558 CDSP_CmpDrCrctFltSt 1;
BA_REL_ "GenSigTimeoutTime" BU_SG_REL_ BSM_HS SG_ 558 CDSP_CmpMtrPerfFltSt 500;
BA_REL_ "GenSigTimeoutMsg" BU_SG_REL_ BSM_HS SG_ 558 CDSP_CmpMtrPerfFltSt 558;
BA_REL_ "GenSigSuprvResp" BU_SG_REL_ BSM_HS SG_ 558 CDSP_CmpMtrPerfFltSt 1;
BA_REL_ "GenSigTimeoutTime" BU_SG_REL_ BSM_HS SG_ 558 CDSP_CmpEEPROMFltSt 500;
BA_REL_ "GenSigTimeoutMsg" BU_SG_REL_ BSM_HS SG_ 558 CDSP_CmpEEPROMFltSt 558;
BA_REL_ "GenSigSuprvResp" BU_SG_REL_ BSM_HS SG_ 558 CDSP_CmpEEPROMFltSt 1;
BA_REL_ "GenSigTimeoutTime" BU_SG_REL_ BSM_HS SG_ 558 CDSP_CmpROMFltSt 500;
BA_REL_ "GenSigTimeoutMsg" BU_SG_REL_ BSM_HS SG_ 558 CDSP_CmpROMFltSt 558;
BA_REL_ "GenSigSuprvResp" BU_SG_REL_ BSM_HS SG_ 558 CDSP_CmpROMFltSt 1;
BA_REL_ "GenSigTimeoutTime" BU_SG_REL_ BSM_HS SG_ 558 CDSP_CmpRAMFltSt 500;
BA_REL_ "GenSigTimeoutMsg" BU_SG_REL_ BSM_HS SG_ 558 CDSP_CmpRAMFltSt 558;
BA_REL_ "GenSigSuprvResp" BU_SG_REL_ BSM_HS SG_ 558 CDSP_CmpRAMFltSt 1;
BA_REL_ "GenSigTimeoutTime" BU_SG_REL_ BSM_HS SG_ 558 CSSP_CmpIGBTTpOtRgLSt 500;
BA_REL_ "GenSigTimeoutMsg" BU_SG_REL_ BSM_HS SG_ 558 CSSP_CmpIGBTTpOtRgLSt 558;
BA_REL_ "GenSigSuprvResp" BU_SG_REL_ BSM_HS SG_ 558 CSSP_CmpIGBTTpOtRgLSt 1;
BA_REL_ "GenSigTimeoutTime" BU_SG_REL_ BSM_HS SG_ 558 CSSP_CmpIGBTTpOtRgHSt 500;
BA_REL_ "GenSigTimeoutMsg" BU_SG_REL_ BSM_HS SG_ 558 CSSP_CmpIGBTTpOtRgHSt 558;
BA_REL_ "GenSigSuprvResp" BU_SG_REL_ BSM_HS SG_ 558 CSSP_CmpIGBTTpOtRgHSt 1;
BA_REL_ "GenSigTimeoutTime" BU_SG_REL_ BSM_HS SG_ 558 CSSP_CmpCPUTmpOtRgLSt 500;
BA_REL_ "GenSigTimeoutMsg" BU_SG_REL_ BSM_HS SG_ 558 CSSP_CmpCPUTmpOtRgLSt 558;
BA_REL_ "GenSigSuprvResp" BU_SG_REL_ BSM_HS SG_ 558 CSSP_CmpCPUTmpOtRgLSt 1;
BA_REL_ "GenSigTimeoutTime" BU_SG_REL_ BSM_HS SG_ 558 CSSP_CmpCPUTmpOtRgHSt 500;
BA_REL_ "GenSigTimeoutMsg" BU_SG_REL_ BSM_HS SG_ 558 CSSP_CmpCPUTmpOtRgHSt 558;
BA_REL_ "GenSigSuprvResp" BU_SG_REL_ BSM_HS SG_ 558 CSSP_CmpCPUTmpOtRgHSt 1;
BA_REL_ "GenSigTimeoutTime" BU_SG_REL_ BSM_HS SG_ 558 CSSP_CmpHVSnsOtRgLSt 500;
BA_REL_ "GenSigTimeoutMsg" BU_SG_REL_ BSM_HS SG_ 558 CSSP_CmpHVSnsOtRgLSt 558;
BA_REL_ "GenSigSuprvResp" BU_SG_REL_ BSM_HS SG_ 558 CSSP_CmpHVSnsOtRgLSt 1;
BA_REL_ "GenSigTimeoutTime" BU_SG_REL_ BSM_HS SG_ 558 CSSP_CmpHVSnsOtRgHSt 500;
BA_REL_ "GenSigTimeoutMsg" BU_SG_REL_ BSM_HS SG_ 558 CSSP_CmpHVSnsOtRgHSt 558;
BA_REL_ "GenSigSuprvResp" BU_SG_REL_ BSM_HS SG_ 558 CSSP_CmpHVSnsOtRgHSt 1;
BA_REL_ "GenSigTimeoutTime" BU_SG_REL_ BSM_HS SG_ 558 CSSP_CmpPhCrntOtRgLSt 500;
BA_REL_ "GenSigTimeoutMsg" BU_SG_REL_ BSM_HS SG_ 558 CSSP_CmpPhCrntOtRgLSt 558;
BA_REL_ "GenSigSuprvResp" BU_SG_REL_ BSM_HS SG_ 558 CSSP_CmpPhCrntOtRgLSt 1;
BA_REL_ "GenSigTimeoutTime" BU_SG_REL_ BSM_HS SG_ 558 CSSP_CmpPhCrntOtRgHSt 500;
BA_REL_ "GenSigTimeoutMsg" BU_SG_REL_ BSM_HS SG_ 558 CSSP_CmpPhCrntOtRgHSt 558;
BA_REL_ "GenSigSuprvResp" BU_SG_REL_ BSM_HS SG_ 558 CSSP_CmpPhCrntOtRgHSt 1;
BA_REL_ "GenSigTimeoutTime" BU_SG_REL_ TCM_HS SG_ 504 EngCylDsrdFirngFractn 250;
BA_REL_ "GenSigTimeoutMsg" BU_SG_REL_ TCM_HS SG_ 504 EngCylDsrdFirngFractn 504;
BA_REL_ "GenSigSuprvResp" BU_SG_REL_ TCM_HS SG_ 504 EngCylDsrdFirngFractn 1;
BA_REL_ "GenSigTimeoutTime" BU_SG_REL_ TCM_HS SG_ 504 EngCylCalcFirngFractn 250;
BA_REL_ "GenSigTimeoutMsg" BU_SG_REL_ TCM_HS SG_ 504 EngCylCalcFirngFractn 504;
BA_REL_ "GenSigSuprvResp" BU_SG_REL_ TCM_HS SG_ 504 EngCylCalcFirngFractn 1;
BA_REL_ "GenSigTimeoutTime" BU_SG_REL_ TCM_HS SG_ 426 EngStlSvrAct 250;
BA_REL_ "GenSigTimeoutMsg" BU_SG_REL_ TCM_HS SG_ 426 EngStlSvrAct 426;
BA_REL_ "GenSigSuprvResp" BU_SG_REL_ TCM_HS SG_ 426 EngStlSvrAct 1;
BA_REL_ "GenSigTimeoutTime" BU_SG_REL_ TCM_HS SG_ 426 AuxTransPrsCmndOn 250;
BA_REL_ "GenSigTimeoutMsg" BU_SG_REL_ TCM_HS SG_ 426 AuxTransPrsCmndOn 426;
BA_REL_ "GenSigSuprvResp" BU_SG_REL_ TCM_HS SG_ 426 AuxTransPrsCmndOn 1;
BA_REL_ "GenSigTimeoutTime" BU_SG_REL_ TCM_HS SG_ 426 EVTCS_CmdTrqCapMd 250;
BA_REL_ "GenSigTimeoutMsg" BU_SG_REL_ TCM_HS SG_ 426 EVTCS_CmdTrqCapMd 426;
BA_REL_ "GenSigSuprvResp" BU_SG_REL_ TCM_HS SG_ 426 EVTCS_CmdTrqCapMd 1;
BA_REL_ "GenSigTimeoutTime" BU_SG_REL_ TCM_HS SG_ 426 EVTCS_CrntTrqCapMd 250;
BA_REL_ "GenSigTimeoutMsg" BU_SG_REL_ TCM_HS SG_ 426 EVTCS_CrntTrqCapMd 426;
BA_REL_ "GenSigSuprvResp" BU_SG_REL_ TCM_HS SG_ 426 EVTCS_CrntTrqCapMd 1;
BA_REL_ "GenSigTimeoutTime" BU_SG_REL_ TCM_HS SG_ 426 EngPrdctStdyStTorq 250;
BA_REL_ "GenSigTimeoutMsg" BU_SG_REL_ TCM_HS SG_ 426 EngPrdctStdyStTorq 426;
BA_REL_ "GenSigSuprvResp" BU_SG_REL_ TCM_HS SG_ 426 EngPrdctStdyStTorq 1;
BA_REL_ "GenSigTimeoutTime" BU_SG_REL_ TCM_HS SG_ 426 CrnkShftTrqMinOffCap 250;
BA_REL_ "GenSigTimeoutMsg" BU_SG_REL_ TCM_HS SG_ 426 CrnkShftTrqMinOffCap 426;
BA_REL_ "GenSigSuprvResp" BU_SG_REL_ TCM_HS SG_ 426 CrnkShftTrqMinOffCap 1;
BA_REL_ "GenSigTimeoutTime" BU_SG_REL_ TCM_HS SG_ 426 CrksftTqMinRunImCap 250;
BA_REL_ "GenSigTimeoutMsg" BU_SG_REL_ TCM_HS SG_ 426 CrksftTqMinRunImCap 426;
BA_REL_ "GenSigSuprvResp" BU_SG_REL_ TCM_HS SG_ 426 CrksftTqMinRunImCap 1;
BA_REL_ "GenSigTimeoutTime" BU_SG_REL_ TCM_HS SG_ 442 CrksftTqMinImCap 250;
BA_REL_ "GenSigTimeoutMsg" BU_SG_REL_ TCM_HS SG_ 442 CrksftTqMinImCap 442;
BA_REL_ "GenSigSuprvResp" BU_SG_REL_ TCM_HS SG_ 442 CrksftTqMinImCap 1;
BA_REL_ "GenSigTimeoutTime" BU_SG_REL_ TCM_HS SG_ 1417 PrplsnTrqRelCap 1250;
BA_REL_ "GenSigTimeoutMsg" BU_SG_REL_ TCM_HS SG_ 1417 PrplsnTrqRelCap 1417;
BA_REL_ "GenSigSuprvResp" BU_SG_REL_ TCM_HS SG_ 1417 PrplsnTrqRelCap 1;
VAL_ 3221225472 ChgrSysAdblIndReq 0 "Inactive" 1 "Sequence 1" 2 "Sequence 2" 3 "Sequence 3" ;
VAL_ 3221225472 BattVltIRq 3 "Battery Voltage Very Low" 2 "Battery Voltage High" 1 "Battery Voltage Low" 0 "Battery Voltage OK" ;
VAL_ 292 TrlrStTwHlMdOvrd 3 "Unused and Reserved 2" 2 "Unused and Reserved 1" 1 "Override to Not Tow Haul" 0 "No Override" ;
VAL_ 292 AVMC_MdReqstd 31 "Critically Disabled" 30 "No Mode Change Requested" 29 "Unused and Reserved 16" 28 "Unused and Reserved 15" 27 "Unused and Reserved 14" 26 "Unused and Reserved 13" 25 "Unused and Reserved 12" 24 "Unused and Reserved 11" 23 "Unused and Reserved 10" 22 "Unused and Reserved 9" 21 "Unused and Reserved 8" 20 "Unused and Reserved 7" 19 "Unused and Reserved 6" 18 "Unused and Reserved 5" 17 "Unused and Reserved 4" 16 "Unused and Reserved 3" 15 "Unused and Reserved 2" 14 "Unused and Reserved 1" 13 "Normal AWD" 12 "Exhaust Brake" 11 "Track" 10 "Speed Matching" 9 "Grade Braking Disable" 8 "Tow Haul" 7 "Start Stop" 6 "Snow Ice" 5 "Hold" 4 "Mountain" 3 "Eco" 2 "Chassis Sport" 1 "Powertrain Sport" 0 "Normal" ;
VAL_ 292 AVMC_MdFtrEnbld 1 "true" 0 "false" ;
VAL_ 430 TCFS_Cltch5FltStat 0 "None" 1 "Failed Off Fault Active" 2 "Failed On Fault Active" 3 "Failed Off Fault Pending" 4 "Failed On Fault Pending" 5 "Mismatch" ;
VAL_ 430 TCFS_Cltch4FltStat 0 "None" 1 "Failed Off Fault Active" 2 "Failed On Fault Active" 3 "Failed Off Fault Pending" 4 "Failed On Fault Pending" 5 "Mismatch" ;
VAL_ 430 TCFS_Cltch3FltStat 0 "None" 1 "Failed Off Fault Active" 2 "Failed On Fault Active" 3 "Failed Off Fault Pending" 4 "Failed On Fault Pending" 5 "Mismatch" ;
VAL_ 430 TCFS_Cltch2FltStat 0 "None" 1 "Failed Off Fault Active" 2 "Failed On Fault Active" 3 "Failed Off Fault Pending" 4 "Failed On Fault Pending" 5 "Mismatch" ;
VAL_ 430 TCFS_Cltch1FltStat 0 "None" 1 "Failed Off Fault Active" 2 "Failed On Fault Active" 3 "Failed Off Fault Pending" 4 "Failed On Fault Pending" 5 "Mismatch" ;
VAL_ 430 TransClch5FlAch 1 "true" 0 "false" ;
VAL_ 430 TransClch4FlAch 1 "true" 0 "false" ;
VAL_ 430 TransClch3FlAch 1 "true" 0 "false" ;
VAL_ 430 TransClch2FlAch 1 "true" 0 "false" ;
VAL_ 430 TransClch1FlAch 1 "true" 0 "false" ;
VAL_ 429 TrnsPTSysShtdwnRq 1 "true" 0 "false" ;
VAL_ 429 TransHydrlcDfltgAct 1 "true" 0 "false" ;
VAL_ 399 ElcTrnsRngSelPrkSysStat 7 "Unused and Reserved 4" 6 "Unused and Reserved 3" 5 "Unused and Reserved 2" 4 "Unused and Reserved 1" 3 "Out Of Park" 2 "Transitional 1" 1 "Park" 0 "Unknown" ;
VAL_ 399 TPSDCF_TrnsPrkSysOOPrkDiaCrtFlt 1 "true" 0 "false" ;
VAL_ 399 TPSDCF_TrnsPrkSysPrkDiaCrtFlt 1 "true" 0 "false" ;
VAL_ 399 TPSDLF_TrnsPrkSysOOPrkDiaLmtdFlt 1 "true" 0 "false" ;
VAL_ 399 TPSDLF_TrnsPrkSysPrkDiaLmtdFlt 1 "true" 0 "false" ;
VAL_ 425 TransClch4FlAch 1 "true" 0 "false" ;
VAL_ 425 TransClch5FlAch 1 "true" 0 "false" ;
VAL_ 424 TransClch3FlAch 1 "true" 0 "false" ;
VAL_ 424 TransClch2FlAch 1 "true" 0 "false" ;
VAL_ 423 TrnsPTSysShtdwnRq 1 "true" 0 "false" ;
VAL_ 423 TransClch1FlAch 1 "true" 0 "false" ;
VAL_ 423 TransHydrlcDfltgAct 1 "true" 0 "false" ;
VAL_ 423 TCFS_Cltch5FltStat 0 "None" 1 "Failed Off Fault Active" 2 "Failed On Fault Active" 3 "Failed Off Fault Pending" 4 "Failed On Fault Pending" 5 "Mismatch" ;
VAL_ 423 TCFS_Cltch4FltStat 0 "None" 1 "Failed Off Fault Active" 2 "Failed On Fault Active" 3 "Failed Off Fault Pending" 4 "Failed On Fault Pending" 5 "Mismatch" ;
VAL_ 423 TCFS_Cltch3FltStat 0 "None" 1 "Failed Off Fault Active" 2 "Failed On Fault Active" 3 "Failed Off Fault Pending" 4 "Failed On Fault Pending" 5 "Mismatch" ;
VAL_ 423 TCFS_Cltch2FltStat 0 "None" 1 "Failed Off Fault Active" 2 "Failed On Fault Active" 3 "Failed Off Fault Pending" 4 "Failed On Fault Pending" 5 "Mismatch" ;
VAL_ 423 TCFS_Cltch1FltStat 0 "None" 1 "Failed Off Fault Active" 2 "Failed On Fault Active" 3 "Failed Off Fault Pending" 4 "Failed On Fault Pending" 5 "Mismatch" ;
VAL_ 423 TCAS_Cltch5AvlbltyStat 0 "Unavailable" 1 "Ready" 2 "Allowed" 3 "Unused and Reserved" ;
VAL_ 423 TCAS_Cltch4AvlbltyStat 0 "Unavailable" 1 "Ready" 2 "Allowed" 3 "Unused and Reserved" ;
VAL_ 423 TCAS_Cltch3AvlbltyStat 0 "Unavailable" 1 "Ready" 2 "Allowed" 3 "Unused and Reserved" ;
VAL_ 423 TCAS_Cltch2AvlbltyStat 0 "Unavailable" 1 "Ready" 2 "Allowed" 3 "Unused and Reserved" ;
VAL_ 423 TCAS_Cltch1AvlbltyStat 0 "Unavailable" 1 "Ready" 2 "Allowed" 3 "Unused and Reserved" ;
VAL_ 1919 DTCI_DTCFaultType_77F 3 "Type C" 2 "Type B" 1 "Type A" 0 "Not Supported" ;
VAL_ 1919 DTCI_CodeSupported_77F 1 "true" 0 "false" ;
VAL_ 1919 DTCI_CurrentStatus_77F 1 "true" 0 "false" ;
VAL_ 1919 DTCI_TstNPsdCdClrdSt_77F 1 "true" 0 "false" ;
VAL_ 1919 DTCI_TstFldCdClrdStat_77F 1 "true" 0 "false" ;
VAL_ 1919 DTCI_HistStat_77F 1 "true" 0 "false" ;
VAL_ 1919 DTCI_TstNPsdPwrUpSt_77F 1 "true" 0 "false" ;
VAL_ 1919 DTCI_TstFldPwrUpSt_77F 1 "true" 0 "false" ;
VAL_ 1919 DTCI_WrnIndRqdSt_77F 1 "true" 0 "false" ;
VAL_ 1919 DTCI_DTCTriggered_77F 1 "true" 0 "false" ;
VAL_ 1919 DTCIUnused7_77F 1 "true" 0 "false" ;
VAL_ 1919 DTCIUnused6_77F 1 "true" 0 "false" ;
VAL_ 1919 DTCIUnused5_77F 1 "true" 0 "false" ;
VAL_ 1919 DTCIUnused4_77F 1 "true" 0 "false" ;
VAL_ 1919 DTCIUnused3_77F 1 "true" 0 "false" ;
VAL_ 1919 DTCIUnused2_77F 1 "true" 0 "false" ;
VAL_ 1919 DTCIUnused1_77F 1 "true" 0 "false" ;
VAL_ 1914 DTCI_DTCFaultType_77A 3 "Type C" 2 "Type B" 1 "Type A" 0 "Not Supported" ;
VAL_ 1914 DTCI_CodeSupported_77A 1 "true" 0 "false" ;
VAL_ 1914 DTCI_CurrentStatus_77A 1 "true" 0 "false" ;
VAL_ 1914 DTCI_TstNPsdCdClrdSt_77A 1 "true" 0 "false" ;
VAL_ 1914 DTCI_TstFldCdClrdStat_77A 1 "true" 0 "false" ;
VAL_ 1914 DTCI_HistStat_77A 1 "true" 0 "false" ;
VAL_ 1914 DTCI_TstNPsdPwrUpSt_77A 1 "true" 0 "false" ;
VAL_ 1914 DTCI_TstFldPwrUpSt_77A 1 "true" 0 "false" ;
VAL_ 1914 DTCI_WrnIndRqdSt_77A 1 "true" 0 "false" ;
VAL_ 1914 DTCI_DTCTriggered_77A 1 "true" 0 "false" ;
VAL_ 1914 DTCIUnused7_77A 1 "true" 0 "false" ;
VAL_ 1914 DTCIUnused6_77A 1 "true" 0 "false" ;
VAL_ 1914 DTCIUnused5_77A 1 "true" 0 "false" ;
VAL_ 1914 DTCIUnused4_77A 1 "true" 0 "false" ;
VAL_ 1914 DTCIUnused3_77A 1 "true" 0 "false" ;
VAL_ 1914 DTCIUnused2_77A 1 "true" 0 "false" ;
VAL_ 1914 DTCIUnused1_77A 1 "true" 0 "false" ;
VAL_ 1912 DTCI_DTCFaultType_778 3 "Type C" 2 "Type B" 1 "Type A" 0 "Not Supported" ;
VAL_ 1912 DTCI_CodeSupported_778 1 "true" 0 "false" ;
VAL_ 1912 DTCI_CurrentStatus_778 1 "true" 0 "false" ;
VAL_ 1912 DTCI_TstNPsdCdClrdSt_778 1 "true" 0 "false" ;
VAL_ 1912 DTCI_TstFldCdClrdStat_778 1 "true" 0 "false" ;
VAL_ 1912 DTCI_HistStat_778 1 "true" 0 "false" ;
VAL_ 1912 DTCI_TstNPsdPwrUpSt_778 1 "true" 0 "false" ;
VAL_ 1912 DTCI_TstFldPwrUpSt_778 1 "true" 0 "false" ;
VAL_ 1912 DTCI_WrnIndRqdSt_778 1 "true" 0 "false" ;
VAL_ 1912 DTCI_DTCTriggered_778 1 "true" 0 "false" ;
VAL_ 1912 DTCIUnused7_778 1 "true" 0 "false" ;
VAL_ 1912 DTCIUnused6_778 1 "true" 0 "false" ;
VAL_ 1912 DTCIUnused5_778 1 "true" 0 "false" ;
VAL_ 1912 DTCIUnused4_778 1 "true" 0 "false" ;
VAL_ 1912 DTCIUnused3_778 0 "false" 1 "true" ;
VAL_ 1912 DTCIUnused2_778 1 "true" 0 "false" ;
VAL_ 1912 DTCIUnused1_778 1 "true" 0 "false" ;
VAL_ 388 HndsOffStrWhlDtStV 1 "Invalid" 0 "Valid" ;
VAL_ 388 HndsOffStrWhlDtSt 0 "Hands Off" 1 "Hands On" ;
VAL_ 388 HndsOffStrWhlDtMd 0 "Disabled" 1 "Enabled" 2 "Failed" ;
VAL_ 388 LKATrqOvrlTrqDStat 0 "Inactive" 1 "Active" 2 "Temporarily Limited" 3 "Permanently Failed" ;
VAL_ 388 LKADrvAppldTrqV 1 "Invalid" 0 "Valid" ;
VAL_ 546 ThrmlRefCompStatFdbck 3 "Invalid" 2 "Inoperative" 1 "Degraded Operation" 0 "Normal Operation" ;
VAL_ 390 HybCrpCstCrvRq 7 "Creep Coast Curve 7" 6 "Creep Coast Curve 6" 5 "Creep Coast Curve 5" 4 "Creep Coast Curve 4" 3 "Creep Coast Curve 3" 2 "Creep Coast Curve 2" 1 "Creep Coast Curve 1" 0 "Creep Coast Curve 0" ;
VAL_ 390 TransFldPmpMtrDrtd 1 "true" 0 "false" ;
VAL_ 390 RdHVInvRatVltV 1 "Invalid" 0 "Valid" ;
VAL_ 390 EngActDmpgDsblReq 1 "true" 0 "false" ;
VAL_ 390 HybRdcdTrqCapMd1Cmnd 1 "true" 0 "false" ;
VAL_ 390 HybExtndDcFuelCORq 1 "true" 0 "false" ;
VAL_ 390 EstMtrPwrLossV 1 "Invalid" 0 "Valid" ;
VAL_ 390 HybCmmFailRdPwrCmd 1 "true" 0 "false" ;
VAL_ 390 HybACCompRq 3 "Reserved" 2 "Disengage" 1 "Engage" 0 "No Action" ;
VAL_ 390 HybGrdBrkgAct 1 "true" 0 "false" ;
VAL_ 390 HESSI_EngStrtTyp 9 "Compression Test" 8 "Auto Start Generic" 7 "Auto Start Aggressive" 6 "Auto Start Normal" 5 "Auto Start Smooth" 4 "Key Start Generic" 3 "Key Start Low Power B" 2 "Key Start Low Power" 1 "Key Start Normal" 0 "No Start" ;
VAL_ 390 HESSI_EngStrtStpMd 7 "Start Failed" 6 "Stop Pending" 5 "Disable Fuel" 4 "Producing Torque" 3 "Enable Fuel" 2 "Start Pending" 1 "Immediate Stop" 0 "Stop" ;
VAL_ 390 HybCrnkAbrtd 1 "true" 0 "false" ;
VAL_ 390 CnvntlEngStrtEnbld 1 "true" 0 "false" ;
VAL_ 390 HybDFCOReq 1 "DFCO Requested" 0 "DFCO Not Requested" ;
VAL_ 390 RdPTHVCntrReq 0 "Undetermined" 1 "Close Allowed" 2 "Request Open" ;
VAL_ 418 STGRI_TransGrRatSt 5 "Invalid" 4 "Alternate Sensors in Use" 3 "Torque Phase Ratio Active" 2 "Theoretical" 1 "Normal" 0 "Inactive" ;
VAL_ 418 STEGI_SecTransEstGear 15 "Park Gear" 14 "Reverse Gear" 13 "Neutral Gear" 12 "CVT Forward Gear" 11 "Unused and Reserved" 10 "Tenth Gear" 9 "Ninth Gear" 8 "Eighth Gear" 7 "Seventh Gear" 6 "Sixth Gear" 5 "Fifth Gear" 4 "Fourth Gear" 3 "Third Gear" 2 "Second Gear" 1 "First Gear" 0 "Not Supported" ;
VAL_ 1236 CGMSDCII_DataIndx 19 "CVN Digit 4" 18 "CVN Digit 3" 17 "CVN Digit 2" 16 "CVN Digit 1" 15 "Calibration Identification Digit 16" 14 "Calibration Identification Digit 15" 13 "Calibration Identification Digit 14" 12 "Calibration Identification Digit 13" 11 "Calibration Identification Digit 12" 10 "Calibration Identification Digit 11" 9 "Calibration Identification Digit 10" 8 "Calibration Identification Digit 9" 7 "Calibration Identification Digit 8" 6 "Calibration Identification Digit 7" 5 "Calibration Identification Digit 6" 4 "Calibration Identification Digit 5" 3 "Calibration Identification Digit 4" 2 "Calibration Identification Digit 3" 1 "Calibration Identification Digit 2" 0 "Calibration Identification Digit 1" ;
VAL_ 1236 CGMSDCII_DataStat 1 "Data Available" 0 "Data Not Available" ;
VAL_ 1236 CGMRCII_DataIndx 19 "CVN Digit 4" 18 "CVN Digit 3" 17 "CVN Digit 2" 16 "CVN Digit 1" 15 "Calibration Identification Digit 16" 14 "Calibration Identification Digit 15" 13 "Calibration Identification Digit 14" 12 "Calibration Identification Digit 13" 11 "Calibration Identification Digit 12" 10 "Calibration Identification Digit 11" 9 "Calibration Identification Digit 10" 8 "Calibration Identification Digit 9" 7 "Calibration Identification Digit 8" 6 "Calibration Identification Digit 7" 5 "Calibration Identification Digit 6" 4 "Calibration Identification Digit 5" 3 "Calibration Identification Digit 4" 2 "Calibration Identification Digit 3" 1 "Calibration Identification Digit 2" 0 "Calibration Identification Digit 1" ;
VAL_ 1236 CGMRCII_DataStat 1 "Data Available" 0 "Data Not Available" ;
VAL_ 1236 CGMOCII_DataIndx 19 "CVN Digit 4" 18 "CVN Digit 3" 17 "CVN Digit 2" 16 "CVN Digit 1" 15 "Calibration Identification Digit 16" 14 "Calibration Identification Digit 15" 13 "Calibration Identification Digit 14" 12 "Calibration Identification Digit 13" 11 "Calibration Identification Digit 12" 10 "Calibration Identification Digit 11" 9 "Calibration Identification Digit 10" 8 "Calibration Identification Digit 9" 7 "Calibration Identification Digit 8" 6 "Calibration Identification Digit 7" 5 "Calibration Identification Digit 6" 4 "Calibration Identification Digit 5" 3 "Calibration Identification Digit 4" 2 "Calibration Identification Digit 3" 1 "Calibration Identification Digit 2" 0 "Calibration Identification Digit 1" ;
VAL_ 1236 CGMOCII_DataStat 1 "Data Available" 0 "Data Not Available" ;
VAL_ 1236 CGMSII_DataIndx 19 "CVN Digit 4" 18 "CVN Digit 3" 17 "CVN Digit 2" 16 "CVN Digit 1" 15 "Calibration Identification Digit 16" 14 "Calibration Identification Digit 15" 13 "Calibration Identification Digit 14" 12 "Calibration Identification Digit 13" 11 "Calibration Identification Digit 12" 10 "Calibration Identification Digit 11" 9 "Calibration Identification Digit 10" 8 "Calibration Identification Digit 9" 7 "Calibration Identification Digit 8" 6 "Calibration Identification Digit 7" 5 "Calibration Identification Digit 6" 4 "Calibration Identification Digit 5" 3 "Calibration Identification Digit 4" 2 "Calibration Identification Digit 3" 1 "Calibration Identification Digit 2" 0 "Calibration Identification Digit 1" ;
VAL_ 1236 CGMSII_DataStat 1 "Data Available" 0 "Data Not Available" ;
VAL_ 1195 TransTempOpRgn 7 "Unused and Reserved 3" 6 "Unused and Reserved 2" 5 "Unused and Reserved 1" 4 "Reliability Degraded" 3 "Operation Degraded" 2 "High Efficiency" 1 "Low Efficiency" 0 "Unknown" ;
VAL_ 1195 TransOilTempAltValV 1 "Invalid" 0 "Valid" ;
VAL_ 1195 TransOilTempAltValM 1 "Use Data" 0 "Dont Use Data" ;
VAL_ 612 PPSTmdayV 1 "Invalid" 0 "Valid" ;
VAL_ 612 PPSCldrYrV 1 "Invalid" 0 "Valid" ;
VAL_ 612 PPSCldrDayV 1 "Invalid" 0 "Valid" ;
VAL_ 189 TransOilPmpOfRqd 1 "true" 0 "false" ;
VAL_ 189 TrnsInpMinSpdRq 0 "Unused and Reserved" 1 "Speed Point 1" 2 "Speed Point 2" 3 "Speed Point 3" 4 "Speed Point 4" 5 "Speed Point 5" 6 "Speed Point 6" 7 "Speed Point 7" 8 "Speed Point 8" 9 "Speed Point 9" 10 "Speed Point 10" 11 "Speed Point 11" 12 "Speed Point 12" 13 "Speed Point 13" 14 "Speed Point 14" 15 "Speed Point 15" ;
VAL_ 189 HybDisengCruzCmnd 1 "true" 0 "false" ;
VAL_ 189 TrnsRtoCntlSysFlt 1 "true" 0 "false" ;
VAL_ 422 TrnsStatTrkMdOvrd 2 "Override To Track" 1 "Override To Not Track" 0 "No Override" ;
VAL_ 422 DTPWCPS_CrnkPrmV 1 "Invalid" 0 "Valid" ;
VAL_ 422 DTPWCPS_CrnkPrm 1 "Crank Permitted" 0 "Crank Not Permitted" ;
VAL_ 422 TrnsAuxPrsDisOvrrdOn 1 "true" 0 "false" ;
VAL_ 422 TransEngShtdwnRqd 1 "true" 0 "false" ;
VAL_ 422 TransCrksftTqLoadV 1 "Invalid" 0 "Valid" ;
VAL_ 422 TrStPTGrdBrkDsMdOvr 3 "Unused and Reserved" 2 "To Grade Braking Disable" 1 "To Not Grade Braking Disable" 0 "No Override" ;
VAL_ 422 TrnsHybEngSrtStpOvrd 2 "Engine Off" 1 "Engine On" 0 "No Override" ;
VAL_ 393 TIDCTR_TrqIntvTyp 3 "Reserved" 2 "Minimum Limit" 1 "Maximum Limit" 0 "No Request" ;
VAL_ 393 TIDCTR_TrqRespTyp 3 "Automatic Actuator Selection" 2 "Maximum Range" 1 "Pleasability Limited" 0 "Inactive" ;
VAL_ 393 TPCTR_TrqIntrvnTyp 3 "Unused and Reserved" 2 "Minimum Limit" 1 "Maximum Limit" 0 "No Request" ;
VAL_ 719 RVBATC_AxlTrqRqstAct 1 "true" 0 "false" ;
VAL_ 717 CPSATC_AxlTrqRqstAct 1 "true" 0 "false" ;
VAL_ 1005 EnhSvVehTopSpdLmR 2 "Inactive" 1 "Active" 0 "No Action" ;
VAL_ 431 TrnsInpCltchStatV 1 "Invalid" 0 "Valid" ;
VAL_ 431 TransCrnkPermsnStatV 1 "Invalid" 0 "Valid" ;
VAL_ 431 TDslPrtFltrIdlRgtnMdAtv 1 "true" 0 "false" ;
VAL_ 431 DrvlneTrqStabStat 3 "Level 3" 0 "Normal Stability" 1 "Level 1" 2 "Level 2" ;
VAL_ 431 TrnsTrqCnvCltCmdMdF 1 "true" 0 "false" ;
VAL_ 431 AutoTransGrSftDirectFl 1 "true" 0 "false" ;
VAL_ 431 AutoTransGrSftDirect 2 "Downshift in Progress" 1 "Upshift in Progress" 0 "No Shift in Progress" ;
VAL_ 431 TrnsTrqCnvCltCmndMd 7 "Not Supported" 3 "Locked" 2 "Controlled Slip" 1 "Transitioning" 0 "Unlocked" ;
VAL_ 431 TrnsStWntrMdOvrd 2 "Override To Winter" 1 "Override To Not Winter" 0 "No Override" ;
VAL_ 431 TrnsStTwHaulMdOvrd 2 "Override To Tow Haul" 1 "Override To Not Tow Haul" 0 "No Override" ;
VAL_ 431 TrnsStSprtMdOvrd 2 "Override To Sport" 1 "Override To Not Sport" 0 "No Override" ;
VAL_ 431 TrnsStEconMdOvrd 2 "Override To Economy" 1 "Override To Not Economy" 0 "No Override" ;
VAL_ 431 TrnsInpCltchStat 0 "Disengaged" 1 "Engaging" 2 "Engaged" 3 "Disengaging" 4 "Controlled Slip" 5 "Reserved" 6 "Reserved" 7 "Not Supported" ;
VAL_ 431 TrnsAntcptdCrpTrqRRnV 1 "Invalid" 0 "Valid" ;
VAL_ 431 TrnCltAdpAtv 1 "true" 0 "false" ;
VAL_ 431 TransCrnkPermsnStat 0 "Crank Not Permitted" 1 "Crank Permitted" ;
VAL_ 431 WrmUpShftPtrn 0 "Inactive" 1 "Active" ;
VAL_ 409 TDslPrtFltrIdlRgtnMdAtv 1 "true" 0 "false" ;
VAL_ 409 TTRLT_TqRdnRlznSgg 3 "Stability Optimized 2" 2 "Stability Optimized 1" 1 "Transient Optimized" 0 "No Suggestion" ;
VAL_ 409 TTRLT_TorqInvntnTyp 2 "Minimum Limit" 1 "Maximum Limit" 0 "No Intervention" ;
VAL_ 409 TTRST_TorqInvntnTyp 1 "Maximum Limit" 0 "No Intervention" ;
VAL_ 558 CDP_HVDevShtdnCdARCSt 2 "Indeterminate" 1 "Fault" 0 "No Fault" ;
VAL_ 558 CDP_CmpSpdReqARCSt 2 "Indeterminate" 1 "Fault" 0 "No Fault" ;
VAL_ 558 CDP_CmpLossCommOcc 1 "true" 0 "false" ;
VAL_ 558 CDP_CmpWkUp 1 "true" 0 "false" ;
VAL_ 558 CDP_CmpRunCrnk 1 "true" 0 "false" ;
VAL_ 558 CDSP_CmpOvrTmpSt 2 "Indeterminate" 1 "Fault" 0 "No Fault" ;
VAL_ 558 CDSP_CmpHVAbnrlOrVltSt 2 "Indeterminate" 1 "Fault" 0 "No Fault" ;
VAL_ 558 CDSP_CmpHVUndrVltgSt 2 "Indeterminate" 1 "Fault" 0 "No Fault" ;
VAL_ 558 CDSP_CmpHVOvrVltgSt 2 "Indeterminate" 1 "Fault" 0 "No Fault" ;
VAL_ 558 CDSP_CmpHVOvrCrntSt 2 "Indeterminate" 1 "Fault" 0 "No Fault" ;
VAL_ 558 CDSP_OvrTempWrnInd 1 "true" 0 "false" ;
VAL_ 558 CDSP_CmpDgrdOp 1 "true" 0 "false" ;
VAL_ 558 CDSP_CmpIntShdwnFltSt 2 "Indeterminate" 1 "Fault" 0 "No Fault" ;
VAL_ 558 CDSP_CmpIntRecblFltSt 2 "Indeterminate" 1 "Fault" 0 "No Fault" ;
VAL_ 558 CDSP_CmpOpOvrldSt 2 "Indeterminate" 1 "Fault" 0 "No Fault" ;
VAL_ 558 CDSP_CmpDrCrctFltSt 2 "Indeterminate" 1 "Fault" 0 "No Fault" ;
VAL_ 558 CDSP_CmpMtrPerfFltSt 2 "Indeterminate" 1 "Fault" 0 "No Fault" ;
VAL_ 558 CDSP_CmpEEPROMFltSt 2 "Indeterminate" 1 "Fault" 0 "No Fault" ;
VAL_ 558 CDSP_CmpROMFltSt 2 "Indeterminate" 1 "Fault" 0 "No Fault" ;
VAL_ 558 CDSP_CmpRAMFltSt 2 "Indeterminate" 1 "Fault" 0 "No Fault" ;
VAL_ 558 CSSP_CmpIGBTTpOtRgLSt 2 "Indeterminate" 1 "Fault" 0 "No Fault" ;
VAL_ 558 CSSP_CmpIGBTTpOtRgHSt 2 "Indeterminate" 1 "Fault" 0 "No Fault" ;
VAL_ 558 CSSP_CmpCPUTmpOtRgLSt 0 "No Fault" 2 "Indeterminate" 1 "Fault" ;
VAL_ 558 CSSP_CmpCPUTmpOtRgHSt 2 "Indeterminate" 1 "Fault" 0 "No Fault" ;
VAL_ 558 CSSP_CmpHVSnsOtRgLSt 2 "Indeterminate" 1 "Fault" 0 "No Fault" ;
VAL_ 558 CSSP_CmpHVSnsOtRgHSt 2 "Indeterminate" 1 "Fault" 0 "No Fault" ;
VAL_ 558 CSSP_CmpPhCrntOtRgLSt 2 "Indeterminate" 1 "Fault" 0 "No Fault" ;
VAL_ 558 CSSP_CmpPhCrntOtRgHSt 2 "Indeterminate" 1 "Fault" 0 "No Fault" ;
VAL_ 550 ACCMCII_DatStat 0 "Cal ID Index Not Used" 1 "Cal Verification Number Uncalculated" 2 "Cal Verification Number Calculated" ;
VAL_ 730 PAMS_DrvMdSwStck 1 "true" 0 "false" ;
VAL_ 730 PAMS_Sw4Stck 1 "true" 0 "false" ;
VAL_ 730 PAMS_Sw3Stck 1 "true" 0 "false" ;
VAL_ 730 PAMS_Sw2Stck 1 "true" 0 "false" ;
VAL_ 730 PAMS_Sw1Stck 1 "true" 0 "false" ;
VAL_ 730 PAMS_SwStat 7 "Critical Analog Fault" 6 "Unused and Reserved 2" 5 "Unused and Reserved 1" 4 "Switch 4 Active" 3 "Switch 3 Active" 2 "Switch 2 Active" 1 "Switch 1 Active" 0 "No Active Switches" ;
VAL_ 458 ACCAxlTrqReqStat 7 "Unused and Reserved 3" 6 "Unused and Reserved 2" 5 "Unused and Reserved 1" 4 "Request Suspended Until Driver Input" 3 "Request Denied" 2 "Lost Arbitration" 1 "Request Honored" 0 "No Request" ;
VAL_ 458 DRAT_TrqIncr 1 "true" 0 "false" ;
VAL_ 426 EngStlSvrAct 1 "true" 0 "false" ;
VAL_ 426 EngPstnSnsngOpMode 2 "CAM Failed" 1 "Crank Failed" 0 "Normal" ;
VAL_ 426 AuxTransPrsCmndOn 1 "true" 0 "false" ;
VAL_ 426 EVTCS_CmdTrqCapMd 0 "Full Torque Capacity" 1 "Reduced Capacity 1" 2 "Reserved 1" 3 "Reserved 2" 4 "Reserved 3" 5 "Reserved 4" 6 "Reserved 5" 7 "Reserved 6" ;
VAL_ 426 EVTCS_CrntTrqCapMd 0 "Full Torque Capacity" 1 "Reduced Capacity 1" 2 "Reserved 1" 3 "Reserved 2" 4 "Reserved 3" 5 "Reserved 4" 6 "Reserved 5" 7 "Reserved 6" ;
VAL_ 426 EngPrdctStdyStTorqV 1 "Invalid" 0 "Valid" ;
VAL_ 426 CrnkShftTrqMinOffCapV 1 "Invalid" 0 "Valid" ;
VAL_ 426 CrksftTqMinRunImCapV 1 "Invalid" 0 "Valid" ;
VAL_ 405 EngDistFuelMdDefltd 1 "true" 0 "false" ;
VAL_ 405 EngInjEnbldD 1 "true" 0 "false" ;
VAL_ 405 EngInjEnbldC 1 "true" 0 "false" ;
VAL_ 405 EngInjEnbldB 1 "true" 0 "false" ;
VAL_ 405 EngInjEnbldA 1 "true" 0 "false" ;
VAL_ 405 ThrPosV 1 "Invalid" 0 "Valid" ;
VAL_ 405 MassAirFloV 1 "Invalid" 0 "Valid" ;
VAL_ 405 EngManfldAbsPrsERV 1 "Invalid" 0 "Valid" ;
VAL_ 442 CrksftTqMinImCapV 1 "Invalid" 0 "Valid" ;
VAL_ 442 CrksftMaxTrqLmtV 1 "Invalid" 0 "Valid" ;
VAL_ 1417 ETC_EngOpMd 1 "Half Cylinders" 0 "All cylinders" ;
SIG_GROUP_ 292 AutoVehMdCmd 1 : AVMC_MdReqstd AVMC_MdFtrEnbld;
SIG_GROUP_ 430 TransCltchFltStat 1 : TCFS_Cltch5FltStat TCFS_Cltch4FltStat TCFS_Cltch3FltStat TCFS_Cltch2FltStat TCFS_Cltch1FltStat;
SIG_GROUP_ 429 TrnsCltchEstTorq 1 : TCET_Cltch5 TCET_Cltch4 TCET_Cltch3 TCET_Cltch2 TCET_Cltch1;
SIG_GROUP_ 399 TrnsPrkSysDiagCrtFlt 1 : TPSDCF_TrnsPrkSysOOPrkDiaCrtFlt TPSDCF_TrnsPrkSysPrkDiaCrtFlt;
SIG_GROUP_ 399 TrnsPrkSysDiagLmtdFlt 1 : TPSDLF_TrnsPrkSysOOPrkDiaLmtdFlt TPSDLF_TrnsPrkSysPrkDiaLmtdFlt;
SIG_GROUP_ 423 TransCltchFltStat 1 : TCFS_Cltch5FltStat TCFS_Cltch4FltStat TCFS_Cltch3FltStat TCFS_Cltch2FltStat TCFS_Cltch1FltStat;
SIG_GROUP_ 423 TransCltchAvlbltyStat 1 : TCAS_Cltch5AvlbltyStat TCAS_Cltch4AvlbltyStat TCAS_Cltch3AvlbltyStat TCAS_Cltch2AvlbltyStat TCAS_Cltch1AvlbltyStat;
SIG_GROUP_ 1919 DTCInfo_77F 1 : DTCI_DTCFaultType_77F DTCI_CodeSupported_77F DTCI_CurrentStatus_77F DTCI_TstNPsdCdClrdSt_77F DTCI_TstFldCdClrdStat_77F DTCI_HistStat_77F DTCI_TstNPsdPwrUpSt_77F DTCI_TstFldPwrUpSt_77F DTCI_WrnIndRqdSt_77F DTCI_DTCFailType_77F DTCI_DTCNumber_77F DTCI_DTCSource_77F DTCI_DTCTriggered_77F DTCIUnused7_77F DTCIUnused6_77F DTCIUnused5_77F DTCIUnused4_77F DTCIUnused3_77F DTCIUnused2_77F DTCIUnused1_77F;
SIG_GROUP_ 1914 DTCInfo_77A 1 : DTCI_DTCFaultType_77A DTCI_CodeSupported_77A DTCI_CurrentStatus_77A DTCI_TstNPsdCdClrdSt_77A DTCI_TstFldCdClrdStat_77A DTCI_HistStat_77A DTCI_TstNPsdPwrUpSt_77A DTCI_TstFldPwrUpSt_77A DTCI_WrnIndRqdSt_77A DTCI_DTCFailType_77A DTCI_DTCNumber_77A DTCI_DTCSource_77A DTCI_DTCTriggered_77A DTCIUnused7_77A DTCIUnused6_77A DTCIUnused5_77A DTCIUnused4_77A DTCIUnused3_77A DTCIUnused2_77A DTCIUnused1_77A;
SIG_GROUP_ 1912 DTCInfo_778 1 : DTCI_DTCFaultType_778 DTCI_CodeSupported_778 DTCI_CurrentStatus_778 DTCI_TstNPsdCdClrdSt_778 DTCI_TstFldCdClrdStat_778 DTCI_HistStat_778 DTCI_TstNPsdPwrUpSt_778 DTCI_TstFldPwrUpSt_778 DTCI_WrnIndRqdSt_778 DTCI_DTCFailType_778 DTCI_DTCNumber_778 DTCI_DTCSource_778 DTCI_DTCTriggered_778 DTCIUnused7_778 DTCIUnused6_778 DTCIUnused5_778 DTCIUnused4_778 DTCIUnused3_778 DTCIUnused2_778 DTCIUnused1_778;
SIG_GROUP_ 390 HybEngStStpInfo 1 : HESSI_EngStrtTyp HESSI_EngStrtStpMd;
SIG_GROUP_ 418 SecTrnGrRatInfo 1 : STGRI_SecTrnGrRatV STGRI_SecTrnGrRat STGRI_TransGrRatSt;
SIG_GROUP_ 418 SecTransEstGearInfo 1 : STEGI_SecTransEstGearV STEGI_SecTransEstGear;
SIG_GROUP_ 1236 CGMSrlDatCalIdInfo 1 : CGMSDCII_DataVal CGMSDCII_DataIndx CGMSDCII_DataStat;
SIG_GROUP_ 1236 CGMRoutCalIdInfo 1 : CGMRCII_DataVal CGMRCII_DataIndx CGMRCII_DataStat;
SIG_GROUP_ 1236 CGMOBDCalIdInfo 1 : CGMOCII_DataVal CGMOCII_DataIndx CGMOCII_DataStat;
SIG_GROUP_ 1236 CGMSwIdInfo 1 : CGMSII_DataVal CGMSII_DataIndx CGMSII_DataStat;
SIG_GROUP_ 422 DuTrkPlsWdtCrnkPrmSt 1 : DTPWCPS_CrnkPrmV DTPWCPS_CrnkPrm;
SIG_GROUP_ 393 TrnsImDrlCrnksftTrqRq 1 : TIDCTR_TrqIntvTyp TIDCTR_TrqReqVal TIDCTR_TrqRespTyp;
SIG_GROUP_ 393 TrnsPrdCrkshftTrqRq 1 : TPCTR_TorqReqVal TPCTR_TrqIntrvnTyp;
SIG_GROUP_ 719 RrVrtlBmpAxlTrqCmd 1 : RVBATC_AxlTrqRqstAct RVBATC_AxlTrqRqst;
SIG_GROUP_ 717 ColPrSysAxlTrqCmd 1 : CPSATC_AxlTrqRqstAct CPSATC_AxlTrqRqst;
SIG_GROUP_ 409 TransTorqReqLngTrm 1 : TTRLT_TorqReqVal TTRLT_TqRdnRlznSgg TTRLT_TorqInvntnTyp;
SIG_GROUP_ 409 TransTorqReqShrtTrm 1 : TTRST_TorqReqVal TTRST_TorqInvntnTyp;
SIG_GROUP_ 558 CmpDataPkt 1 : CDP_HVDevShtdnCdARCSt CDP_CmpSpdReqARCSt CDP_CmpLossCommOcc CDP_CmpWkUp CDP_CmpRunCrnk;
SIG_GROUP_ 558 CmpDevStPkt 1 : CDSP_CmpOvrTmpSt CDSP_CmpHVAbnrlOrVltSt CDSP_CmpHVUndrVltgSt CDSP_CmpHVOvrVltgSt CDSP_CmpHVOvrCrntSt CDSP_OvrTempWrnInd CDSP_CmpDgrdOp CDSP_CmpIntShdwnFltSt CDSP_CmpIntRecblFltSt CDSP_CmpOpOvrldSt CDSP_CmpDrCrctFltSt CDSP_CmpMtrPerfFltSt CDSP_CmpEEPROMFltSt CDSP_CmpROMFltSt CDSP_CmpRAMFltSt;
SIG_GROUP_ 558 CmpSnsrStPkt 1 : CSSP_CmpIGBTTpOtRgLSt CSSP_CmpIGBTTpOtRgHSt CSSP_CmpCPUTmpOtRgLSt CSSP_CmpCPUTmpOtRgHSt CSSP_CmpHVSnsOtRgLSt CSSP_CmpHVSnsOtRgHSt CSSP_CmpPhCrntOtRgLSt CSSP_CmpPhCrntOtRgHSt;
SIG_GROUP_ 550 ACCModCalIdInf 1 : ACCMCII_DtBtG ACCMCII_DtBtF ACCMCII_DtBtE ACCMCII_DtBtD ACCMCII_DtBtC ACCMCII_DtBtB ACCMCII_DtBtA ACCMCII_SeqNum ACCMCII_Index ACCMCII_DatStat;
SIG_GROUP_ 730 PlatAnlgMdSw 1 : PAMS_DrvMdSwStck PAMS_Sw4Stck PAMS_Sw3Stck PAMS_Sw2Stck PAMS_Sw1Stck PAMS_SwStat;
SIG_GROUP_ 458 DrRqdAxleTrq 1 : DRAT_TrqIncr DRAT_TrqVal;
SIG_GROUP_ 426 EngVarTrqCapStat 1 : EVTCS_CmdTrqCapMd EVTCS_CrntTrqCapMd;
SIG_GROUP_ 1417 EngTorqCapblty 1 : ETC_MinTorq ETC_MinRunTorq ETC_MaxTorq ETC_RefEngSpd ETC_UnsdRsrvd ETC_FrmCntr ETC_EngOpMd;
